VERSION "created by canmatrix"

NS_ :

BS_:

BU_: MGW FVC

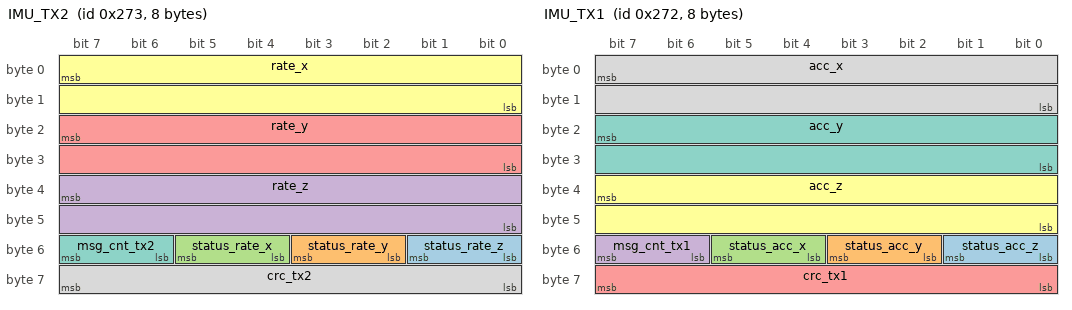
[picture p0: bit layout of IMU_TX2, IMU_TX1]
BO_ 627 IMU_TX2: 8 MGW
 SG_ status_rate_z : 49|2@0+ (1,0) [0|3] ""  FVC
 SG_ status_rate_y : 51|2@0+ (1,0) [0|3] ""  FVC
 SG_ status_rate_x : 53|2@0+ (1,0) [0|3] ""  FVC
 SG_ rate_z : 39|16@0- (0.01,0) [-327.68|327.67] "°/s"  FVC
 SG_ rate_y : 23|16@0- (0.01,0) [-327.68|327.67] "°/s"  FVC
 SG_ rate_x : 7|16@0- (0.01,0) [-327.68|327.67] "°/s"  FVC
 SG_ msg_cnt_tx2 : 55|2@0+ (1,0) [0|3] ""  FVC
 SG_ crc_tx2 : 63|8@0+ (1,0) [0|255] ""  FVC

BO_ 626 IMU_TX1: 8 MGW
 SG_ status_acc_z : 49|2@0+ (1,0) [0|3] ""  FVC
 SG_ status_acc_y : 51|2@0+ (1,0) [0|3] ""  FVC
 SG_ status_acc_x : 53|2@0+ (1,0) [0|3] ""  FVC
 SG_ msg_cnt_tx1 : 55|2@0+ (1,0) [0|3] ""  FVC
 SG_ crc_tx1 : 63|8@0+ (1,0) [0|255] ""  FVC
 SG_ acc_z : 39|16@0- (0.0002,0) [-6.5536|6.5534] "g"  FVC
 SG_ acc_y : 23|16@0- (0.0002,0) [-6.5536|6.5536] "g"  FVC
 SG_ acc_x : 7|16@0- (0.0002,0) [-6.5536|6.5534] "g"  FVC

BO_ 992 Commit_id: 8 FVC
 SG_ CommitShortId : 0|64@1+ (1,0) [0|1.84467440737096E+19] ""  MGW

BO_ 1983 DBC_Version: 2 MGW
 SG_ DBC_VersionIdMinor : 8|8@1+ (1,0) [0|255] ""  FVC
 SG_ DBC_VersionIdMajor : 0|8@1+ (1,0) [0|255] ""  FVC

BO_ 446 IPMA_UN_SP_GW_1: 8 FVC
 SG_ CameraStatus : 58|3@0+ (1,0) [0|7] ""  MGW

BO_ 18 ABS_UN_PR_11: 8 MGW
 SG_ ABSMode : 41|1@0+ (1,0) [0|1] ""  FVC
 SG_ DSCActivityStatus : 55|1@0+ (1,0) [0|1] ""  FVC
 SG_ TCSSwitchSports : 49|2@0+ (1,0) [0|3] ""  FVC
 SG_ TractionControlActive : 54|1@0+ (1,0) [0|1] ""  FVC
 SG_ TractionControlFault : 53|1@0+ (1,0) [0|1] ""  FVC
 SG_ YawControlFault : 51|1@0+ (1,0) [0|1] ""  FVC

BO_ 11 ABS_UN_PR_4: 8 MGW
 SG_ ABSFault : 36|1@0+ (1,0) [0|1] ""  FVC
 SG_ YawRate : 33|10@0+ (0.2,-100) [-100|100] "Degrees/second"  FVC

BO_ 264 ABS_UN_PR_6: 8 MGW
 SG_ GSAPosStatus : 43|4@0+ (1,0) [0|15] ""  FVC

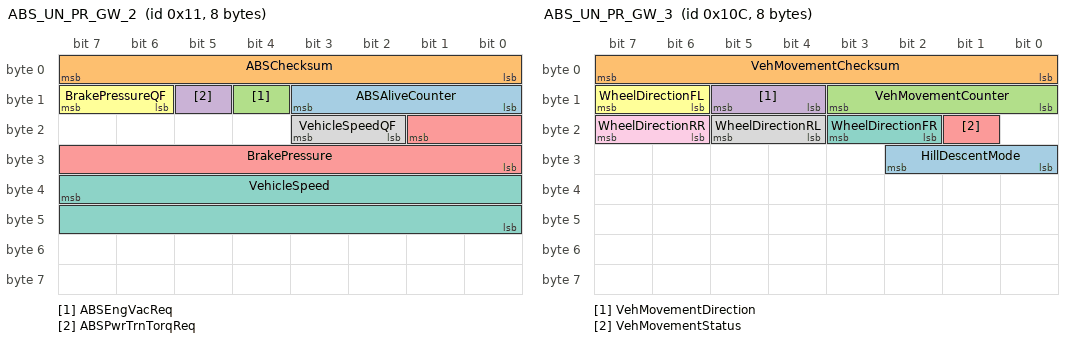
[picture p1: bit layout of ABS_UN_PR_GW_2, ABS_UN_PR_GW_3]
BO_ 17 ABS_UN_PR_GW_2: 8 MGW
 SG_ ABSAliveCounter : 11|4@0+ (1,0) [0|15] "Counter value"  FVC
 SG_ ABSChecksum : 7|8@0+ (1,0) [0|255] "checksum"  FVC
 SG_ ABSEngVacReq : 12|1@0+ (1,0) [0|1] ""  FVC
 SG_ ABSPwrTrnTorqReq : 13|1@0+ (1,0) [0|1] ""  FVC
 SG_ BrakePressure : 17|10@0+ (0.2,0) [0|204.6] "Bar"  FVC
 SG_ BrakePressureQF : 15|2@0+ (1,0) [0|3] ""  FVC
 SG_ VehicleSpeed : 39|16@0+ (0.01,0) [0|320] "kph"  FVC
 SG_ VehicleSpeedQF : 19|2@0+ (1,0) [0|3] ""  FVC

BO_ 268 ABS_UN_PR_GW_3: 8 MGW
 SG_ HillDescentMode : 26|3@0+ (1,0) [0|7] ""  FVC
 SG_ VehMovementChecksum : 7|8@0+ (1,0) [0|255] "checksum"  FVC
 SG_ VehMovementCounter : 11|4@0+ (1,0) [0|15] "Counter value"  FVC
 SG_ VehMovementDirection : 13|2@0+ (1,0) [0|3] ""  FVC
 SG_ VehMovementStatus : 17|1@0+ (1,0) [0|1] ""  FVC
 SG_ WheelDirectionFL : 15|2@0+ (1,0) [0|3] ""  FVC
 SG_ WheelDirectionFR : 19|2@0+ (1,0) [0|3] ""  FVC
 SG_ WheelDirectionRL : 21|2@0+ (1,0) [0|3] ""  FVC
 SG_ WheelDirectionRR : 23|2@0+ (1,0) [0|3] ""  FVC

BO_ 237 ABS_UN_PR_GW_5_1: 8 MGW
 SG_ WheelSpeedFrGpCounter : 11|4@0+ (1,0) [0|15] "Counter value"  FVC
 SG_ WheelSpeedFrGpCS : 7|8@0+ (1,0) [0|255] "checksum"  FVC
 SG_ WheelSpeedFrL : 22|15@0+ (0.01,0) [0|327.67] "km/h"  FVC
 SG_ WheelSpeedFrLQF : 15|2@0+ (1,0) [0|3] ""  FVC
 SG_ WheelSpeedFrR : 38|15@0+ (0.01,0) [0|327.67] "km/h"  FVC
 SG_ WheelSpeedFrRQF : 13|2@0+ (1,0) [0|3] ""  FVC

BO_ 240 ABS_UN_PR_GW_5_2: 8 MGW
 SG_ WheelSpeedReGpCounter : 11|4@0+ (1,0) [0|15] "Counter value"  FVC
 SG_ WheelSpeedReGpCS : 7|8@0+ (1,0) [0|255] "checksum"  FVC
 SG_ WheelSpeedReL : 22|15@0+ (0.01,0) [0|327.67] "km/h"  FVC
 SG_ WheelSpeedReLQF : 13|2@0+ (1,0) [0|3] ""  FVC
 SG_ WheelSpeedReR : 38|15@0+ (0.01,0) [0|327.67] "km/h"  FVC
 SG_ WheelSpeedReRQF : 15|2@0+ (1,0) [0|3] ""  FVC

BO_ 681 BCM_PR_GW_16_UN: 8 MGW
 SG_ UserSetTimeDate : 23|48@0+ (1,0) [0|281474976710655] ""  FVC

BO_ 255 BCM_PR_GW_1_UN: 8 MGW
 SG_ CarMode : 27|4@0+ (1,0) [0|15] ""  FVC
 SG_ DirectionIndicationSwitch : 47|3@0+ (1,0) [0|7] ""  FVC
 SG_ MainBeamIndication : 51|1@0+ (1,0) [0|1] ""  FVC
 SG_ PowerMode : 20|5@0+ (1,0) [0|31] ""  FVC
 SG_ PowerMode_UB : 34|1@0+ (1,0) [0|1] ""  FVC
 SG_ RunningStandby : 56|1@0+ (1,0) [0|1] ""  FVC

BO_ 230 BCM_SP_GW_2_UN: 8 MGW
 SG_ DirectionIndication : 60|2@0+ (1,0) [0|3] ""  FVC
 SG_ DirectionIndication_UB : 48|1@0+ (1,0) [0|1] ""  FVC
 SG_ LDWSwitchReq : 34|1@0+ (1,0) [0|1] ""  FVC
 SG_ LDWSwitchReq_UB : 35|1@0+ (1,0) [0|1] ""  FVC
 SG_ LowBeamIndication : 53|1@0+ (1,0) [0|1] ""  FVC
 SG_ LowBeamIndication_UB : 52|1@0+ (1,0) [0|1] ""  FVC

BO_ 270 CHCM_FR_PR_GW_2_UN: 8 MGW
 SG_ SuspensionHeightFL : 0|9@0+ (1,-200) [-200|300] "mm"  FVC
 SG_ SuspensionHeightFR : 16|9@0+ (1,-200) [-200|300] "mm"  FVC
 SG_ SuspensionHeightRL : 32|9@0+ (1,-200) [-200|300] "mm"  FVC
 SG_ SuspensionHeightRR : 48|9@0+ (1,-200) [-200|300] "mm"  FVC

BO_ 43 CHCM_FR_PR_GW_3_UN: 8 MGW
 SG_ AIR_ControlStatus : 63|2@0+ (1,0) [0|3] ""  FVC
 SG_ AIR_SuspensionMode : 61|3@0+ (1,0) [0|7] ""  FVC

BO_ 88 DADCA_FR_PR_GW_4_UN: 8 MGW
 SG_ TSRCountry : 31|7@0+ (1,0) [0|127] ""  FVC
 SG_ TSRHandOfTraffic : 45|2@0+ (1,0) [0|3] ""  FVC

BO_ 266 DADCA_UN_PR_3: 8 MGW
 SG_ DADCFuncStatus : 50|3@0+ (1,0) [0|7] ""  FVC

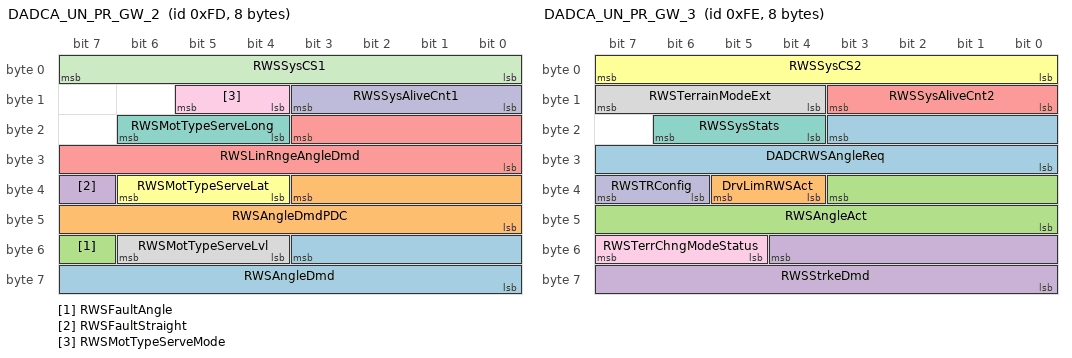
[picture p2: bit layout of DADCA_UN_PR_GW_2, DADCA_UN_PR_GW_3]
BO_ 253 DADCA_UN_PR_GW_2: 8 MGW
 SG_ RWSAngleDmd : 51|12@0+ (0.01,-15) [-15|15] "deg"  FVC
 SG_ RWSAngleDmdPDC : 35|12@0+ (0.01,-15) [-15|15] "deg"  FVC
 SG_ RWSFaultAngle : 55|1@0+ (1,0) [0|1] ""  FVC
 SG_ RWSFaultStraight : 39|1@0+ (1,0) [0|1] ""  FVC
 SG_ RWSLinRngeAngleDmd : 19|12@0+ (0.01,-15) [-15|15] "deg"  FVC
 SG_ RWSMotTypeServeLat : 38|3@0+ (1,0) [0|7] ""  FVC
 SG_ RWSMotTypeServeLong : 22|3@0+ (1,0) [0|7] ""  FVC
 SG_ RWSMotTypeServeLvl : 54|3@0+ (1,0) [0|7] ""  FVC
 SG_ RWSMotTypeServeMode : 13|2@0+ (1,0) [0|3] ""  FVC
 SG_ RWSSysAliveCnt1 : 11|4@0+ (1,0) [0|15] "Counter value"  FVC
 SG_ RWSSysCS1 : 7|8@0+ (1,0) [0|255] "checksum"  FVC

BO_ 254 DADCA_UN_PR_GW_3: 8 MGW
 SG_ DADCRWSAngleReq : 19|12@0+ (0.01,-15) [-15|15] "deg"  FVC
 SG_ DrvLimRWSAct : 37|2@0+ (1,0) [0|3] ""  FVC
 SG_ RWSAngleAct : 35|12@0+ (0.01,-15) [-15|15] "deg"  FVC
 SG_ RWSStrkeDmd : 52|13@0+ (0.01,-40) [-40|40] "mm"  FVC
 SG_ RWSSysAliveCnt2 : 11|4@0+ (1,0) [0|15] "Counter value"  FVC
 SG_ RWSSysCS2 : 7|8@0+ (1,0) [0|255] "checksum"  FVC
 SG_ RWSSysStats : 22|3@0+ (1,0) [0|7] ""  FVC
 SG_ RWSTerrainModeExt : 15|4@0+ (1,0) [0|15] ""  FVC
 SG_ RWSTerrChngModeStatus : 55|3@0+ (1,0) [0|7] ""  FVC
 SG_ RWSTRConfig : 39|2@0+ (1,0) [0|3] ""  FVC

BO_ 416 DADCA_UN_SP_5: 8 MGW
 SG_ CustomerSymptomIPMA : 48|1@0+ (1,0) [0|1] ""  FVC
 SG_ CustomerSymptomIPMA_UB : 49|1@0+ (1,0) [0|1] ""  FVC

BO_ 277 GWM_UN_PR_1: 8 MGW
 SG_ TerrainModeReqExt : 63|4@0+ (1,0) [0|15] ""  FVC

BO_ 104 HCMA_PR_1: 8 MGW
 SG_ HBSeg0LT : 57|2@0+ (1,0) [0|3] ""  FVC
 SG_ HBSeg0RT : 59|2@0+ (1,0) [0|3] ""  FVC
 SG_ HBSeg1LT : 61|2@0+ (1,0) [0|3] ""  FVC
 SG_ HBSeg1RT : 63|2@0+ (1,0) [0|3] ""  FVC
 SG_ HBSeg2LT : 49|2@0+ (1,0) [0|3] ""  FVC
 SG_ HBSeg2RT : 51|2@0+ (1,0) [0|3] ""  FVC
 SG_ HBSeg3LT : 53|2@0+ (1,0) [0|3] ""  FVC
 SG_ HBSeg3RT : 55|2@0+ (1,0) [0|3] ""  FVC
 SG_ HBSeg4LT : 41|2@0+ (1,0) [0|3] ""  FVC
 SG_ HBSeg4RT : 43|2@0+ (1,0) [0|3] ""  FVC
 SG_ HBSeg5LT : 45|2@0+ (1,0) [0|3] ""  FVC
 SG_ HBSeg5RT : 47|2@0+ (1,0) [0|3] ""  FVC
 SG_ HBSeg6LT : 33|2@0+ (1,0) [0|3] ""  FVC
 SG_ HBSeg6RT : 35|2@0+ (1,0) [0|3] ""  FVC
 SG_ HBSeg7LT : 37|2@0+ (1,0) [0|3] ""  FVC
 SG_ HBSeg7RT : 39|2@0+ (1,0) [0|3] ""  FVC
 SG_ HBSeg8LT : 25|2@0+ (1,0) [0|3] ""  FVC
 SG_ HBSeg8RT : 27|2@0+ (1,0) [0|3] ""  FVC
 SG_ HBSeg9LT : 29|2@0+ (1,0) [0|3] ""  FVC
 SG_ HBSeg9RT : 31|2@0+ (1,0) [0|3] ""  FVC
 SG_ HighBeamStatus : 19|4@0+ (1,0) [0|15] ""  FVC
 SG_ LowBeamStatus : 23|4@0+ (1,0) [0|15] ""  FVC

BO_ 106 HCMA_PR_2: 8 MGW
 SG_ ADBHorEdgeLT : 55|16@0+ (0.1,-30) [-30|30] "degrees"  FVC
 SG_ ADBHorEdgeRT : 39|16@0+ (0.1,-30) [-30|30] "degrees"  FVC
 SG_ LaserStatus : 27|4@0+ (1,0) [4|14] "unused"  FVC
 SG_ LBStatus : 31|4@0+ (1,0) [4|13] "Unused"  FVC
 SG_ LightDist : 19|4@0+ (1,0) [5|13] "Unused"  FVC

BO_ 301 HCMB_PR_1: 8 MGW
 SG_ AFSLightDist_b : 59|4@0+ (1,0) [0|15] ""  FVC
 SG_ AFSPHBAngleLT_b : 47|16@0+ (0.1,-30) [-30|10] "-ve left , +ve right"  FVC
 SG_ AFSPHBAngleRT_b : 31|16@0+ (0.1,-30) [-30|10] "-ve left , +ve right"  FVC
 SG_ AFSStatus_b : 63|4@0+ (1,0) [0|15] ""  FVC
 SG_ LaserStatus_b : 19|4@0+ (1,0) [0|15] ""  FVC

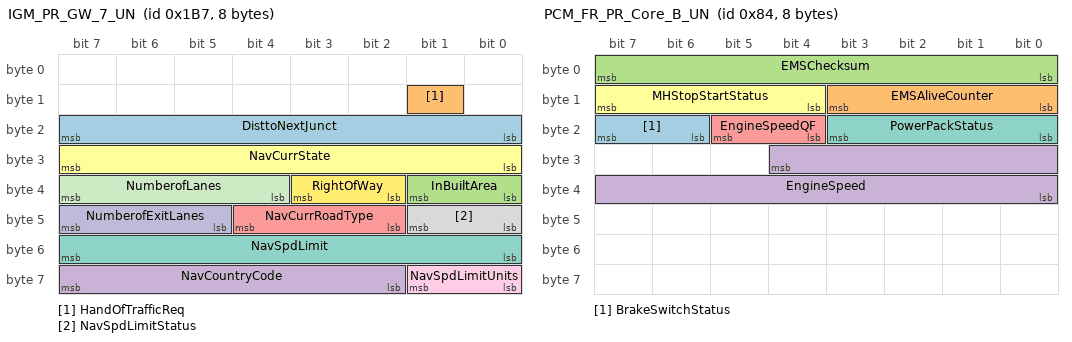
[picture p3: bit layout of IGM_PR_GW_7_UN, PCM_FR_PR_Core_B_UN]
BO_ 439 IGM_PR_GW_7_UN: 8 MGW
 SG_ DisttoNextJunct : 23|8@0+ (0.1,0) [0.1|25.4] ""  FVC
 SG_ HandOfTrafficReq : 9|1@0+ (1,0) [0|1] ""  FVC
 SG_ InBuiltArea : 33|2@0+ (1,0) [0|3] ""  FVC
 SG_ NavCountryCode : 63|6@0+ (1,0) [52|62] "Reserved"  FVC
 SG_ NavCurrRoadType : 44|3@0+ (1,0) [6|7] "Not used"  FVC
 SG_ NavCurrState : 31|8@0+ (1,0) [77|255] "Not used"  FVC
 SG_ NavSpdLimit : 55|8@0+ (1,0) [0|254] "Speed Value"  FVC
 SG_ NavSpdLimitStatus : 41|2@0+ (1,0) [0|3] ""  FVC
 SG_ NavSpdLimitUnits : 57|2@0+ (1,0) [0|3] ""  FVC
 SG_ NumberofExitLanes : 47|3@0+ (1,0) [1|7] "Number of lanes"  FVC
 SG_ NumberofLanes : 39|4@0+ (1,0) [1|15] "Number of lanes"  FVC
 SG_ RightOfWay : 35|2@0+ (1,0) [0|3] ""  FVC

BO_ 186 IGM_SP_GW_10_UN: 8 MGW
 SG_ AutoHighBeamSAEModeReq : 51|2@0+ (1,0) [0|3] ""  FVC
 SG_ AutoHighBeamSAEModeReq_UB : 57|1@0+ (1,0) [0|1] ""  FVC

BO_ 318 IPC_PR_GW_5_UN: 8 MGW
 SG_ IPCAliveCnt : 11|4@0+ (1,0) [0|15] "Counter"  FVC

BO_ 515 LHSWS_PR_GW_1_UN: 8 MGW
 SG_ JoypadDownBtnStatus : 63|4@0+ (1,0) [0|15] "Rolling Count (See Encoding Desc"  FVC
 SG_ JoypadLeftBtnStatus : 59|4@0+ (1,0) [0|15] "Rolling Count (See Encoding Desc"  FVC
 SG_ JoypadOKBtnStatus : 55|4@0+ (1,0) [0|15] "Rolling Count (See Encoding Desc"  FVC
 SG_ JoypadRightBtnStatus : 51|4@0+ (1,0) [0|15] "Rolling Count (See Encoding Desc"  FVC
 SG_ JoypadUpBtnStatus : 43|4@0+ (1,0) [0|15] "Rolling Count (See Encoding Desc"  FVC

BO_ 132 PCM_FR_PR_Core_B_UN: 8 MGW
 SG_ BrakeSwitchStatus : 23|2@0+ (1,0) [0|3] ""  FVC
 SG_ EMSAliveCounter : 11|4@0+ (1,0) [0|15] "Counter value"  FVC
 SG_ EMSChecksum : 7|8@0+ (1,0) [0|255] "checksum"  FVC
 SG_ EngineSpeed : 28|13@0+ (1,0) [0|8191] "RPM"  FVC
 SG_ EngineSpeedQF : 21|2@0+ (1,0) [0|3] ""  FVC
 SG_ MHStopStartStatus : 15|4@0+ (1,0) [0|15] ""  FVC
 SG_ PowerPackStatus : 19|4@0+ (1,0) [0|15] ""  FVC

BO_ 54 PCM_FR_PR_PedalPos_UN: 8 MGW
 SG_ PedalPosPro : 23|8@0+ (0.5,0) [0|100] "%"  FVC
 SG_ PedalPosProAliveCounter : 11|4@0+ (1,0) [0|15] "Counter value"  FVC
 SG_ PedalPosProChecksum : 7|8@0+ (1,0) [0|255] "checksum"  FVC
 SG_ PedalPosProQF : 13|2@0+ (1,0) [0|3] ""  FVC

BO_ 13 PCM_FR_PR_WhlTorqTgt_UN: 8 MGW
 SG_ VSCHoldRequest : 21|1@0+ (1,0) [0|1] ""  FVC
 SG_ WheelTorqTgtGpCounter : 11|4@0+ (1,0) [0|15] "Counter value"  FVC
 SG_ WheelTorqTgtGpCS : 7|8@0+ (1,0) [0|255] "checksum"  FVC
 SG_ WheelTorqTgtWoIntF : 20|13@0+ (10,-10000) [-10000|71910] "Nm"  FVC
 SG_ WheelTorqTgtWoIntR : 36|13@0+ (10,-10000) [-10000|71910] "Nm"  FVC

BO_ 46 PSCM_FR_PR_GW_1_UN: 4 MGW
 SG_ EPASDrvDmdExcess_dup : 15|1@0+ (1,0) [0|1] ""  FVC
 SG_ TorsionBarTorque : 17|10@0+ (0.02,0) [0|20.44] "0-3FCh :0..+20.40 Nm, E=N*0.02+0"  FVC
 SG_ TorsionBarTorqueCS : 7|8@0+ (1,0) [0|255] "checksum"  FVC
 SG_ TorsionBarTorqueCtr : 11|4@0+ (1,0) [0|15] "Counter value"  FVC
 SG_ TorsionBarTorqueQF : 13|2@0+ (1,0) [0|3] ""  FVC
 SG_ TorsionBarTorqueSign : 14|1@0+ (1,0) [0|1] ""  FVC

BO_ 50 PSCM_FR_PR_GW_2_UN: 8 MGW
 SG_ ActRoadWheelAngleAC : 11|4@0+ (1,0) [0|15] "Counter value"  FVC
 SG_ ActRoadWheelAngleCS : 7|8@0+ (1,0) [0|255] "checksum"  FVC
 SG_ ActRoadWheelAngState : 15|2@0+ (1,0) [0|3] ""  FVC
 SG_ ActRoadWheelAngValue : 22|15@0+ (0.005,-45) [-45|45] "Degrees"  FVC

BO_ 191 RCM_FR_PR_GW_1_UN: 8 MGW
 SG_ DrivSeatBeltBcklError : 30|1@0+ (1,0) [0|1] ""  FVC
 SG_ DrivSeatBeltBcklState : 31|1@0+ (1,0) [0|1] ""  FVC

BO_ 74 RCM_FR_PR_TXID1_UN: 8 MGW
 SG_ A1 : 39|16@0+ (0.00125,-40.96) [-40.96|40.9575] "m/s2"  FVC
 SG_ A1_STAT : 31|4@0+ (1,0) [0|15] ""  FVC
 SG_ CLU_STAT : 27|4@0+ (1,0) [0|15] ""  FVC
 SG_ CRC1 : 7|8@0+ (1,0) [0|255] "checksum"  FVC
 SG_ MSG_CNT1 : 11|4@0+ (1,0) [0|15] "Counter value"  FVC
 SG_ PSIP1 : 55|16@0+ (0.005,-163.84) [-163.84|163.83] "Grad/s"  FVC
 SG_ PSIP1_STAT : 15|4@0+ (1,0) [0|15] ""  FVC

BO_ 76 RCM_FR_PR_TXID2_UN: 8 MGW
 SG_ A2 : 39|16@0+ (0.00125,-40.96) [-40.96|40.9575] "m/s2"  FVC
 SG_ A2_STAT : 31|4@0+ (1,0) [0|15] ""  FVC
 SG_ CRC2 : 7|8@0+ (1,0) [0|255] "checksum"  FVC
 SG_ MSG_CNT2 : 11|4@0+ (1,0) [0|15] "Counter value"  FVC
 SG_ PSIPP1 : 55|16@0+ (0.125,-4096) [-4096|4095.75] "Grad/s/s"  FVC
 SG_ PSIPP1_STAT : 27|4@0+ (1,0) [0|15] ""  FVC

BO_ 86 SASM_FR_GW_1_UN: 8 MGW
 SG_ SteeringWheelAngle : 31|16@0+ (0.1,-780) [-780|780] "Degrees"  FVC
 SG_ SteeringWheelAngleCS : 7|8@0+ (1,0) [0|255] "checksum"  FVC
 SG_ SteeringWheelAngleSpeed : 47|8@0+ (4,0) [0|1016] "Rotational Speed (deg/sec)"  FVC
 SG_ SteeringWheelAngleStatus : 17|2@0+ (1,0) [0|3] ""  FVC
 SG_ SteeringWheelAngMsgCnt : 11|4@0+ (1,0) [0|15] "Counter value"  FVC
 SG_ SteeringWheelRotDir : 18|1@0+ (1,0) [0|1] ""  FVC

BO_ 397 SignalGW_PR_1_UN: 8 MGW
 SG_ DemandHeight : 32|9@0+ (1,-200) [-200|300] "mm"  FVC
 SG_ EstimatedHeight : 48|9@0+ (1,-200) [-200|300] "mm"  FVC
 SG_ THETAP : 7|16@0+ (0.005,-163.84) [-163.84|163.83] "Grad/s"  FVC

BO_ 399 SignalGW_PR_3_UN: 8 MGW
 SG_ CountryCode : 23|16@0+ (1,0) [0|65535] "n/a"  FVC
 SG_ VCGStatus : 47|1@0+ (1,0) [0|1] ""  FVC

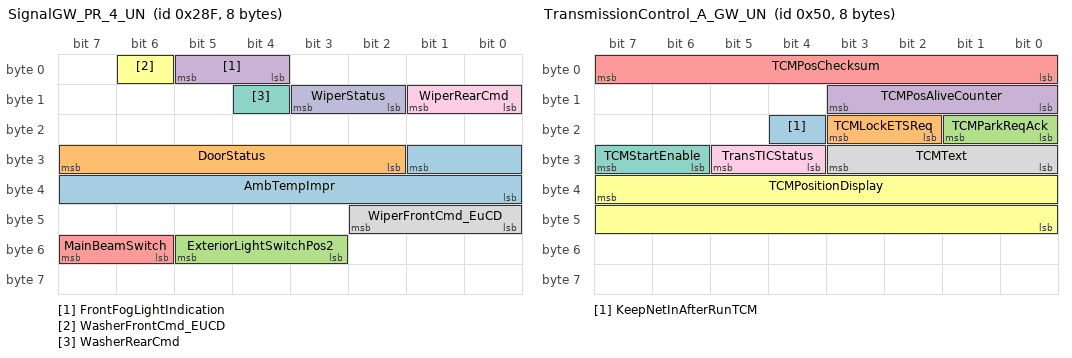
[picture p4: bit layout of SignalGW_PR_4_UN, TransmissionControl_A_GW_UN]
BO_ 655 SignalGW_PR_4_UN: 8 MGW
 SG_ AmbTempImpr : 25|10@0+ (0.25,-128) [-128|127.75] "Degrees C"  FVC
 SG_ DoorStatus : 31|6@0+ (1,0) [0|63] "See Description"  FVC
 SG_ ExteriorLightSwitchPos2 : 53|3@0+ (1,0) [5|7] "Unsed"  FVC
 SG_ FrontFogLightIndication : 5|2@0+ (1,0) [0|3] ""  FVC
 SG_ MainBeamSwitch : 55|2@0+ (1,0) [0|3] ""  FVC
 SG_ WasherFrontCmd_EUCD : 6|1@0+ (1,0) [0|1] ""  FVC
 SG_ WasherRearCmd : 12|1@0+ (1,0) [0|1] ""  FVC
 SG_ WiperFrontCmd_EuCD : 42|3@0+ (1,0) [0|7] ""  FVC
 SG_ WiperRearCmd : 9|2@0+ (1,0) [0|3] ""  FVC
 SG_ WiperStatus : 11|2@0+ (1,0) [0|3] ""  FVC

BO_ 245 SignalGW_PR_6_UN: 8 MGW
 SG_ ATPCProStatus : 27|4@0+ (1,0) [0|15] ""  FVC

BO_ 836 TPM_PR_GW_4: 8 MGW
 SG_ ActualTyrePressureFL : 23|8@0+ (2.745098,0) [0|699.99999] "kPa"  FVC
 SG_ ActualTyrePressureFR : 31|8@0+ (2.745098,0) [0|699.99999] "kPa"  FVC
 SG_ ActualTyrePressureRL : 39|8@0+ (2.745098,0) [0|699.99999] "kPa"  FVC
 SG_ ActualTyrePressureRR : 47|8@0+ (2.745098,0) [0|699.99999] "kPa"  FVC

BO_ 80 TransmissionControl_A_GW_UN: 8 MGW
 SG_ KeepNetInAfterRunTCM : 20|1@0+ (1,0) [0|1] ""  FVC
 SG_ TCMLockETSReq : 19|2@0+ (1,0) [0|3] ""  FVC
 SG_ TCMParkReqAck : 17|2@0+ (1,0) [0|3] ""  FVC
 SG_ TCMPosAliveCounter : 11|4@0+ (1,0) [0|15] "Counter value"  FVC
 SG_ TCMPosChecksum : 7|8@0+ (1,0) [0|255] "checksum"  FVC
 SG_ TCMPositionDisplay : 39|16@0+ (1,0) [0|65535] ""  FVC
 SG_ TCMStartEnable : 31|2@0+ (1,0) [0|3] ""  FVC
 SG_ TCMText : 27|4@0+ (1,0) [0|15] ""  FVC
 SG_ TransTICStatus : 29|2@0+ (1,0) [0|3] ""  FVC

BO_ 1024 VEHCONFIG_400UN_AS: 8 MGW
 SG_ CcfAdasNCapESS m101 : 61|2@0+ (1,0) [0|3] ""  FVC
 SG_ CcfParkAssistHMI m94 : 63|3@0+ (1,0) [0|7] ""  FVC
 SG_ CcfAdaptDrvBeam m91 : 51|2@0+ (1,0) [0|3] ""  FVC
 SG_ CcfDD06PowerModePKT m176 : 52|5@0+ (1,0) [0|31] ""  FVC
 SG_ CcfAllWheelSteer m112 : 55|2@0+ (1,0) [0|3] ""  FVC
 SG_ CcfDD05OutdoorTemp m177 : 47|8@0+ (1,-40) [-40|215] "Deg C"  FVC
 SG_ CcfDD02MainECUSupVolts m176 : 47|8@0+ (0.25,0) [0|63.75] "Volts"  FVC
 SG_ CcfDD04InCarTemp m177 : 39|8@0+ (1,-40) [-40|215] "Deg C"  FVC
 SG_ CcfAdapDrvBeamSeg m101 : 39|8@0+ (1,0) [0|255] ""  FVC
 SG_ CcfVINPart1 m87 : 39|32@0+ (1,0) [0|4294967295] ""  FVC
 SG_ ccfGenericWheelBase m87 : 31|4@0+ (1,0) [0|15] ""  FVC
 SG_ CcfSportbrake m85 : 31|2@0+ (1,0) [0|3] ""  FVC
 SG_ CcfSuspensionType m98 : 19|4@0+ (1,0) [0|15] ""  FVC
 SG_ CcfVehClearGuidance m115 : 23|2@0+ (1,0) [0|3] ""  FVC
 SG_ CcfAHBSensitivtyMenu m110 : 23|2@0+ (1,0) [0|3] ""  FVC
 SG_ CcfAHBCalibration m109 : 23|3@0+ (1,0) [0|7] ""  FVC
 SG_ CcfGlassType m10 : 23|8@0+ (1,0) [0|255] ""  FVC
 SG_ CcfHeatedWindscreen m9 : 23|8@0+ (1,0) [0|255] ""  FVC
 SG_ CcfHUDSubType m96 : 13|3@0+ (1,0) [0|7] ""  FVC
 SG_ CcfDD01TotalDistance m177 : 15|24@0+ (1,0) [0|16777215] ""  FVC
 SG_ CcfDD00GlobalRealTime m176 : 15|32@0+ (1,0) [0|4294967295] ""  FVC
 SG_ CcfAHBSystemStatus m108 : 15|2@0+ (1,0) [0|3] ""  FVC
 SG_ CcfVINPart3 m89 : 15|48@0+ (1,0) [0|281474976710655] ""  FVC
 SG_ CcfVINPart2 m88 : 15|56@0+ (1,0) [0|7.20575940379279E+16] ""  FVC
 SG_ CcfSteeringWheelPosn m2 : 15|8@0+ (1,0) [0|255] ""  FVC
 SG_ CcfVehicleType m1 : 15|8@0+ (1,0) [0|255] ""  FVC
 SG_ SF_VEHCONFIG_400UN_AUTOSAR_PDU M : 0|8@1+ (1,0) [0|255] ""  FVC

BO_ 1025 Snapshot_Data: 8 MGW
 SG_ Snapshot_Data_PDU_0 M : 7|8@0+ (1,0) [0|255] ""  FVC
 SG_ OutdoorTemp m1 : 47|8@0+ (1,-40) [-40|215] ""  FVC
 SG_ InCarTemp m1 : 39|8@0+ (1,-40) [-40|215] ""  FVC
 SG_ TotalDistance m1 : 15|24@0+ (1,0) [0|16777215] ""  FVC
 SG_ PowrModePKT m0 : 52|5@0+ (1,0) [0|31] ""  FVC
 SG_ MainECUSuppVolt m0 : 47|8@0+ (0.25,0) [0|63.75] ""  FVC
 SG_ GlobalRealTime m0 : 15|32@0+ (1,0) [0|4294967295] ""  FVC

BO_ 321 Vehicle_CAN_41: 8 MGW
 SG_ ADAS_Stub_PartOfCalcRoute : 47|2@0+ (1,0) [0|3] ""  FVC
 SG_ ADAS_Stub_FuncRoadClass : 34|3@0+ (1,0) [0|6] ""  FVC
 SG_ ADAS_Stub_LastStub : 63|1@0+ (1,0) [0|1] ""  FVC
 SG_ ADAS_Stub_Update : 24|1@0+ (1,0) [0|1] ""  FVC
 SG_ ADAS_Stub_SubPathIdx : 31|6@0+ (1,0) [8|63] ""  FVC
 SG_ ADAS_Stub_Retr : 25|1@0+ (1,0) [0|1] ""  FVC
 SG_ ADAS_Stub_PathIdx : 21|6@0+ (1,0) [8|63] ""  FVC
 SG_ ADAS_Stub_Offset : 4|13@0+ (1,0) [0|8190] "m"  FVC
 SG_ ADAS_Stub_NumOfLaneOppDir : 60|2@0+ (1,0) [0|3] ""  FVC
 SG_ ADAS_Stub_NumOfLaneDrvDir : 58|3@0+ (1,0) [0|7] ""  FVC
 SG_ ADAS_Stub_MsgType : 7|3@0+ (1,0) [0|7] ""  FVC
 SG_ ADAS_Stub_FormOfWay : 43|4@0+ (1,0) [0|14] ""  FVC
 SG_ ADAS_Stub_CycCnt : 23|2@0+ (1,0) [0|3] ""  FVC
 SG_ ADAS_Stub_RtOfWay : 62|2@0+ (1,0) [0|3] ""  FVC
 SG_ ADAS_Stub_CmplxInsct : 45|2@0+ (1,0) [0|3] ""  FVC
 SG_ ADAS_Stub_RelProbb : 39|5@0+ (3.333,0) [0|100] "%"  FVC
 SG_ ADAS_Stub_TurnAngl : 55|8@0+ (1.417,0) [0|358] "deg"  FVC

BO_ 340 ACC_01: 8 MGW
 SG_ AxrArbitrated : 6|9@0+ (0.024,-2.016) [-2.016|10.224] "m/s²"  FVC
 SG_ ESP_NotAvailable : 7|1@0+ (1,0) [0|1] ""  FVC

BO_ 3 GSR_ISA_CAN_TX_01: 8 FVC
 SG_ ISA_OperationState : 7|2@0+ (1,0) [0|3] ""  MGW
 SG_ ISA_SetWarningType : 5|3@0+ (1,0) [0|7] ""  MGW
 SG_ ISA_ActiveWarningType : 2|3@0+ (1,0) [0|7] ""  MGW
 SG_ ISA_SpeedLimitDeterminationState : 10|2@0+ (1,0) [0|3] ""  MGW
 SG_ ISA_SpeedLimitChangeNotification : 11|1@0+ (1,0) [0|1] ""  MGW

BO_ 2 GSR_ISA_CAN_RX_01: 8 MGW
 SG_ ISA_OUTPUT_ENABLED : 1|1@0+ (1,0) [0|1] ""  FVC
 SG_ ISA_SLWF_OUTPUT_ENABLED : 2|1@0+ (1,0) [0|1] ""  FVC
 SG_ ISA_SLWF_TYPE : 5|3@0+ (1,0) [0|7] ""  FVC
 SG_ ISA_USER_TERMINATION : 6|1@0+ (1,0) [0|1] ""  FVC
 SG_ ISA_SL_CHNG_AUDIO_FEEDBACK : 7|1@0+ (1,0) [0|1] ""  FVC

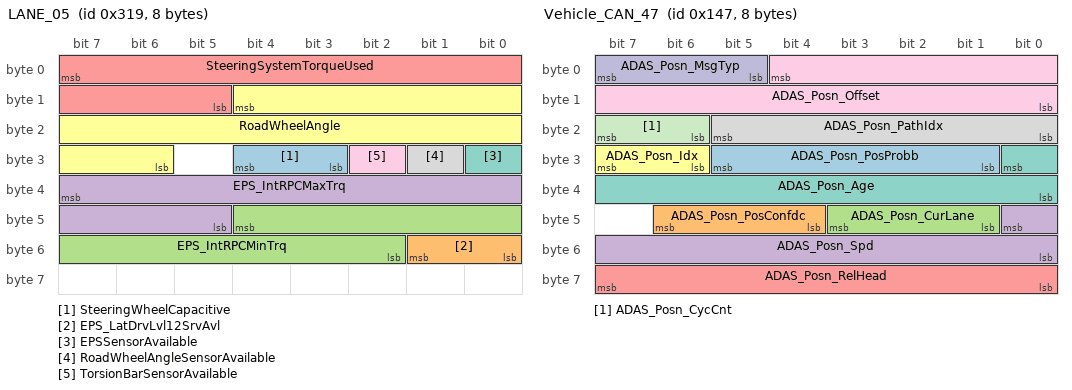
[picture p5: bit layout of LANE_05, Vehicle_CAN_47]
BO_ 793 LANE_05: 8 MGW
 SG_ SteeringWheelCapacitive : 28|2@0+ (1,0) [0|3] ""  FVC
 SG_ EPS_LatDrvLvl12SrvAvl : 49|2@0+ (1,0) [0|3] ""  FVC
 SG_ EPS_IntRPCMinTrq : 44|11@0+ (0.02,-20.48) [-20.48|20.46] "Nm"  FVC
 SG_ EPS_IntRPCMaxTrq : 39|11@0+ (0.02,-20.48) [-20.48|20.46] "Nm"  FVC
 SG_ SteeringSystemTorqueUsed : 7|11@0+ (0.01,-8) [-8|12.47] "N/m"  FVC
 SG_ RoadWheelAngle : 12|15@0+ (0.005,-81.92) [-81.92|81.915] "degree"  FVC
 SG_ EPSSensorAvailable : 24|1@0+ (1,0) [0|1] ""  FVC
 SG_ RoadWheelAngleSensorAvailable : 25|1@0+ (1,0) [0|1] ""  FVC
 SG_ TorsionBarSensorAvailable : 26|1@0+ (1,0) [0|1] ""  FVC

BO_ 323 Vehicle_CAN_43: 8 MGW
 SG_ ADAS_Seg_PartOfCalcRoute : 47|2@0+ (1,0) [0|3] ""  FVC
 SG_ ADAS_Seg_RelProbb : 39|5@0+ (3.333,0) [0|100] "%"  FVC
 SG_ ADAS_Seg_Offset : 4|13@0+ (1,0) [0|8190] "m"  FVC
 SG_ ADAS_Seg_Retr : 25|1@0+ (1,0) [0|1] ""  FVC
 SG_ ADAS_Seg_PathIdx : 21|6@0+ (1,0) [8|63] ""  FVC
 SG_ ADAS_Seg_MsgType : 7|3@0+ (1,0) [0|7] ""  FVC
 SG_ ADAS_Seg_FormOfWay : 43|4@0+ (1,0) [0|14] ""  FVC
 SG_ ADAS_Seg_CycCnt : 23|2@0+ (1,0) [0|3] ""  FVC
 SG_ ADAS_Seg_CmplxInsct : 45|2@0+ (1,0) [0|3] ""  FVC
 SG_ ADAS_Seg_BuildUpArea : 27|2@0+ (1,0) [0|3] ""  FVC
 SG_ ADAS_Seg_DividedRoad : 62|2@0+ (1,0) [0|3] ""  FVC
 SG_ ADAS_Seg_Bridge : 29|2@0+ (1,0) [0|3] ""  FVC
 SG_ ADAS_Seg_Tunnel : 31|2@0+ (1,0) [0|3] ""  FVC
 SG_ ADAS_Seg_NumOfLaneOppDir : 60|2@0+ (1,0) [0|3] ""  FVC
 SG_ ADAS_Seg_NumOfLaneDrvDir : 58|3@0+ (1,0) [0|7] ""  FVC
 SG_ ADAS_Seg_EffSpdLmtType : 50|3@0+ (1,0) [0|7] ""  FVC
 SG_ ADAS_Seg_EffSpdLmt : 55|5@0+ (1,0) [0|0] "(k)mp/h"  FVC
 SG_ ADAS_Seg_FuncRoadClass : 34|3@0+ (1,0) [0|6] ""  FVC
 SG_ ADAS_Seg_Update : 24|1@0+ (1,0) [0|1] ""  FVC

BO_ 289 Vehicle_CAN_21: 8 MGW
 SG_ AirbagCrashIntensity : 47|2@0+ (1,0) [0|3] ""  FVC
 SG_ ASR_Intervention : 55|1@0+ (1,0) [0|1] ""  FVC
 SG_ BrakePressure_Qbit : 38|1@0+ (1,0) [0|1] ""  FVC
 SG_ BrakeTemperatureStatus : 48|1@0+ (1,0) [0|1] ""  FVC
 SG_ ClutchPedal : 39|1@0+ (1,0) [0|1] ""  FVC
 SG_ ClutchTemperatureStatus : 45|2@0+ (1,0) [0|3] ""  FVC
 SG_ DecelerationEnable : 51|1@0+ (1,0) [0|1] ""  FVC
 SG_ DriverBraked_Qbit : 37|1@0+ (1,0) [0|1] ""  FVC
 SG_ EBV_Intervention : 53|1@0+ (1,0) [0|1] ""  FVC
 SG_ ECD_Failure : 50|1@0+ (1,0) [0|1] ""  FVC
 SG_ ECD_NotAvailable : 49|1@0+ (1,0) [0|1] ""  FVC
 SG_ EDS_Intervention : 54|1@0+ (1,0) [0|1] ""  FVC
 SG_ EmergencyBrakeActive : 43|1@0+ (1,0) [0|1] ""  FVC
 SG_ ESP_AutoholdActive : 42|1@0+ (1,0) [0|1] ""  FVC
 SG_ ESP_ConsistentWithACC : 32|1@0+ (1,0) [0|1] ""  FVC
 SG_ ESP_StandstillConfirmed : 41|1@0+ (1,0) [0|1] ""  FVC
 SG_ ESP_StoppingProcessActive : 40|1@0+ (1,0) [0|1] ""  FVC
 SG_ MSR_Intervention : 52|1@0+ (1,0) [0|1] ""  FVC
 SG_ NumberOfCogs : 31|8@0+ (1,0) [0|255] ""  FVC
 SG_ SteeringAngularSpeed_Qbit : 34|1@0+ (1,0) [0|1] ""  FVC
 SG_ SteeringWheelAngle_Qbit : 35|1@0+ (1,0) [0|1] ""  FVC
 SG_ Vehicle_CAN_21_Counter : 15|4@0+ (1,0) [0|15] ""  FVC
 SG_ Vehicle_CAN_21_CRC : 7|8@0+ (1,0) [0|255] ""  FVC
 SG_ Velocity_Qbit : 36|1@0+ (1,0) [0|1] ""  FVC
 SG_ WheelCircumference : 11|12@0+ (1,0) [0|4095] ""  FVC
 SG_ WheelCircumference_QBit : 33|1@0+ (1,0) [0|1] ""  FVC
 SG_ TSRFeatureEnableSwitch : 63|8@0+ (1,0) [0|255] ""  FVC

BO_ 327 Vehicle_CAN_47: 8 MGW
 SG_ ADAS_Posn_PosProbb : 29|5@0+ (3.333,0) [0|100] "%"  FVC
 SG_ ADAS_Posn_PosConfdc : 46|3@0+ (1,0) [0|7] ""  FVC
 SG_ ADAS_Posn_CurLane : 43|3@0+ (1,0) [0|7] ""  FVC
 SG_ ADAS_Posn_Spd : 40|9@0+ (0.2,-12.8) [-12.8|89.2] "m/s"  FVC
 SG_ ADAS_Posn_RelHead : 63|8@0+ (1.417,0) [0|358] "deg"  FVC
 SG_ ADAS_Posn_Idx : 31|2@0+ (1,0) [0|3] ""  FVC
 SG_ ADAS_Posn_Age : 24|9@0+ (5,0) [0|2545] "ms"  FVC
 SG_ ADAS_Posn_PathIdx : 21|6@0+ (1,0) [8|63] ""  FVC
 SG_ ADAS_Posn_Offset : 4|13@0+ (1,0) [0|8190] "m"  FVC
 SG_ ADAS_Posn_MsgTyp : 7|3@0+ (1,0) [0|7] ""  FVC
 SG_ ADAS_Posn_CycCnt : 23|2@0+ (1,0) [0|3] ""  FVC

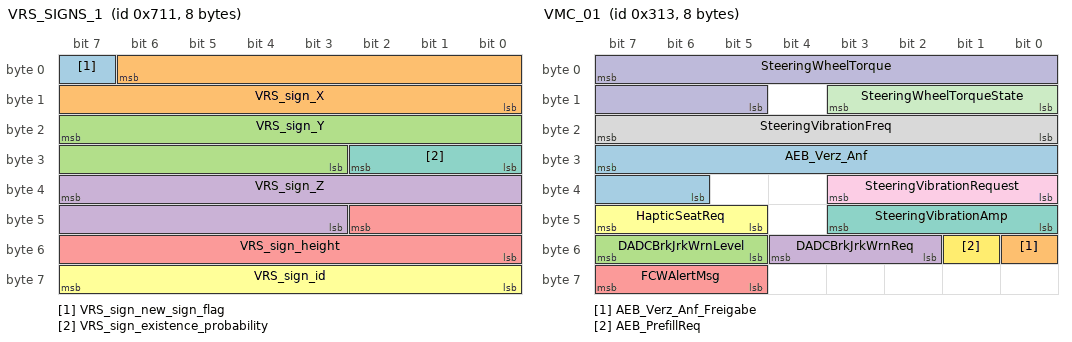
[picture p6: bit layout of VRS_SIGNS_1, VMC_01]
BO_ 1809 VRS_SIGNS_1: 8 FVC
 SG_ VRS_sign_new_sign_flag : 7|1@0+ (1,0) [0|1] ""  MGW
 SG_ VRS_sign_X : 6|15@0+ (1,0) [0|32767] "cm"  MGW
 SG_ VRS_sign_Y : 23|13@0+ (1,0) [0|8191] "cm"  MGW
 SG_ VRS_sign_Z : 39|13@0+ (1,0) [0|8191] "cm"  MGW
 SG_ VRS_sign_height : 42|11@0+ (1,0) [0|2047] ""  MGW
 SG_ VRS_sign_id : 63|8@0+ (1,0) [0|255] ""  MGW
 SG_ VRS_sign_existence_probability : 26|3@0+ (1,0) [0|7] ""  MGW

BO_ 328 Vehicle_CAN_48: 8 MGW
 SG_ isYawRate_Pf : 7|16@0+ (0.005,-163.84) [-163.84|163.835] "deg/s"  FVC
 SG_ isPitchRate : 31|16@0+ (0.005,-163.84) [-163.84|163.835] "deg/s"  FVC
 SG_ YawRate_Qbit : 16|1@0+ (1,0) [0|1] ""  FVC
 SG_ RoadWheelAngleGradients : 40|16@0+ (3.05185094759972E-05,0) [0|2.00003051850948] "rad/sec"  FVC

BO_ 787 VMC_01: 8 FVC
 SG_ AEB_Verz_Anf : 31|10@0+ (0.024,-20.016) [-20.016|4.536] "ms²"  MGW
 SG_ AEB_Verz_Anf_Freigabe : 48|1@0+ (1,0) [0|1] ""  MGW
 SG_ DADCBrkJrkWrnLevel : 55|3@0+ (1,0) [0|7] ""  MGW
 SG_ DADCBrkJrkWrnReq : 52|3@0+ (1,0) [0|7] ""  MGW
 SG_ FCWAlertMsg : 63|3@0+ (1,0) [0|7] ""  MGW
 SG_ HapticSeatReq : 47|3@0+ (1,0) [0|7] ""  MGW
 SG_ SteeringVibrationAmp : 43|4@0+ (0.2,0) [0|3] "Nm"  MGW
 SG_ SteeringVibrationFreq : 23|8@0+ (1,0) [0|30] "Hz"  MGW
 SG_ SteeringVibrationRequest : 35|4@0+ (1,0) [0|15] ""  MGW
 SG_ SteeringWheelTorque : 7|11@0+ (0.02,-20.48) [-20.48|20.48] "Nm"  MGW
 SG_ SteeringWheelTorqueState : 11|4@0+ (1,0) [0|15] ""  MGW
 SG_ AEB_PrefillReq : 49|1@0+ (1,0) [0|1] ""  MGW

BO_ 1810 VRS_SIGNS_2: 8 FVC
 SG_ VRS_sign_meaning : 7|9@0+ (1,0) [0|511] ""  MGW
 SG_ VRS_sign_width : 14|13@0+ (1,0) [0|8191] ""  MGW
 SG_ VRS_padding_2bit : 17|2@0+ (1,0) [0|3] ""  MGW

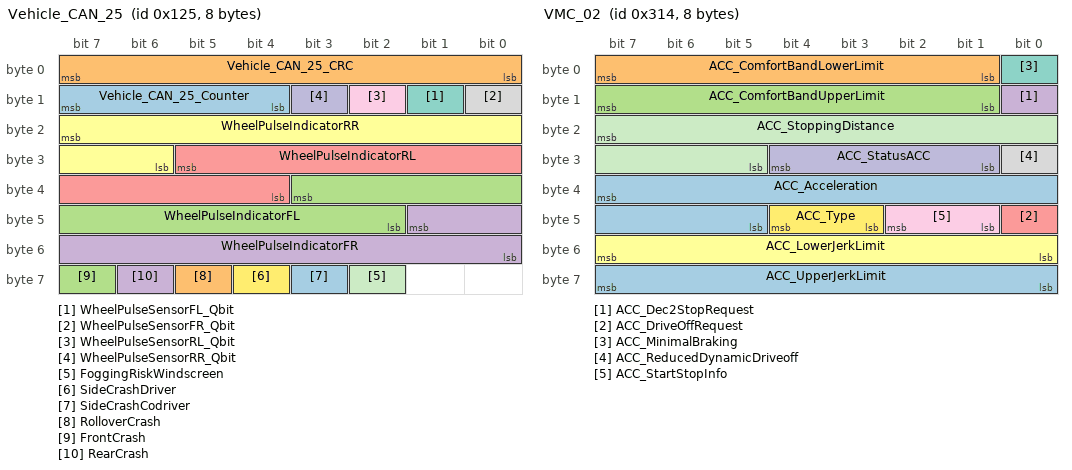
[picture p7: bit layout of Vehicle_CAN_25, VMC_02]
BO_ 293 Vehicle_CAN_25: 8 MGW
 SG_ Vehicle_CAN_25_Counter : 15|4@0+ (1,0) [0|15] ""  FVC
 SG_ Vehicle_CAN_25_CRC : 7|8@0+ (1,0) [0|255] ""  FVC
 SG_ WheelPulseIndicatorFL : 35|10@0+ (1,0) [0|1023] ""  FVC
 SG_ WheelPulseIndicatorFR : 41|10@0+ (1,0) [0|1023] ""  FVC
 SG_ WheelPulseIndicatorRL : 29|10@0+ (1,0) [0|1023] ""  FVC
 SG_ WheelPulseIndicatorRR : 23|10@0+ (1,0) [0|1023] ""  FVC
 SG_ WheelPulseSensorFL_Qbit : 9|1@0+ (1,0) [0|1] ""  FVC
 SG_ WheelPulseSensorFR_Qbit : 8|1@0+ (1,0) [0|1] ""  FVC
 SG_ WheelPulseSensorRL_Qbit : 10|1@0+ (1,0) [0|1] ""  FVC
 SG_ WheelPulseSensorRR_Qbit : 11|1@0+ (1,0) [0|1] ""  FVC
 SG_ FoggingRiskWindscreen : 58|1@0+ (1,0) [0|1] ""  FVC
 SG_ SideCrashDriver : 60|1@0+ (1,0) [0|1] ""  FVC
 SG_ SideCrashCodriver : 59|1@0+ (1,0) [0|1] ""  FVC
 SG_ RolloverCrash : 61|1@0+ (1,0) [0|1] ""  FVC
 SG_ FrontCrash : 63|1@0+ (1,0) [0|1] ""  FVC
 SG_ RearCrash : 62|1@0+ (1,0) [0|1] ""  FVC

BO_ 788 VMC_02: 8 FVC
 SG_ ACC_Acceleration : 39|11@0+ (0.005,-7.22) [-7.22|3.015] "ms²"  MGW
 SG_ ACC_ComfortBandLowerLimit : 7|7@0+ (0.0165,0) [0|2.0955] "ms²"  MGW
 SG_ ACC_ComfortBandUpperLimit : 15|7@0+ (0.0165,0) [0|2.0955] "ms²"  MGW
 SG_ ACC_Dec2StopRequest : 8|1@0+ (1,0) [0|1] ""  MGW
 SG_ ACC_DriveOffRequest : 40|1@0+ (1,0) [0|1] ""  MGW
 SG_ ACC_LowerJerkLimit : 55|8@0+ (0.05,0) [0|12.75] "ms³"  MGW
 SG_ ACC_MinimalBraking : 0|1@0+ (1,0) [0|1] ""  MGW
 SG_ ACC_ReducedDynamicDriveoff : 24|1@0+ (1,0) [0|1] ""  MGW
 SG_ ACC_StartStopInfo : 42|2@0+ (1,0) [0|3] ""  MGW
 SG_ ACC_StatusACC : 28|4@0+ (1,0) [0|15] ""  MGW
 SG_ ACC_StoppingDistance : 23|11@0+ (0.01,0) [0|20.47] "m"  MGW
 SG_ ACC_Type : 44|2@0+ (1,0) [0|3] ""  MGW
 SG_ ACC_UpperJerkLimit : 63|8@0+ (0.05,0) [0|12.75] "ms³"  MGW

BO_ 835 VMC_03: 6 FVC
 SG_ ACC_EngineTargetTorque : 7|16@0+ (1,0) [0|65535] "Nm"  MGW
 SG_ ACC_RequestStopBrake : 20|1@0+ (1,0) [0|1] ""  MGW
 SG_ ACC_RequestBrakeRelease : 21|1@0+ (1,0) [0|1] ""  MGW
 SG_ ACC_RequestBrakeControl : 22|1@0+ (1,0) [0|1] ""  MGW
 SG_ ACC_RequestEngineTorqueControl : 23|1@0+ (1,0) [0|1] ""  MGW

BO_ 800 VMC_04: 8 FVC
 SG_ ADAS_ExtMinRPCTrq : 27|12@0+ (0.02,-20.48) [-20.48|20.46] "Nm"  MGW
 SG_ ADAS_ExtMaxRPCTrq : 23|12@0+ (0.02,-20.48) [-20.48|20.46] "Nm"  MGW
 SG_ TargetSteeringAngle : 7|16@0+ (0.002,-65.536) [-65.536|65.534] "deg"  MGW

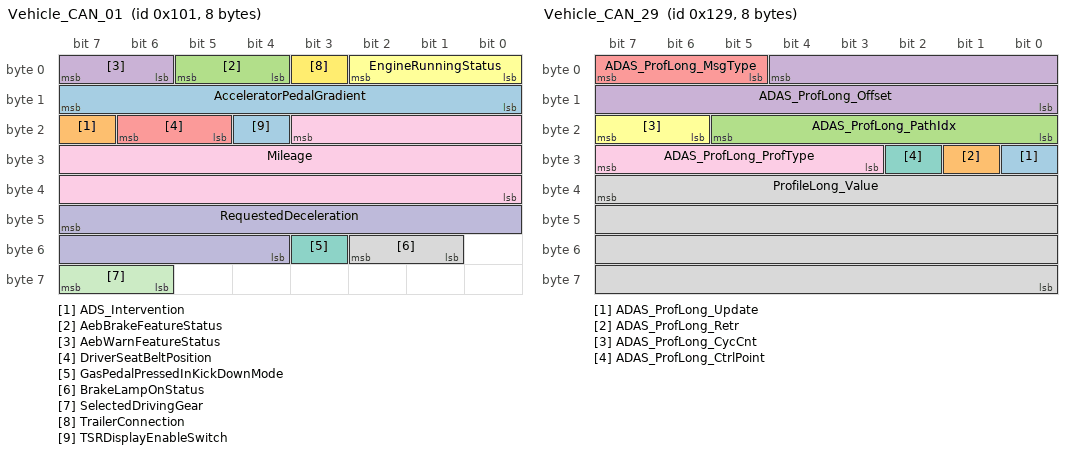
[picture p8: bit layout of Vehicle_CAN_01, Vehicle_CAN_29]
BO_ 257 Vehicle_CAN_01: 8 MGW
 SG_ AcceleratorPedalGradient : 15|8@0+ (1,0) [0|255] ""  FVC
 SG_ ADS_Intervention : 23|1@0+ (1,0) [0|1] ""  FVC
 SG_ AebBrakeFeatureStatus : 5|2@0+ (1,0) [0|3] ""  FVC
 SG_ AebWarnFeatureStatus : 7|2@0+ (1,0) [0|3] ""  FVC
 SG_ DriverSeatBeltPosition : 22|2@0+ (1,0) [0|3] ""  FVC
 SG_ EngineRunningStatus : 2|3@0+ (1,0) [0|7] ""  FVC
 SG_ GasPedalPressedInKickDownMode : 51|1@0+ (1,0) [0|1] ""  FVC
 SG_ BrakeLampOnStatus : 50|2@0+ (1,0) [0|3] ""  FVC
 SG_ Mileage : 19|20@0+ (1,0) [0|1048575] ""  FVC
 SG_ RequestedDeceleration : 47|12@0+ (0.01,-20.47) [-20.47|20.48] ""  FVC
 SG_ SelectedDrivingGear : 63|2@0+ (1,0) [0|3] ""  FVC
 SG_ TrailerConnection : 3|1@0+ (1,0) [0|1] ""  FVC
 SG_ TSRDisplayEnableSwitch : 20|1@0+ (1,0) [0|1] ""  FVC

BO_ 1282 ACC_Video_TargetObject2: 8 FVC
 SG_ ACC_Video_TO01_brakeLightDet : 7|8@0+ (1,0) [0|255] ""  MGW
 SG_ ACC_Video_TO01_scaleChange : 15|24@0+ (1,0) [0|16777200] ""  MGW
 SG_ ACC_Video_TO01_time2collision : 39|24@0+ (1,0) [0|16777200] "s"  MGW

BO_ 297 Vehicle_CAN_29: 8 MGW
 SG_ ADAS_ProfLong_Update : 24|1@0+ (1,0) [0|0] ""  FVC
 SG_ ADAS_ProfLong_Retr : 25|1@0+ (1,0) [0|1] ""  FVC
 SG_ ADAS_ProfLong_PathIdx : 21|6@0+ (1,0) [8|63] ""  FVC
 SG_ ADAS_ProfLong_Offset : 4|13@0+ (1,0) [0|8190] "m"  FVC
 SG_ ADAS_ProfLong_MsgType : 7|3@0+ (1,0) [0|7] ""  FVC
 SG_ ADAS_ProfLong_CycCnt : 23|2@0+ (1,0) [0|3] ""  FVC
 SG_ ADAS_ProfLong_CtrlPoint : 26|1@0+ (1,0) [0|1] ""  FVC
 SG_ ProfileLong_Value : 39|32@0+ (1,0) [0|0] ""  FVC
 SG_ ADAS_ProfLong_ProfType : 31|5@0+ (1,0) [0|31] ""  FVC

BO_ 804 ACC_02: 8 FVC
 SG_ ACC_AcousticalWarning : 15|2@0+ (1,0) [0|3] ""  MGW
 SG_ ACC_AdditionalDisplayInfo : 39|8@0+ (1,0) [0|255] ""  MGW
 SG_ ACC_DisplayedStatus : 46|3@0+ (1,0) [0|7] ""  MGW
 SG_ ACC_DisplayedTgap : 11|3@0+ (1,0) [0|7] ""  MGW
 SG_ ACC_DisplayPrio : 5|2@0+ (1,0) [0|3] ""  MGW
 SG_ ACC_DriverAlertSymbol : 30|7@0+ (1,0) [0|127] ""  MGW
 SG_ ACC_DrivingProgram : 23|4@0+ (1,0) [0|15] ""  MGW
 SG_ ACC_DrivingProgramStatus : 3|2@0+ (1,0) [0|3] ""  MGW
 SG_ ACC_OpticalWarning : 6|1@0+ (1,0) [0|1] ""  MGW
 SG_ ACC_SetSpeed : 43|10@0+ (0.32,0) [0|327.36] "km/h"  MGW
 SG_ ACC_StatusMode : 13|2@0+ (1,0) [0|3] ""  MGW
 SG_ ACC_TargetObjectPresent : 1|2@0+ (1,0) [0|3] ""  MGW
 SG_ ACC_TgapMarker : 7|1@0+ (1,0) [0|1] ""  MGW
 SG_ ACC_TORindex : 49|10@0+ (1,0) [0|1023] ""  MGW
 SG_ ACC_WarnInfo : 19|5@0+ (1,0) [0|31] ""  MGW

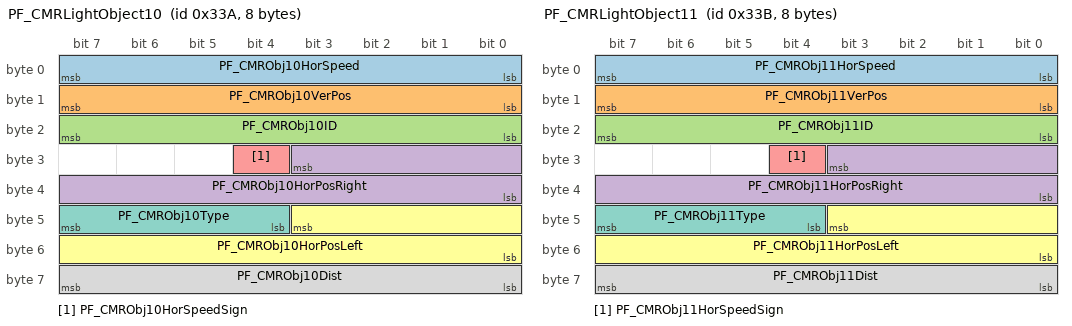
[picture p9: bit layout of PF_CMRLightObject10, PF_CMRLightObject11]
BO_ 826 PF_CMRLightObject10: 8 FVC
 SG_ PF_CMRObj10HorSpeed : 7|8@0+ (0.1,0) [0|25] "deg/s"  MGW
 SG_ PF_CMRObj10VerPos : 15|8@0+ (0.1,-12) [-12|12] "deg"  MGW
 SG_ PF_CMRObj10ID : 23|8@0+ (1,0) [1|250] "unique object ID 1...250 (repeat"  MGW
 SG_ PF_CMRObj10HorPosRight : 27|12@0+ (0.02,-40) [-40|40] "deg"  MGW
 SG_ PF_CMRObj10HorSpeedSign : 28|1@0+ (1,0) [0|1] ""  MGW
 SG_ PF_CMRObj10HorPosLeft : 43|12@0+ (0.02,-40) [-40|40] "deg"  MGW
 SG_ PF_CMRObj10Type : 47|4@0+ (1,0) [0|15] ""  MGW
 SG_ PF_CMRObj10Dist : 63|8@0+ (2,0) [0|500] "m"  MGW

BO_ 827 PF_CMRLightObject11: 8 FVC
 SG_ PF_CMRObj11HorSpeed : 7|8@0+ (0.1,0) [0|25] "deg/s"  MGW
 SG_ PF_CMRObj11VerPos : 15|8@0+ (0.1,-12) [-12|12] "deg"  MGW
 SG_ PF_CMRObj11ID : 23|8@0+ (1,0) [1|250] "unique object ID 1...250 (repeat"  MGW
 SG_ PF_CMRObj11HorPosRight : 27|12@0+ (0.02,-40) [-40|40] "deg"  MGW
 SG_ PF_CMRObj11HorSpeedSign : 28|1@0+ (1,0) [0|1] ""  MGW
 SG_ PF_CMRObj11HorPosLeft : 43|12@0+ (0.02,-40) [-40|40] "deg"  MGW
 SG_ PF_CMRObj11Type : 47|4@0+ (1,0) [0|15] ""  MGW
 SG_ PF_CMRObj11Dist : 63|8@0+ (2,0) [0|500] "m"  MGW

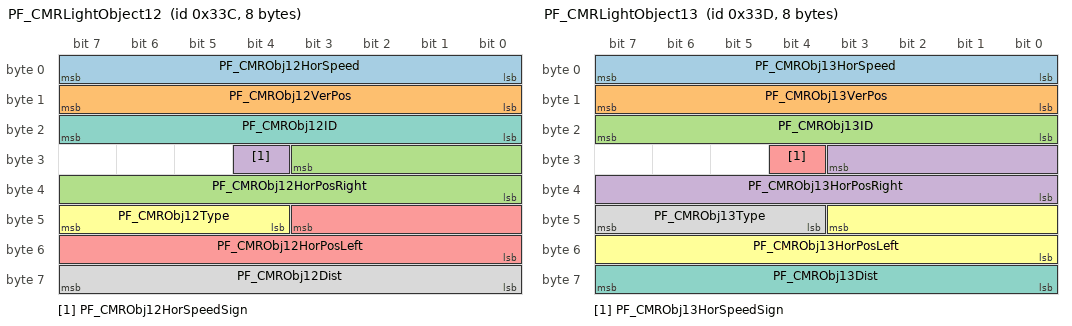
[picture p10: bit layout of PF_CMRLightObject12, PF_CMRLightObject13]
BO_ 828 PF_CMRLightObject12: 8 FVC
 SG_ PF_CMRObj12HorSpeed : 7|8@0+ (0.1,0) [0|25] "deg/s"  MGW
 SG_ PF_CMRObj12VerPos : 15|8@0+ (0.1,-12) [-12|12] "deg"  MGW
 SG_ PF_CMRObj12HorPosRight : 27|12@0+ (0.02,-40) [-40|40] "deg"  MGW
 SG_ PF_CMRObj12HorSpeedSign : 28|1@0+ (1,0) [0|1] ""  MGW
 SG_ PF_CMRObj12HorPosLeft : 43|12@0+ (0.02,-40) [-40|40] "deg"  MGW
 SG_ PF_CMRObj12Type : 47|4@0+ (1,0) [0|15] ""  MGW
 SG_ PF_CMRObj12ID : 23|8@0+ (1,0) [1|250] "unique object ID 1...250 (repeat"  MGW
 SG_ PF_CMRObj12Dist : 63|8@0+ (2,0) [0|500] "m"  MGW

BO_ 829 PF_CMRLightObject13: 8 FVC
 SG_ PF_CMRObj13HorSpeed : 7|8@0+ (0.1,0) [0|25] "deg/s"  MGW
 SG_ PF_CMRObj13VerPos : 15|8@0+ (0.1,-12) [-12|12] "deg"  MGW
 SG_ PF_CMRObj13ID : 23|8@0+ (1,0) [1|250] "unique object ID 1...250 (repeat"  MGW
 SG_ PF_CMRObj13HorPosRight : 27|12@0+ (0.02,-40) [-40|40] "deg"  MGW
 SG_ PF_CMRObj13HorSpeedSign : 28|1@0+ (1,0) [0|1] ""  MGW
 SG_ PF_CMRObj13HorPosLeft : 43|12@0+ (0.02,-40) [-40|40] "deg"  MGW
 SG_ PF_CMRObj13Dist : 63|8@0+ (2,0) [0|500] "m"  MGW
 SG_ PF_CMRObj13Type : 47|4@0+ (1,0) [0|15] ""  MGW

BO_ 265 Vehicle_CAN_09: 8 MGW
 SG_ EngineControllerStatus : 27|3@0+ (1,0) [0|7] ""  FVC
 SG_ EngineRPM : 55|16@0+ (0.25,0) [0|16383.75] "1/min"  FVC
 SG_ EngineRPM_Qbit : 9|1@0+ (1,0) [0|1] ""  FVC
 SG_ Gateway1Timeout : 20|1@0+ (1,0) [0|1] ""  FVC
 SG_ Gateway2Timeout : 19|1@0+ (1,0) [0|1] ""  FVC
 SG_ Gateway3Timeout : 18|1@0+ (1,0) [0|1] ""  FVC
 SG_ Gateway4Timeout : 17|1@0+ (1,0) [0|1] ""  FVC
 SG_ Gateway5Timeout : 16|1@0+ (1,0) [0|1] ""  FVC
 SG_ LimiterActive : 8|1@0+ (1,0) [0|1] ""  FVC
 SG_ RoadSlope : 47|8@0+ (0.8,-101.6) [-101.6|102.4] "%"  FVC
 SG_ RoadSlope_Qbit : 22|1@0+ (1,0) [0|1] ""  FVC
 SG_ StartStop_DriverRequest : 29|2@0+ (1,0) [0|3] ""  FVC
 SG_ StartStop_EngineStarting : 10|1@0+ (1,0) [0|1] ""  FVC
 SG_ StartStop_EngineStopping : 11|1@0+ (1,0) [0|1] ""  FVC
 SG_ StartStop_Status : 31|2@0+ (1,0) [0|3] ""  FVC
 SG_ ThrottleRaw_Qbit : 23|1@0+ (1,0) [0|1] ""  FVC
 SG_ Vehicle_CAN_09_Counter : 15|4@0+ (1,0) [0|15] ""  FVC
 SG_ Vehicle_CAN_09_CRC : 7|8@0+ (1,0) [0|255] ""  FVC
 SG_ VehicleMass : 39|8@0+ (32,0) [0|8128] "kg"  FVC
 SG_ VehicleMass_Qbit : 21|1@0+ (1,0) [0|1] ""  FVC
 SG_ ENG_EM_TEST_MODE_ENABLE : 24|1@0+ (1,0) [0|1] ""  FVC

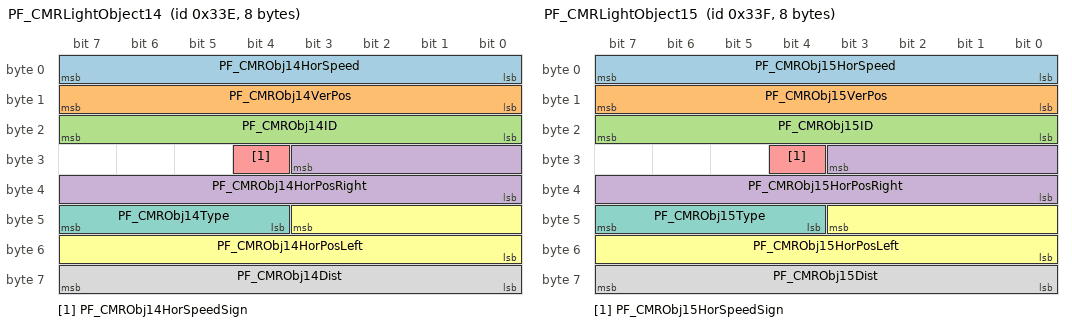
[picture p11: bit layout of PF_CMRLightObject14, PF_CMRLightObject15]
BO_ 830 PF_CMRLightObject14: 8 FVC
 SG_ PF_CMRObj14HorSpeed : 7|8@0+ (0.1,0) [0|25] "deg/s"  MGW
 SG_ PF_CMRObj14VerPos : 15|8@0+ (0.1,-12) [-12|12] "deg"  MGW
 SG_ PF_CMRObj14ID : 23|8@0+ (1,0) [1|250] "unique object ID 1...250 (repeat"  MGW
 SG_ PF_CMRObj14HorPosRight : 27|12@0+ (0.02,-40) [-40|40] "deg"  MGW
 SG_ PF_CMRObj14HorSpeedSign : 28|1@0+ (1,0) [0|1] ""  MGW
 SG_ PF_CMRObj14HorPosLeft : 43|12@0+ (0.02,-40) [-40|40] "deg"  MGW
 SG_ PF_CMRObj14Type : 47|4@0+ (1,0) [0|15] ""  MGW
 SG_ PF_CMRObj14Dist : 63|8@0+ (2,0) [0|500] "m"  MGW

BO_ 870 LIGHT_01: 8 MGW
 SG_ ClfFeatureCoded : 1|2@0+ (1,0) [0|3] ""  FVC
 SG_ ClfFeatureStatus : 3|2@0+ (1,0) [0|3] ""  FVC

BO_ 831 PF_CMRLightObject15: 8 FVC
 SG_ PF_CMRObj15HorSpeed : 7|8@0+ (0.1,0) [0|25] "deg/s"  MGW
 SG_ PF_CMRObj15VerPos : 15|8@0+ (0.1,-12) [-12|12] "deg"  MGW
 SG_ PF_CMRObj15ID : 23|8@0+ (1,0) [1|250] "unique object ID 1...250 (repeat"  MGW
 SG_ PF_CMRObj15HorPosRight : 27|12@0+ (0.02,-40) [-40|40] "deg"  MGW
 SG_ PF_CMRObj15HorSpeedSign : 28|1@0+ (1,0) [0|1] ""  MGW
 SG_ PF_CMRObj15HorPosLeft : 43|12@0+ (0.02,-40) [-40|40] "deg"  MGW
 SG_ PF_CMRObj15Type : 47|4@0+ (1,0) [0|15] ""  MGW
 SG_ PF_CMRObj15Dist : 63|8@0+ (2,0) [0|500] "m"  MGW

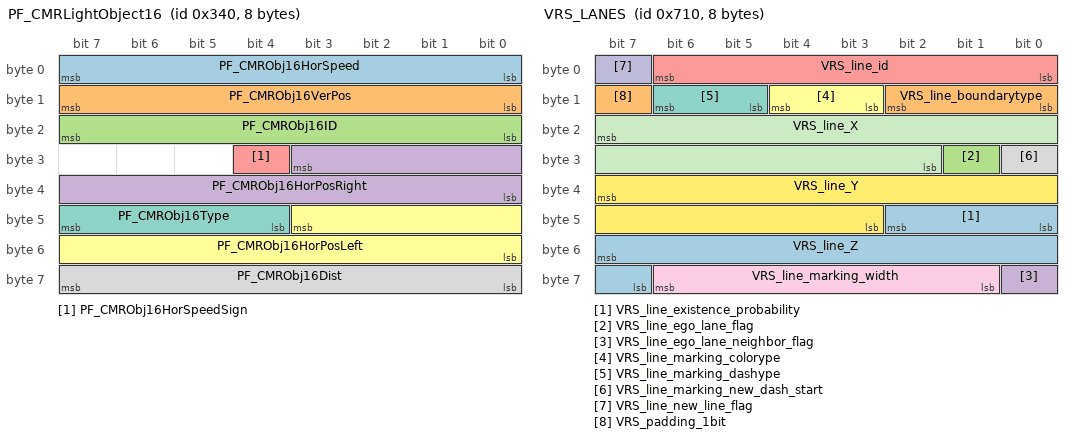
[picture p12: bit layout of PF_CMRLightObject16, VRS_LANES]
BO_ 832 PF_CMRLightObject16: 8 FVC
 SG_ PF_CMRObj16HorSpeed : 7|8@0+ (0.1,0) [0|25] "deg/s"  MGW
 SG_ PF_CMRObj16VerPos : 15|8@0+ (0.1,-12) [-12|12] "deg"  MGW
 SG_ PF_CMRObj16ID : 23|8@0+ (1,0) [1|250] "unique object ID 1...250 (repeat"  MGW
 SG_ PF_CMRObj16HorPosRight : 27|12@0+ (0.02,-40) [-40|40] "deg"  MGW
 SG_ PF_CMRObj16HorSpeedSign : 28|1@0+ (1,0) [0|1] ""  MGW
 SG_ PF_CMRObj16HorPosLeft : 43|12@0+ (0.02,-40) [-40|40] "deg"  MGW
 SG_ PF_CMRObj16Type : 47|4@0+ (1,0) [0|15] ""  MGW
 SG_ PF_CMRObj16Dist : 63|8@0+ (2,0) [0|500] "m"  MGW

BO_ 1792 VRS_HEADER_1: 8 FVC
 SG_ VRS_FrameCounter : 7|64@0+ (1,0) [0|1.8446744074E+19] ""  MGW

BO_ 1793 VRS_HEADER_2: 8 FVC
 SG_ VRS_Odometry_DELTA_Y : 7|8@0+ (0.00392156,0) [-0.50195968|0.49803812] "m"  MGW
 SG_ VRS_Odometry_DELTA_YAW : 15|14@0+ (4.88311E-05,0) [-0.4000243712|0.3999755401] "m"  MGW
 SG_ VRS_Odometry_DELTA_X : 17|13@0+ (0.0019533,6) [-0.50195968|0.49803812] "m"  MGW

BO_ 834 WindscreenHeater: 2 FVC
 SG_ WindscreenHeaterStatus : 4|5@0+ (1,0) [0|16] ""  MGW

BO_ 864 AEB_01: 8 MGW
 SG_ AEBPActive : 5|1@0+ (1,0) [0|1] ""  FVC
 SG_ AEBFActive : 4|1@0+ (1,0) [0|1] ""  FVC
 SG_ ADAS_WarnType_FCW : 20|2@0+ (1,0) [0|3] ""  FVC
 SG_ ADAS_WarnTyp_FCWAEB : 18|3@0+ (1,0) [0|7] ""  FVC
 SG_ ADAS_Sts_FCW : 14|3@0+ (1,0) [0|7] ""  FVC
 SG_ ADAS_FwdWarnFltTxt : 11|1@0+ (1,0) [0|1] ""  FVC
 SG_ ADAS_Sts_AEB : 10|3@0+ (1,0) [0|7] ""  FVC
 SG_ AebFunctionStatus : 1|2@0+ (1,0) [0|3] ""  FVC
 SG_ AEBOncomingFeatureStatus : 3|2@0+ (1,0) [0|3] ""  FVC

BO_ 329 VLC_01: 8 MGW
 SG_ ENG_ENG_TRQ_130 : 7|16@0+ (1,0) [-32768|32767] "Nm"  FVC
 SG_ ENG_IDAS_MAXMUM_TORQUE : 23|16@0+ (1,0) [-32768|32767] "Nm"  FVC
 SG_ ENG_IDAS_MINMUM_TORQUE : 39|16@0+ (1,0) [-32768|32767] "Nm"  FVC
 SG_ ENG_DRIVER_REQ_TRQ_130 : 55|16@0+ (0.2,0) [-32768|32767] "Nm"  FVC

BO_ 336 VLC_02: 4 MGW
 SG_ CVT_RATIO_INFO_191 : 7|8@0+ (0.015625,0) [0|3.984375] ""  FVC

BO_ 865 AEB_02: 8 FVC
 SG_ ActiveSafetyFunction : 23|16@0+ (1,0) [0|65535] ""  MGW
 SG_ ADAS_FCWSwtFb : 15|2@0+ (1,0) [0|3] ""  MGW
 SG_ ADAS_AEBSwtFb : 13|2@0+ (1,0) [0|3] ""  MGW
 SG_ AEB_02_crc : 7|8@0+ (1,0) [0|255] ""  MGW
 SG_ AEB_02_Alive_Counter : 11|4@0+ (1,0) [0|15] ""  MGW

BO_ 1808 VRS_LANES: 8 FVC
 SG_ VRS_line_existence_probability : 42|3@0+ (1,0) [0|7] ""  MGW
 SG_ VRS_line_boundarytype : 10|3@0+ (1,0) [0|7] ""  MGW
 SG_ VRS_line_ego_lane_flag : 25|1@0+ (1,0) [0|3] ""  MGW
 SG_ VRS_line_ego_lane_neighbor_flag : 56|1@0+ (1,0) [0|1] ""  MGW
 SG_ VRS_line_id : 6|7@0+ (1,0) [0|127] ""  MGW
 SG_ VRS_line_marking_colorype : 12|2@0+ (1,0) [0|3] ""  MGW
 SG_ VRS_line_marking_dashype : 14|2@0+ (1,0) [0|3] ""  MGW
 SG_ VRS_line_marking_new_dash_start : 24|1@0+ (1,0) [0|1] ""  MGW
 SG_ VRS_line_marking_width : 62|6@0+ (1,0) [0|63] ""  MGW
 SG_ VRS_line_new_line_flag : 7|1@0+ (1,0) [0|1] ""  MGW
 SG_ VRS_line_X : 23|14@0+ (1,0) [0|16383] "cm"  MGW
 SG_ VRS_line_Y : 39|13@0+ (1,0) [-4096|4095] "cm"  MGW
 SG_ VRS_line_Z : 55|9@0+ (1,0) [-256|255] "cm"  MGW
 SG_ VRS_padding_1bit : 15|1@0+ (1,0) [0|1] ""  MGW

BO_ 791 TSR_SLS_01: 8 FVC
 SG_ TSRAddSign1 : 1|2@0+ (1,0) [0|3] ""  MGW
 SG_ TSRMainSign1 : 6|5@0+ (1,0) [0|31] ""  MGW

BO_ 30 TimeSync: 8 MGW
 SG_ TimeSync_Type M : 7|8@0+ (1,0) [0|255] ""  FVC
 SG_ TimeSync_CRC : 15|8@0+ (1,0) [0|255] ""  FVC
 SG_ TimeSync_SequenceCounter : 19|4@0+ (1,0) [0|15] ""  FVC
 SG_ TimeSync_TimeDomain : 23|4@0+ (1,0) [0|15] ""  FVC
 SG_ TimeSync_UserByte0 m32 : 31|8@0+ (1,0) [0|255] ""  FVC
 SG_ TimeSync_SyncTimeSec m32 : 39|32@0+ (1,0) [0|4294967295] ""  FVC
 SG_ TimeSync_OverflowOfSeconds m40 : 25|2@0+ (1,0) [0|3] ""  FVC
 SG_ TimeSync_SGW m40 : 26|1@0+ (1,0) [0|1] ""  FVC
 SG_ TimeSync_Reserved0 m40 : 31|5@0+ (1,0) [0|31] ""  FVC
 SG_ TimeSync_SyncTimeNSec m40 : 39|32@0+ (1,0) [0|4294967295] ""  FVC

BO_ 1882 Diag_Phy_Resp: 8 FVC
 SG_ Diag_Phy_Resp : 7|64@0+ (1,0) [0|1.8446744074E+19] ""  MGW

BO_ 792 TSR_SLS_02: 8 FVC
 SG_ TSRNextSpdLimit : 7|5@0+ (1,0) [0|31] ""  MGW
 SG_ TSRNextSpdLimitDist : 15|16@0+ (1,0) [0|65535] "m"  MGW
 SG_ TSRFeatureDegradation : 31|8@0+ (1,0) [0|255] ""  MGW

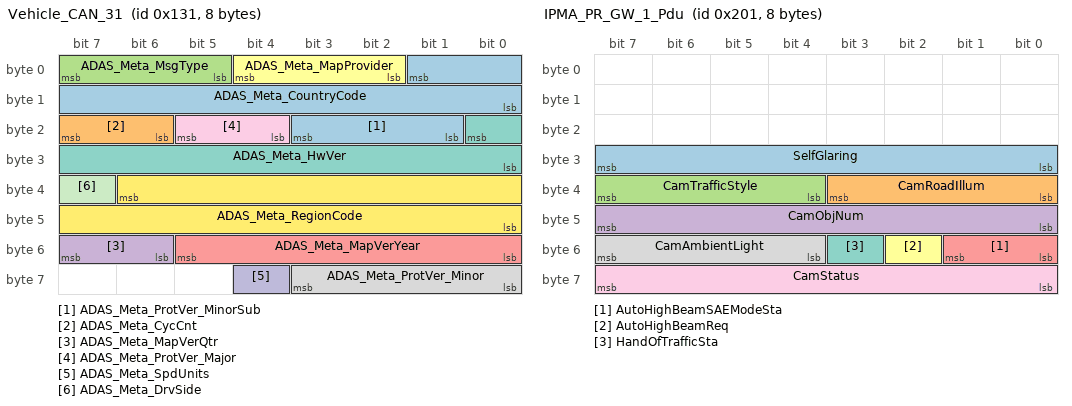
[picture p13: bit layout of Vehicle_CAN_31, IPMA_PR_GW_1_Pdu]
BO_ 305 Vehicle_CAN_31: 8 MGW
 SG_ ADAS_Meta_ProtVer_MinorSub : 19|3@0+ (1,0) [0|7] ""  FVC
 SG_ ADAS_Meta_CycCnt : 23|2@0+ (1,0) [0|3] ""  FVC
 SG_ ADAS_Meta_MsgType : 7|3@0+ (1,0) [0|7] ""  FVC
 SG_ ADAS_Meta_MapVerQtr : 55|2@0+ (1,1) [1|4] "Qtr"  FVC
 SG_ ADAS_Meta_MapVerYear : 53|6@0+ (1,2000) [2000|2063] "Year"  FVC
 SG_ ADAS_Meta_MapProvider : 4|3@0+ (1,0) [0|7] ""  FVC
 SG_ ADAS_Meta_HwVer : 16|9@0+ (1,0) [0|511] ""  FVC
 SG_ ADAS_Meta_ProtVer_Minor : 59|4@0+ (1,0) [0|15] ""  FVC
 SG_ ADAS_Meta_ProtVer_Major : 21|2@0+ (1,0) [0|3] ""  FVC
 SG_ ADAS_Meta_SpdUnits : 60|1@0+ (1,0) [0|1] ""  FVC
 SG_ ADAS_Meta_DrvSide : 39|1@0+ (1,0) [0|1] ""  FVC
 SG_ ADAS_Meta_RegionCode : 38|15@0+ (1,0) [0|32767] ""  FVC
 SG_ ADAS_Meta_CountryCode : 1|10@0+ (1,0) [0|1023] ""  FVC

BO_ 513 IPMA_PR_GW_1_Pdu: 8 FVC
 SG_ SelfGlaring : 31|8@0+ (1,0) [0|255] ""  MGW
 SG_ CamRoadIllum : 35|4@0+ (1,0) [0|15] ""  MGW
 SG_ CamTrafficStyle : 39|4@0+ (1,0) [0|15] ""  MGW
 SG_ CamObjNum : 47|8@0+ (1,0) [0|255] ""  MGW
 SG_ AutoHighBeamSAEModeSta : 49|2@0+ (1,0) [0|3] ""  MGW
 SG_ AutoHighBeamReq : 50|1@0+ (1,0) [0|1] ""  MGW
 SG_ HandOfTrafficSta : 51|1@0+ (1,0) [0|1] ""  MGW
 SG_ CamAmbientLight : 55|4@0+ (1,0) [0|15] ""  MGW
 SG_ CamStatus : 63|8@0+ (1,0) [0|255] ""  MGW

BO_ 786 TSR_01: 8 FVC
 SG_ TSRDisplayEnable : 3|1@0+ (1,0) [0|1] ""  MGW
 SG_ TSROperatingStatus : 2|3@0+ (1,0) [0|7] ""  MGW
 SG_ TSRSpdLimitUnits : 5|2@0+ (1,0) [0|3] ""  MGW

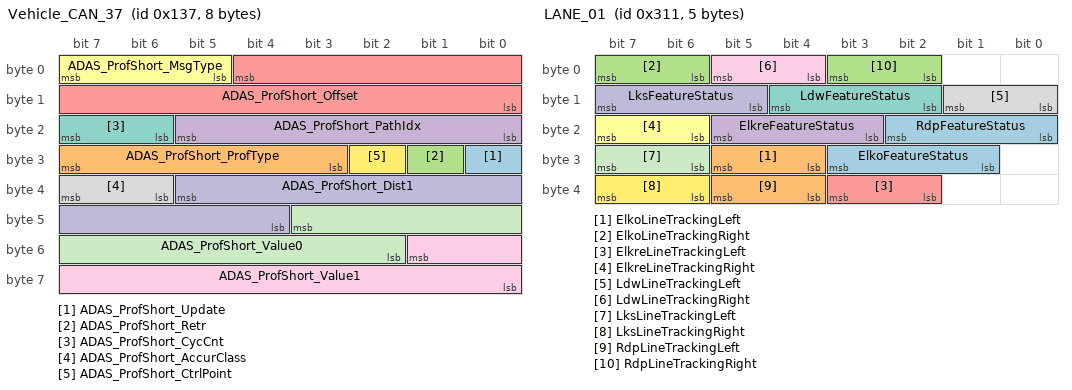
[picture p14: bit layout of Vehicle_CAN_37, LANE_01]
BO_ 311 Vehicle_CAN_37: 8 MGW
 SG_ ADAS_ProfShort_Update : 24|1@0+ (1,0) [0|0] ""  FVC
 SG_ ADAS_ProfShort_ProfType : 31|5@0+ (1,0) [0|31] ""  FVC
 SG_ ADAS_ProfShort_Retr : 25|1@0+ (1,0) [0|1] ""  FVC
 SG_ ADAS_ProfShort_PathIdx : 21|6@0+ (1,0) [8|63] ""  FVC
 SG_ ADAS_ProfShort_Offset : 4|13@0+ (1,0) [0|8190] "m"  FVC
 SG_ ADAS_ProfShort_MsgType : 7|3@0+ (1,0) [0|7] ""  FVC
 SG_ ADAS_ProfShort_CycCnt : 23|2@0+ (1,0) [0|3] ""  FVC
 SG_ ADAS_ProfShort_AccurClass : 39|2@0+ (1,0) [0|3] ""  FVC
 SG_ ADAS_ProfShort_Value1 : 49|10@0+ (1,0) [0|1023] ""  FVC
 SG_ ADAS_ProfShort_Dist1 : 37|10@0+ (1,0) [0|1022] "m"  FVC
 SG_ ADAS_ProfShort_Value0 : 43|10@0+ (1,0) [0|1023] ""  FVC
 SG_ ADAS_ProfShort_CtrlPoint : 26|1@0+ (1,0) [0|1] ""  FVC

BO_ 1874 Diag_Phy_req: 8 MGW
 SG_ Diag_Phy_req : 7|64@0+ (1,0) [0|1.8446744074E+19] ""  FVC

BO_ 785 LANE_01: 5 FVC
 SG_ ElkoFeatureStatus : 27|3@0+ (1,0) [0|7] ""  MGW
 SG_ ElkoLineTrackingLeft : 29|2@0+ (1,0) [0|3] ""  MGW
 SG_ ElkoLineTrackingRight : 7|2@0+ (1,0) [0|3] ""  MGW
 SG_ ElkreFeatureStatus : 21|3@0+ (1,0) [0|7] ""  MGW
 SG_ ElkreLineTrackingLeft : 35|2@0+ (1,0) [0|3] ""  MGW
 SG_ ElkreLineTrackingRight : 23|2@0+ (1,0) [0|3] ""  MGW
 SG_ LdwFeatureStatus : 12|3@0+ (1,0) [0|7] ""  MGW
 SG_ LdwLineTrackingLeft : 9|2@0+ (1,0) [0|3] ""  MGW
 SG_ LdwLineTrackingRight : 5|2@0+ (1,0) [0|3] ""  MGW
 SG_ LksFeatureStatus : 15|3@0+ (1,0) [0|7] ""  MGW
 SG_ LksLineTrackingLeft : 31|2@0+ (1,0) [0|3] ""  MGW
 SG_ LksLineTrackingRight : 39|2@0+ (1,0) [0|3] ""  MGW
 SG_ RdpFeatureStatus : 18|3@0+ (1,0) [0|7] ""  MGW
 SG_ RdpLineTrackingLeft : 37|2@0+ (1,0) [0|3] ""  MGW
 SG_ RdpLineTrackingRight : 3|2@0+ (1,0) [0|3] ""  MGW

BO_ 769 LANE_02: 7 MGW
 SG_ ElkeStatus : 7|2@0+ (1,0) [0|3] ""  FVC
 SG_ ElkoAdjustInterventionTime : 55|4@0+ (1,0) [0|15] ""  FVC
 SG_ ElkoAdjustWarningType : 51|4@0+ (1,0) [0|15] ""  FVC
 SG_ ElkoStatus : 5|2@0+ (1,0) [0|3] ""  FVC
 SG_ ElkreAdjustInterventionTime : 47|4@0+ (1,0) [0|15] ""  FVC
 SG_ ElkreAdjustWarningType : 43|4@0+ (1,0) [0|15] ""  FVC
 SG_ FeatureInteraction : 10|1@0+ (1,0) [0|1] ""  FVC
 SG_ LdwAdjustSensitivity : 15|4@0+ (1,0) [0|15] ""  FVC
 SG_ LdwAdjustWarningTime : 19|4@0+ (1,0) [0|15] ""  FVC
 SG_ LdwAdjustWarningType : 23|4@0+ (1,0) [0|15] ""  FVC
 SG_ LdwStatus : 1|2@0+ (1,0) [0|3] ""  FVC
 SG_ LksStatus : 9|2@0+ (1,0) [0|3] ""  FVC
 SG_ RdpAdjustSensitivity : 39|4@0+ (1,0) [0|15] ""  FVC
 SG_ RdpAdjustWarningTime : 31|4@0+ (1,0) [0|15] ""  FVC
 SG_ RdpAdjustWarningType : 35|4@0+ (1,0) [0|15] ""  FVC
 SG_ RdpStatus : 3|2@0+ (1,0) [0|3] ""  FVC
 SG_ SteeringSystemState : 25|2@0+ (1,0) [0|3] ""  FVC

BO_ 866 TLF_Status: 8 FVC
 SG_ TL_suggestedDriveAction : 3|4@0+ (1,0) [0|15] ""  MGW
 SG_ TLF_functionState : 7|4@0+ (1,0) [0|15] ""  MGW
 SG_ TL_warning : 11|4@0+ (1,0) [0|15] ""  MGW
 SG_ TLF_Mode : 15|4@0+ (1,0) [0|15] ""  MGW

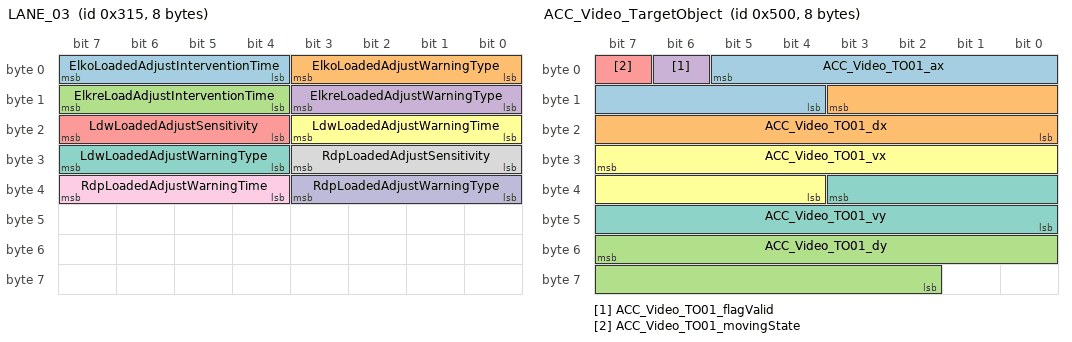
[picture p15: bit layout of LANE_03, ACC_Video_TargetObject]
BO_ 789 LANE_03: 8 FVC
 SG_ ElkoLoadedAdjustInterventionTime : 7|4@0+ (1,0) [0|15] ""  MGW
 SG_ ElkoLoadedAdjustWarningType : 3|4@0+ (1,0) [0|15] ""  MGW
 SG_ ElkreLoadAdjustInterventionTime : 15|4@0+ (1,0) [0|15] ""  MGW
 SG_ ElkreLoadedAdjustWarningType : 11|4@0+ (1,0) [0|15] ""  MGW
 SG_ LdwLoadedAdjustSensitivity : 23|4@0+ (1,0) [0|15] ""  MGW
 SG_ LdwLoadedAdjustWarningTime : 19|4@0+ (1,0) [0|15] ""  MGW
 SG_ LdwLoadedAdjustWarningType : 31|4@0+ (1,0) [0|15] ""  MGW
 SG_ RdpLoadedAdjustSensitivity : 27|4@0+ (1,0) [0|15] ""  MGW
 SG_ RdpLoadedAdjustWarningTime : 39|4@0+ (1,0) [0|15] ""  MGW
 SG_ RdpLoadedAdjustWarningType : 35|4@0+ (1,0) [0|15] ""  MGW

BO_ 278 Vehicle_CAN_15: 8 MGW
 SG_ ACC_CancelSwitch : 31|1@0+ (1,0) [0|1] ""  FVC
 SG_ ACC_LimiterSwitch : 17|1@0+ (1,0) [0|1] ""  FVC
 SG_ ACC_MainSwitch : 10|1@0+ (1,0) [0|1] ""  FVC
 SG_ ACC_ResumeSwitch : 11|1@0+ (1,0) [0|1] ""  FVC
 SG_ ACC_SetSwitch : 8|1@0+ (1,0) [0|1] ""  FVC
 SG_ ACC_SwitchFailure : 23|1@0+ (1,0) [0|1] ""  FVC
 SG_ ACC_TimegapSwitches : 34|2@0+ (1,0) [0|3] ""  FVC
 SG_ ACC_VSetMinusSwitch : 21|1@0+ (1,0) [0|1] ""  FVC
 SG_ ACC_VSetPlusSwitch : 20|1@0+ (1,0) [0|1] ""  FVC
 SG_ DisplayACCScreenActive : 30|1@0+ (1,0) [0|1] ""  FVC
 SG_ DisplayConsistentWithACC : 9|1@0+ (1,0) [0|1] ""  FVC
 SG_ DisplayedSpeed : 50|10@0+ (0.32,0) [0|325.12] "km/h"  FVC
 SG_ DisplayedSpeedUnitType : 29|1@0+ (1,0) [0|1] ""  FVC
 SG_ DisplayFailure : 16|1@0+ (1,0) [0|1] ""  FVC
 SG_ DriverSeatBeltStatus : 24|2@0+ (1,0) [0|3] ""  FVC
 SG_ DriverSeatPositionSensor : 28|2@0+ (1,0) [0|3] ""  FVC
 SG_ EPB_BrakeForce : 55|5@0+ (1,0) [0|31] "kN"  FVC
 SG_ EPB_ErrorStatus : 32|2@0+ (1,0) [0|3] ""  FVC
 SG_ EPB_Status : 26|2@0+ (1,0) [0|3] ""  FVC
 SG_ EPB_SwitchPosition : 38|2@0+ (1,0) [0|3] ""  FVC
 SG_ EPB_SwitchPosition_Qbit : 19|1@0+ (1,0) [0|1] ""  FVC
 SG_ NoForwardGear : 56|1@0+ (1,0) [0|1] ""  FVC
 SG_ ParkingBrakeActive : 18|1@0+ (1,0) [0|1] ""  FVC
 SG_ RequestedDrivingProgram : 43|4@0+ (1,0) [0|15] ""  FVC
 SG_ TrailerBrakeLampDefect : 22|1@0+ (1,0) [0|1] ""  FVC
 SG_ Vehicle_CAN_15_Counter : 15|4@0+ (1,0) [0|15] ""  FVC
 SG_ Vehicle_CAN_15_CRC : 7|8@0+ (1,0) [0|255] ""  FVC
 SG_ VehicleBrakeLampsDefect : 36|2@0+ (1,0) [0|3] ""  FVC
 SG_ VehicleDoorOpen : 46|3@0+ (1,0) [0|7] ""  FVC

BO_ 1280 ACC_Video_TargetObject: 8 FVC
 SG_ ACC_Video_TO01_ax : 5|10@0+ (0.03125,0) [-16|15.9688] "m/s²"  MGW
 SG_ ACC_Video_TO01_dx : 11|12@0+ (0.03125,0) [0|255.938] "m"  MGW
 SG_ ACC_Video_TO01_dy : 55|14@0+ (0.015625,0) [-128|127.984] "m"  MGW
 SG_ ACC_Video_TO01_flagValid : 6|1@0+ (1,0) [0|1] ""  MGW
 SG_ ACC_Video_TO01_movingState : 7|1@0+ (1,0) [0|1] ""  MGW
 SG_ ACC_Video_TO01_vx : 31|12@0+ (0.0625,0) [-128|127.984] "m/s"  MGW
 SG_ ACC_Video_TO01_vy : 35|12@0+ (0.0625,0) [-128|127.984] "m/s"  MGW

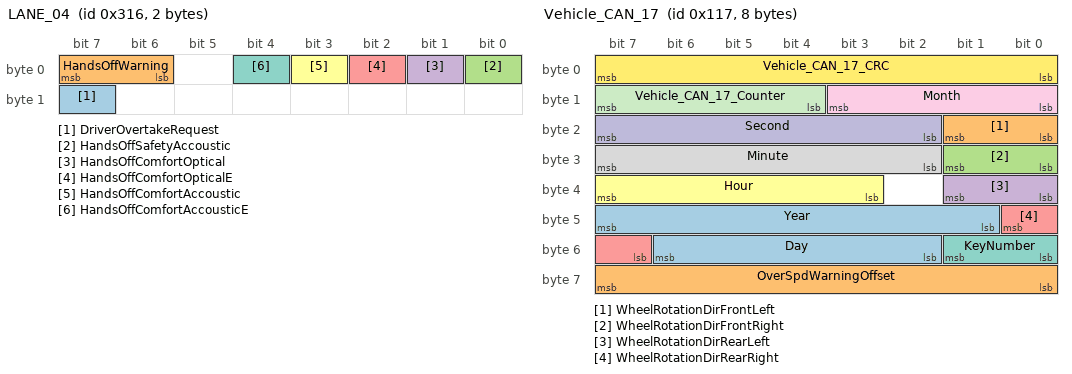
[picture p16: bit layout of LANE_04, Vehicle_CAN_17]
BO_ 790 LANE_04: 2 FVC
 SG_ DriverOvertakeRequest : 15|1@0+ (1,0) [0|1] ""  MGW
 SG_ HandsOffWarning : 7|2@0+ (1,0) [0|3] ""  MGW
 SG_ HandsOffSafetyAccoustic : 0|1@0+ (1,0) [0|1] ""  MGW
 SG_ HandsOffComfortOptical : 1|1@0+ (1,0) [0|1] ""  MGW
 SG_ HandsOffComfortOpticalE : 2|1@0+ (1,0) [0|1] ""  MGW
 SG_ HandsOffComfortAccoustic : 3|1@0+ (1,0) [0|1] ""  MGW
 SG_ HandsOffComfortAccousticE : 4|1@0+ (1,0) [0|1] ""  MGW

BO_ 279 Vehicle_CAN_17: 8 MGW
 SG_ Day : 54|5@0+ (1,0) [0|31] "Day"  FVC
 SG_ WheelRotationDirFrontLeft : 17|2@0+ (1,0) [0|3] ""  FVC
 SG_ WheelRotationDirFrontRight : 25|2@0+ (1,0) [0|3] ""  FVC
 SG_ WheelRotationDirRearLeft : 33|2@0+ (1,0) [0|3] ""  FVC
 SG_ WheelRotationDirRearRight : 40|2@0+ (1,0) [0|3] ""  FVC
 SG_ Hour : 39|5@0+ (1,0) [0|23] "h"  FVC
 SG_ KeyNumber : 49|2@0+ (1,0) [0|3] ""  FVC
 SG_ Minute : 31|6@0+ (1,0) [0|60] "m"  FVC
 SG_ Month : 11|4@0+ (1,0) [0|12] "Month"  FVC
 SG_ Second : 23|6@0+ (1,0) [0|60] "s"  FVC
 SG_ Vehicle_CAN_17_Counter : 15|4@0+ (1,0) [0|15] ""  FVC
 SG_ Vehicle_CAN_17_CRC : 7|8@0+ (1,0) [0|255] ""  FVC
 SG_ Year : 47|7@0+ (1,0) [0|127] "Year"  FVC
 SG_ OverSpdWarningOffset : 63|8@0+ (1,-128) [-128|127] ""  FVC

BO_ 833 IHC_01: 8 FVC
 SG_ AutoHighBeamReason : 7|4@0+ (1,0) [0|13] ""  MGW

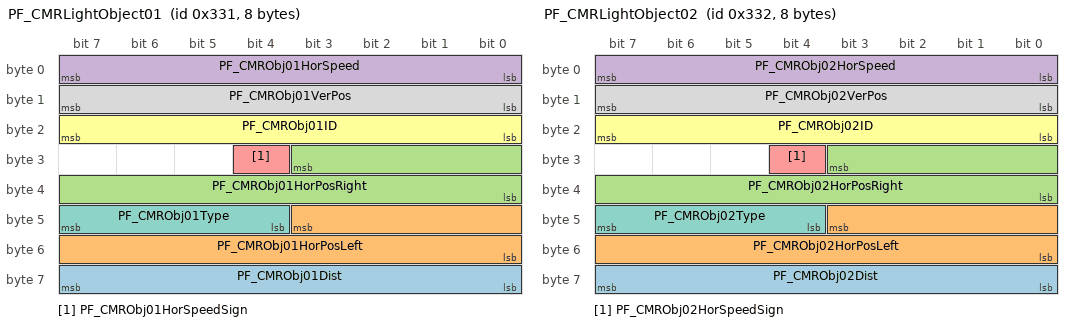
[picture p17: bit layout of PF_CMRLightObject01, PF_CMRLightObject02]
BO_ 817 PF_CMRLightObject01: 8 FVC
 SG_ PF_CMRObj01Dist : 63|8@0+ (2,0) [0|500] "m"  MGW
 SG_ PF_CMRObj01HorPosLeft : 43|12@0+ (0.02,-40) [-40|40] "deg"  MGW
 SG_ PF_CMRObj01HorPosRight : 27|12@0+ (0.02,-40) [-40|40] "deg"  MGW
 SG_ PF_CMRObj01HorSpeed : 7|8@0+ (0.1,0) [0|25] "deg/s"  MGW
 SG_ PF_CMRObj01HorSpeedSign : 28|1@0+ (1,0) [0|1] ""  MGW
 SG_ PF_CMRObj01ID : 23|8@0+ (1,0) [1|250] "unique object ID 1...250 (repeat"  MGW
 SG_ PF_CMRObj01Type : 47|4@0+ (1,0) [0|15] ""  MGW
 SG_ PF_CMRObj01VerPos : 15|8@0+ (0.1,-12) [-12|12] "deg"  MGW

BO_ 818 PF_CMRLightObject02: 8 FVC
 SG_ PF_CMRObj02Dist : 63|8@0+ (2,0) [0|500] "m"  MGW
 SG_ PF_CMRObj02HorPosLeft : 43|12@0+ (0.02,-40) [-40|40] "deg"  MGW
 SG_ PF_CMRObj02HorPosRight : 27|12@0+ (0.02,-40) [-40|40] "deg"  MGW
 SG_ PF_CMRObj02HorSpeed : 7|8@0+ (0.1,0) [0|25] "deg/s"  MGW
 SG_ PF_CMRObj02HorSpeedSign : 28|1@0+ (1,0) [0|1] ""  MGW
 SG_ PF_CMRObj02ID : 23|8@0+ (1,0) [1|250] "unique object ID 1...250 (repeat"  MGW
 SG_ PF_CMRObj02Type : 47|4@0+ (1,0) [0|15] ""  MGW
 SG_ PF_CMRObj02VerPos : 15|8@0+ (0.1,-12) [-12|12] "deg"  MGW

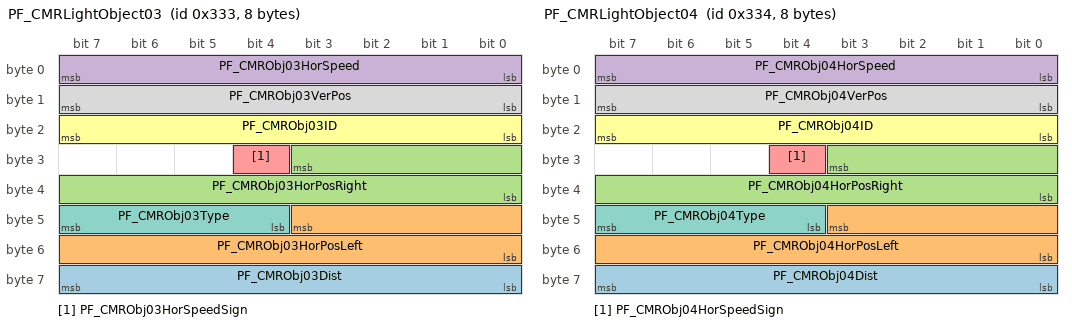
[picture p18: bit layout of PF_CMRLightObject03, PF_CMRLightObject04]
BO_ 819 PF_CMRLightObject03: 8 FVC
 SG_ PF_CMRObj03Dist : 63|8@0+ (2,0) [0|500] "m"  MGW
 SG_ PF_CMRObj03HorPosLeft : 43|12@0+ (0.02,-40) [-40|40] "deg"  MGW
 SG_ PF_CMRObj03HorPosRight : 27|12@0+ (0.02,-40) [-40|40] "deg"  MGW
 SG_ PF_CMRObj03HorSpeed : 7|8@0+ (0.1,0) [0|25] "deg/s"  MGW
 SG_ PF_CMRObj03HorSpeedSign : 28|1@0+ (1,0) [0|1] ""  MGW
 SG_ PF_CMRObj03ID : 23|8@0+ (1,0) [1|250] "unique object ID 1...250 (repeat"  MGW
 SG_ PF_CMRObj03Type : 47|4@0+ (1,0) [0|15] ""  MGW
 SG_ PF_CMRObj03VerPos : 15|8@0+ (0.1,-12) [-12|12] "deg"  MGW

BO_ 820 PF_CMRLightObject04: 8 FVC
 SG_ PF_CMRObj04Dist : 63|8@0+ (2,0) [0|500] "m"  MGW
 SG_ PF_CMRObj04HorPosLeft : 43|12@0+ (0.02,-40) [-40|40] "deg"  MGW
 SG_ PF_CMRObj04HorPosRight : 27|12@0+ (0.02,-40) [-40|40] "deg"  MGW
 SG_ PF_CMRObj04HorSpeed : 7|8@0+ (0.1,0) [0|25] "deg/s"  MGW
 SG_ PF_CMRObj04HorSpeedSign : 28|1@0+ (1,0) [0|1] ""  MGW
 SG_ PF_CMRObj04ID : 23|8@0+ (1,0) [1|250] "unique object ID 1...250 (repeat"  MGW
 SG_ PF_CMRObj04Type : 47|4@0+ (1,0) [0|15] ""  MGW
 SG_ PF_CMRObj04VerPos : 15|8@0+ (0.1,-12) [-12|12] "deg"  MGW

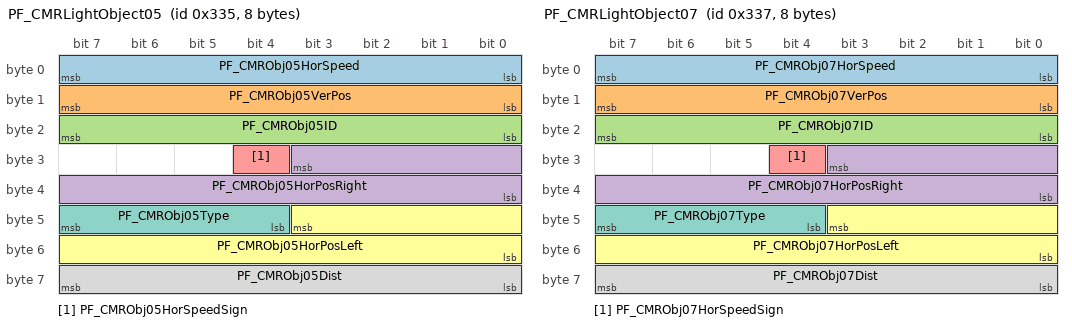
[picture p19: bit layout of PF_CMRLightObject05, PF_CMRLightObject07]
BO_ 821 PF_CMRLightObject05: 8 FVC
 SG_ PF_CMRObj05HorSpeed : 7|8@0+ (0.1,0) [0|25] "deg/s"  MGW
 SG_ PF_CMRObj05VerPos : 15|8@0+ (0.1,-12) [-12|12] "deg"  MGW
 SG_ PF_CMRObj05ID : 23|8@0+ (1,0) [1|250] "unique object ID 1...250 (repeat"  MGW
 SG_ PF_CMRObj05HorPosRight : 27|12@0+ (0.02,-40) [-40|40] "deg"  MGW
 SG_ PF_CMRObj05HorSpeedSign : 28|1@0+ (1,0) [0|1] ""  MGW
 SG_ PF_CMRObj05HorPosLeft : 43|12@0+ (0.02,-40) [-40|40] "deg"  MGW
 SG_ PF_CMRObj05Type : 47|4@0+ (1,0) [0|15] ""  MGW
 SG_ PF_CMRObj05Dist : 63|8@0+ (2,0) [0|500] "m"  MGW

BO_ 823 PF_CMRLightObject07: 8 FVC
 SG_ PF_CMRObj07HorSpeed : 7|8@0+ (0.1,0) [0|25] "deg/s"  MGW
 SG_ PF_CMRObj07VerPos : 15|8@0+ (0.1,-12) [-12|12] "deg"  MGW
 SG_ PF_CMRObj07ID : 23|8@0+ (1,0) [1|250] "unique object ID 1...250 (repeat"  MGW
 SG_ PF_CMRObj07HorPosRight : 27|12@0+ (0.02,-40) [-40|40] "deg"  MGW
 SG_ PF_CMRObj07HorSpeedSign : 28|1@0+ (1,0) [0|1] ""  MGW
 SG_ PF_CMRObj07HorPosLeft : 43|12@0+ (0.02,-40) [-40|40] "deg"  MGW
 SG_ PF_CMRObj07Type : 47|4@0+ (1,0) [0|15] ""  MGW
 SG_ PF_CMRObj07Dist : 63|8@0+ (2,0) [0|500] "m"  MGW

BO_ 824 PF_CMRLightObject08: 8 FVC
 SG_ PF_CMRObj08HorSpeed : 7|8@0+ (0.1,0) [0|25] "deg/s"  MGW
 SG_ PF_CMRObj08VerPos : 15|8@0+ (0.1,-12) [-12|12] "deg"  MGW
 SG_ PF_CMRObj08ID : 23|8@0+ (1,0) [1|250] "unique object ID 1...250 (repeat"  MGW
 SG_ PF_CMRObj08HorPosRight : 27|12@0+ (0.02,-40) [-40|40] "deg"  MGW
 SG_ PF_CMRObj08HorSpeedSign : 28|1@0+ (1,0) [0|1] ""  MGW
 SG_ PF_CMRObj08HorPosLeft : 43|12@0+ (0.02,-40) [-40|40] "deg"  MGW
 SG_ PF_CMRObj08Type : 47|4@0+ (1,0) [0|15] ""  MGW
 SG_ PF_CMRObj08Dist : 63|8@0+ (2,0) [0|500] "m"  MGW

BO_ 825 PF_CMRLightObject09: 8 FVC
 SG_ PF_CMRObj09HorSpeed : 7|8@0+ (0.1,0) [0|25] "deg/s"  MGW
 SG_ PF_CMRObj09VerPos : 15|8@0+ (0.1,-12) [-12|12] "deg"  MGW
 SG_ PF_CMRObj09ID : 23|8@0+ (1,0) [1|250] "unique object ID 1...250 (repeat"  MGW
 SG_ PF_CMRObj09HorPosRight : 27|12@0+ (0.02,-40) [-40|40] "deg"  MGW
 SG_ PF_CMRObj09HorSpeedSign : 28|1@0+ (1,0) [0|1] ""  MGW
 SG_ PF_CMRObj09HorPosLeft : 43|12@0+ (0.02,-40) [-40|40] "deg"  MGW
 SG_ PF_CMRObj09Type : 47|4@0+ (1,0) [0|15] ""  MGW
 SG_ PF_CMRObj09Dist : 63|8@0+ (2,0) [0|500] "m"  MGW

BO_ 822 PF_CMRLightObject06: 8 FVC
 SG_ PF_CMRObj06HorSpeed : 7|8@0+ (0.1,0) [0|25] "deg/s"  MGW
 SG_ PF_CMRObj06VerPos : 15|8@0+ (0.1,-12) [-12|12] "deg"  MGW
 SG_ PF_CMRObj06ID : 23|8@0+ (1,0) [1|250] "unique object ID 1...250 (repeat"  MGW
 SG_ PF_CMRObj06HorPosRight : 27|12@0+ (0.02,-40) [-40|40] "deg"  MGW
 SG_ PF_CMRObj06HorSpeedSign : 28|1@0+ (1,0) [0|1] ""  MGW
 SG_ PF_CMRObj06HorPosLeft : 43|12@0+ (0.02,-40) [-40|40] "deg"  MGW
 SG_ PF_CMRObj06Type : 47|4@0+ (1,0) [0|15] ""  MGW
 SG_ PF_CMRObj06Dist : 63|8@0+ (2,0) [0|500] "m"  MGW

BO_ 2015 Diag_func_req: 8 MGW
 SG_ Diag_func_req : 7|64@0+ (1,0) [0|1.8446744074E+19] ""  FVC

CM_ SG_ 1983 DBC_VersionIdMinor "Version information of the interface. e. g. version 1.0: Major = 1. ISO 23150:2022(E): Interface version ID {major, minor, patch} (A.1.1)";
CM_ SG_ 1983 DBC_VersionIdMajor "Version information of the interface. e. g. version 1.0: Major = 1. ISO 23150:2022(E): Interface version ID {major, minor, patch} (A.1.1)";
CM_ SG_ 446 CameraStatus "The current status of the forward looking camera";
CM_ SG_ 18 ABSMode "ABS active status. Indicates when the ABS system is modulating the valves.";
CM_ SG_ 18 DSCActivityStatus "DSC active status. When DSC is active, all gear shifting will be inhibited.";
CM_ SG_ 18 TCSSwitchSports "This signal indicates when the Traction and Yaw Control functions have been inhibited via the on/off switch. It is NOT set by a system malfunction.";
CM_ SG_ 18 TractionControlActive "Indicates the activity of the Traction Control function.";
CM_ SG_ 18 TractionControlFault "Indicates a fault with the Traction Control System.";
CM_ SG_ 18 YawControlFault "Indicates a Yaw Control Fault in the DSC
Replaces DSCFaultStatus.";
CM_ SG_ 11 ABSFault "Indicates a Fault with the Anti-Lock Braking System.";
CM_ SG_ 11 YawRate "This signal represents the yaw rate of the vehicle. The value of yaw rate is positive in a right (clockwise) turn.";
CM_ SG_ 264 GSAPosStatus "Actual PRNDS Position of the vehicle Transmission (simplified version of GSAPositionDisplay)";
CM_ SG_ 17 ABSAliveCounter "This counter forms part of a safety-related signal group.
It is incremented by the task which generates the data set used in the CRC calculation, and may be used to determine the health of the data generation task.
Refer to STJLR 18.036 for more detail.";
CM_ SG_ 17 ABSChecksum "This CRC shall be calculated in compliance with STJLR 18.036 Version 5.
The Data Segment Polynomial shall be constructed from the details
in the network configuration file.";
CM_ SG_ 17 ABSEngVacReq "1 bit signal used to indicate that ABS is unable to generate any/ sufficient brake vacuum using the electric vacuum pump, and that the engine will need to generate brake vacuum itself.";
CM_ SG_ 17 ABSPwrTrnTorqReq "This is a renaming action for ABSReqEngRunning to give clarity of the intent of this signal.
It does not mean that the internal combustion engine must be running, rather it means that the powertrain torque must be available to the driver. This may be achieved by the internal combustion engine, or an e-machine, and the transmission";
CM_ SG_ 17 BrakePressure "Non Hybrid: The signal informs about the pressure in the master cylinder.
Hybrid: Indicates the pressure that would be present at the master cylinder for the same total
brake torque delivered by the HEV braking system compared to a conventional braking system.
Note: The signal saturates at 204.6 bar. The actual brake pressure can exceed 204.6 bar.";
CM_ SG_ 17 BrakePressureQF "Quality factor for the signal BrakePressure.";
CM_ SG_ 17 VehicleSpeedQF "Quality factor for the signal VehicleSpeed. EuCD compliant signal.";
CM_ SG_ 268 HillDescentMode "To inform ECM; TCM about actual HDC function status.";
CM_ SG_ 268 VehMovementChecksum "This CRC shall be calculated in compliance with STJLR 18.036 Version 5.
The Data Segment Polynomial shall be constructed from the details in the network configuration file.";
CM_ SG_ 268 VehMovementCounter "This counter forms part of a safety-related signal group.
It is incremented by the task which generates the data set used in the CRC calculation, and may be used to determine the health of the data generation task.
Refer to STJLR 18.036 for more detail.";
CM_ SG_ 268 VehMovementDirection "This signal indicates whether the vehicle is moving forwards or backwards.
Shall always be set to 0 on vehicles with no directional wheel speed sensors.";
CM_ SG_ 268 VehMovementStatus "This flag indicates whether or not the vehicle is moving";
CM_ SG_ 268 WheelDirectionFL "This signal denotes the rotational direction of the Front Left Wheel.
Always 0 on vehicles without directional wheelspeed sensors.";
CM_ SG_ 268 WheelDirectionFR "This signal denotes the rotational direction of the Front Right Wheel.
Always 0 on vehicles without directional wheelspeed sensors.";
CM_ SG_ 268 WheelDirectionRL "This signal denotes the rotational direction of the Rear Left Wheel.
Always 0 on vehicles without directional wheelspeed sensors.";
CM_ SG_ 268 WheelDirectionRR "This signal denotes the rotational direction of the Rear Right Wheel.
Always 0 on vehicles without directional wheelspeed sensors.";
CM_ SG_ 237 WheelSpeedFrGpCounter "This counter forms part of a safety-related signal group.
It is incremented by the task which generates the data set used in the CRC calculation, and may be used to determine the health of the data generation task.
Refer to STJLR 18.036 for more detail.";
CM_ SG_ 237 WheelSpeedFrGpCS "This CRC shall be calculated in compliance with STJLR 18.036 Version 5.
The Data Segment Polynomial shall be constructed from the details in the network configuration file.";
CM_ SG_ 237 WheelSpeedFrLQF "Quality factor for WheelSpeedFrL.";
CM_ SG_ 237 WheelSpeedFrRQF "Quality factor for WheelSpeedFrR.";
CM_ SG_ 240 WheelSpeedReGpCounter "This counter forms part of a safety-related signal group.
It is incremented by the task which generates the data set used in the CRC calculation, and may be used to determine the health of the data generation task.
Refer to STJLR 18.036 for more detail.";
CM_ SG_ 240 WheelSpeedReGpCS "This CRC shall be calculated in compliance with STJLR 18.036 Version 5.
The Data Segment Polynomial shall be constructed from the details in the network configuration file.";
CM_ SG_ 240 WheelSpeedReLQF "Quality factor for WheelSpeedReL.";
CM_ SG_ 240 WheelSpeedReRQF "Quality factor for WheelSpeedReR.";
CM_ SG_ 255 CarMode "Information about which Carmode the vehicle is in i.e. Normal, factory etc.";
CM_ SG_ 255 DirectionIndicationSwitch "Status of the Direction Indication Switch.";
CM_ SG_ 255 MainBeamIndication "This signal identifies the status of the main  beam lamps.";
CM_ SG_ 255 PowerMode "Information of current PowerMode, reflects the current  state of the Power Mode Superviser
For L538:
The signals PowerModeHS, PowerModeHSQF & PowerModeComp are all with the group PowerModeGrpHS. This grouping is to ensure that the signals are packed within the same frame, they are not treated as a group within the BCM.";
CM_ SG_ 255 RunningStandby "Signal indicates whether the engine is in Eco Stop or not";
CM_ SG_ 230 LDWSwitchReq "Position of the LDW hardwired switch.";
CM_ SG_ 230 LowBeamIndication "This signal identifies the status of the low  beam lamps.";
CM_ SG_ 270 SuspensionHeightFL "Filtered signal from front left air suspension height sensor";
CM_ SG_ 270 SuspensionHeightFR "Filtered signal from front right air suspension height sensor";
CM_ SG_ 270 SuspensionHeightRL "Filtered signal from rear left air suspension height sensor";
CM_ SG_ 270 SuspensionHeightRR "Filtered signal from rear right air suspension height sensor";
CM_ SG_ 43 AIR_ControlStatus "This signal indicates the control status of the air suspension system in terms of lifting and lowering.";
CM_ SG_ 43 AIR_SuspensionMode "This signal indicates the suspension mode that the air suspension is in.";
CM_ SG_ 88 TSRCountry "Current Country determined by TSR Function";
CM_ SG_ 266 DADCFuncStatus "This is used to indicate at a functional level the status of the DADC.";
CM_ SG_ 253 RWSAngleDmd "Final arbitrated angle request";
CM_ SG_ 253 RWSAngleDmdPDC "Final arbitrated angle request without the return to zero function included.  Used to drive the trajectroy lines in the HMI.";
CM_ SG_ 253 RWSFaultAngle "Feedback to IPC that the RWS System has failed non-zero angle";
CM_ SG_ 253 RWSFaultStraight "Feedback to IPC that the RWS System has failed at zero degrees";
CM_ SG_ 253 RWSLinRngeAngleDmd "RWS angle demand that only includes the liniar range behaviour of bicycle models.  Used for modification of external target yaw rate models";
CM_ SG_ 253 RWSMotTypeServeLat "Motion type served from the RWS System
Lat = Lateral Motion";
CM_ SG_ 253 RWSMotTypeServeLong "Motion type served from the RWS System
Long = Longitudinal Motion";
CM_ SG_ 253 RWSMotTypeServeLvl "Motion type served from the RWS System
Level = Autonomous Level";
CM_ SG_ 253 RWSMotTypeServeMode "Motion type served from the RWS System
Mode = Autonomous Mode";
CM_ SG_ 253 RWSSysAliveCnt1 "This counter forms part of a safety-related signal group.
It is incremented by the task which generates the data set used in the CRC calculation, and may be used to determine the health of the data generation task.
Refer to STJLR 18.036 for more detail.";
CM_ SG_ 253 RWSSysCS1 "This CRC shall be calculated in compliance with STJLR 18.036 Version 5.
The Data Segment Polynomial shall be constructed from the details";
CM_ SG_ 254 DADCRWSAngleReq "RWS angle request from DADC (ADAS Features)";
CM_ SG_ 254 DrvLimRWSAct "Feedback of DrvLimRWSReq switch to inform IMC that the RWS system has been limited";
CM_ SG_ 254 RWSAngleAct "RWS actual angle";
CM_ SG_ 254 RWSStrkeDmd "Final arbitrated stroke request from ABS to RWS actuator";
CM_ SG_ 254 RWSSysAliveCnt2 "This counter forms part of a safety-related signal group.
It is incremented by the task which generates the data set used in the CRC calculation, and may be used to determine the health of the data generation task.
Refer to STJLR 18.036 for more detail.";
CM_ SG_ 254 RWSSysCS2 "This CRC shall be calculated in compliance with STJLR 18.036 Version 5.
The Data Segment Polynomial shall be constructed from the details";
CM_ SG_ 254 RWSSysStats "Status of RWS system and controller";
CM_ SG_ 254 RWSTerrainModeExt "TR mode activation in RWS";
CM_ SG_ 254 RWSTerrChngModeStatus "Availability of RWS to change mode";
CM_ SG_ 254 RWSTRConfig "Feedback of selected configurable TR mode from RWS system";
CM_ SG_ 416 CustomerSymptomIPMA "Informs the application as to whether a customer symptom would be seen or not.";
CM_ SG_ 277 TerrainModeReqExt "The 'Drive mode' or 'Terrain mode' selected by the driver. (Jaguar Drive Control and Land Rover Terrain Response)";
CM_ SG_ 104 HBSeg0LT "High beam segment 0 LT";
CM_ SG_ 104 HBSeg0RT "High beam segment 0 RT";
CM_ SG_ 104 HBSeg1LT "High beam segment 1 LT";
CM_ SG_ 104 HBSeg1RT "High beam segment 1 RT";
CM_ SG_ 104 HBSeg2LT "High beam segment 2 LT";
CM_ SG_ 104 HBSeg2RT "High beam segment 2 RT";
CM_ SG_ 104 HBSeg3LT "High beam segment 3 LT";
CM_ SG_ 104 HBSeg3RT "High beam segment 3 RT";
CM_ SG_ 104 HBSeg4LT "High beam segment 4 LT";
CM_ SG_ 104 HBSeg4RT "High beam segment 4 RT";
CM_ SG_ 104 HBSeg5LT "High beam segment 5 LT";
CM_ SG_ 104 HBSeg5RT "High beam segment 5 RT";
CM_ SG_ 104 HBSeg6LT "High beam segment 6 LT";
CM_ SG_ 104 HBSeg6RT "High beam segment 6 RT";
CM_ SG_ 104 HBSeg7LT "High beam segment 7 LT";
CM_ SG_ 104 HBSeg7RT "High beam segment 7 RT";
CM_ SG_ 104 HBSeg8LT "High beam segment 8 LT";
CM_ SG_ 104 HBSeg8RT "High beam segment 8 RT";
CM_ SG_ 104 HBSeg9LT "High beam segment 9 LT";
CM_ SG_ 104 HBSeg9RT "High beam segment 9 RT";
CM_ SG_ 104 HighBeamStatus "High beam status";
CM_ SG_ 104 LowBeamStatus "Low beam status";
CM_ SG_ 106 ADBHorEdgeLT "ADB left beam angle";
CM_ SG_ 106 ADBHorEdgeRT "ADB right beam angle";
CM_ SG_ 106 LaserStatus "Laser status";
CM_ SG_ 106 LBStatus "AFS status";
CM_ SG_ 106 LightDist "Light distrubition";
CM_ SG_ 301 AFSLightDist_b "AFS light distrubition";
CM_ SG_ 301 AFSPHBAngleLT_b "AFS left beam angle";
CM_ SG_ 301 AFSPHBAngleRT_b "AFS right beam angle";
CM_ SG_ 301 AFSStatus_b "AFS status";
CM_ SG_ 439 DisttoNextJunct "Distance to the Next Junction.
Units to be used from the NavSpeedLimitUnits signal.";
CM_ SG_ 439 HandOfTrafficReq "User request to configure the Auto High Beam Control module for vehicle driven on the left hand side or the right hand side of the road";
CM_ SG_ 439 InBuiltArea "Signal indicates if the vehicle is in an Inbuilt area";
CM_ SG_ 439 NavCountryCode "Current Country set in the NAV";
CM_ SG_ 439 NavCurrRoadType "Current Road type";
CM_ SG_ 439 NavCurrState "Current State as reported by Navigation if Country code indicates US, Canada or Australia";
CM_ SG_ 439 NavSpdLimit "Speed Limit value from NAV";
CM_ SG_ 439 NavSpdLimitStatus "Speed of speed limit from Nav";
CM_ SG_ 439 NavSpdLimitUnits "Speed limit units from navigation data";
CM_ SG_ 439 NumberofExitLanes "Signal indicates the Number of Exit lanes";
CM_ SG_ 439 NumberofLanes "Number of Lanes in the driving Direction";
CM_ SG_ 439 RightOfWay "Indicates if the vehicle has right of way at a junction";
CM_ SG_ 186 AutoHighBeamSAEModeReq "User request to configure the Auto High Beam Control for SAE mode sensitivity";
CM_ SG_ 318 IPCAliveCnt "This signal is used by other ECU's to monitor the IPC. It will increment by 1 every 20ms. When the value of 15 is reached, it will reset to 0 on the next cycle";
CM_ SG_ 132 BrakeSwitchStatus "Indicates status and fault condition of brake pedal.";
CM_ SG_ 132 EMSAliveCounter "This counter forms part of a safety-related signal group.
It is incremented by the task which generates the data set used in the CRC calculation, and may be used to determine the health of the data generation task.
Refer to STJLR 18.036 for more detail.";
CM_ SG_ 132 EMSChecksum "This CRC shall be calculated in compliance with STJLR 18.036 Version 5.
The Data Segment Polynomial shall be constructed from the details
in the network configuration file.";
CM_ SG_ 132 EngineSpeed "Instantaneous Crank shaft speed, not corrected for flywheel tolerances and not smoothed.";
CM_ SG_ 132 EngineSpeedQF "Quality Factor for 'EngineSpeed'";
CM_ SG_ 132 MHStopStartStatus "L538:
Status of the Eco-Start Stop-Start Feature";
CM_ SG_ 132 PowerPackStatus "Describes the state of the powerpack";
CM_ SG_ 54 PedalPosPro "'Driver demanded accelerator pedal position in %.
Kick-down indication is NOT included in the signal encoding.'";
CM_ SG_ 54 PedalPosProAliveCounter "This counter forms part of a safety-related signal group.
It is incremented by the task which generates the data set used in the CRC calculation, and may be used to determine the health of the data generation task.
Refer to STJLR 18.036 for more detail.";
CM_ SG_ 54 PedalPosProChecksum "This CRC shall be calculated in compliance with STJLR 18.036 Version 5.
The Data Segment Polynomial shall be constructed from the details in the network configuration file.";
CM_ SG_ 54 PedalPosProQF "Quality factor for the signal PedalPosPro.";
CM_ SG_ 13 VSCHoldRequest "This signal requests the ABS Roll Back Protection function to be activated i.e. the foundation brakes are requested to hold the vehicle.";
CM_ SG_ 13 WheelTorqTgtGpCounter "This counter forms part of a safety-related signal group.
It is incremented by the task which generates the data set used in the CRC calculation, and may be used to determine the health of the data generation task.
Refer to STJLR 18.036 for more detail.";
CM_ SG_ 13 WheelTorqTgtGpCS "This CRC shall be calculated in compliance with STJLR 18.036 Version 5.
The Data Segment Polynomial shall be constructed from the details in the network configuration file.";
CM_ SG_ 13 WheelTorqTgtWoIntF "This is the 'long term' target front wheels torque. This includes driver demand (accelerator pedal) , vehicle motion control functions (i.e. cruise, ACC, ASL, vehicle speed limitation), and long term torque limitations  & offsets (i.e. driveline protection)
This request excludes short term interventions (i.e. Traction Control, Shift Energy Management).
Inertial terms are not included / compensated for (steady state speed is assumed).";
CM_ SG_ 13 WheelTorqTgtWoIntR "This is the 'long term' target rear wheels torque. This includes driver demand (accelerator pedal) , vehicle motion control functions (i.e. cruise, ACC, ASL, vehicle speed limitation), and long term torque limitations  & offsets (i.e. driveline protection)
This request excludes short term interventions (i.e. Traction Control, Shift Energy Management).
Inertial terms are not included / compensated for (steady state speed is assumed).";
CM_ SG_ 46 EPASDrvDmdExcess_dup "This signal indicates whether level of driver activity exceeds the threshold for excessive steering:, 0 = Driver Steering activity not excessive, 1 = Driver Steering activity excessive";
CM_ SG_ 46 TorsionBarTorque "EPAS torque sensor value (absolute driver steering torque). This value shall be used by Tow Assist Feature to determine the driver intervention.";
CM_ SG_ 46 TorsionBarTorqueCS "This CRC shall be calculated in compliance with STJLR 18.036 Version 5.
The Data Segment Polynomial shall be constructed from the details in the network configuration file.";
CM_ SG_ 46 TorsionBarTorqueCtr "This counter forms part of a safety-related signal group.
It is incremented by the task which generates the data set used in the CRC calculation, and may be used to determine the health of the data generation task.
Refer to STJLR 18.036 for more detail.";
CM_ SG_ 46 TorsionBarTorqueSign "Indicates the direction of Torsion Bar Torque";
CM_ SG_ 50 ActRoadWheelAngState "State of signal ActRoadWheelAngleValue";
CM_ SG_ 50 ActRoadWheelAngValue "Actual Road Wheel Angle";
CM_ SG_ 191 DrivSeatBeltBcklError "When the bit is set to a '1', a fault condition exists for the driver's seat belt buckle switch.";
CM_ SG_ 191 DrivSeatBeltBcklState "When the bit is set to a '1', the driver's seat belt buckle is latched.
This signal will be invalid and set to 1 (latched) during proveout and should not be used by subscriber until the valid state is established at 1sec post ignition on PM6";
CM_ SG_ 74 A1 "Beschleunigung 1 (Lateral Acceleration 1). Positive value when vehicle is in a left hand turn. Units of m/sec2.
See IMU bus spec. for details";
CM_ SG_ 74 A1_STAT "Status Beschleunigung 1 (Lateral Acceleration 1 Status)
Indicates the status of the Lateral Acceleration 1 signal, A1:
XXX1 = sensor element not populated
XX1X = signal faulty
X1XX = sensor initialising
1XXX = sensor channel not calibrated
See IMU bus spec. for details";
CM_ SG_ 74 CLU_STAT "Clusterstatus (Sensor Status). NOT SUPPORTED. Unused signal from standard IMU sensor signal set.
See IMU bus spec. for details";
CM_ SG_ 74 CRC1 "This CRC shall be calculated in compliance with STJLR 18.036 Version 5.
The Data Segment Polynomial shall be constructed from the details in the network configuration file.";
CM_ SG_ 74 MSG_CNT1 "This counter forms part of a safety-related signal group.
It is incremented by the task which generates the data set used in the CRC calculation, and may be used to determine the health of the data generation task.
Refer to STJLR 18.036 for more detail.";
CM_ SG_ 74 PSIP1 "Gierrate 1 (Yaw Rate 1). Positive value when vehicle is in a left hand turn. Units of Grad/sec, 1 Grad = 1/400th of a full circle.
See IMU bus spec. for details";
CM_ SG_ 74 PSIP1_STAT "Status Gierrate 1 (Yaw Rate 1 Status).
Indicates the status of the Yaw Rate 1 signal, PSIP1:
XXX1 = sensor element not populated
XX1X = signal faulty
X1XX = sensor initialising
1XXX = sensor channel not calibrated
See IMU bus spec. for details";
CM_ SG_ 76 A2 "Beschleunigung 2 (Longitudinal Acceleration). Positive value when vehicle is accelerating forwards. Units of m/sec2.
See IMU bus spec. for details";
CM_ SG_ 76 A2_STAT "Status Beschleunigung 2 (Longitudinal Acceleration Status).
Indicates the status of the Longitudinal Acceleration signal, A2:
XXX1 = sensor element not populated
XX1X = signal faulty
X1XX = sensor initialising
1XXX = sensor channel not calibrated
See IMU bus spec. for details";
CM_ SG_ 76 CRC2 "This CRC shall be calculated in compliance with STJLR 18.036 Version 5.
The Data Segment Polynomial shall be constructed from the details in the network configuration file.";
CM_ SG_ 76 MSG_CNT2 "This counter forms part of a safety-related signal group.
It is incremented by the task which generates the data set used in the CRC calculation, and may be used to determine the health of the data generation task.
Refer to STJLR 18.036 for more detail.";
CM_ SG_ 76 PSIPP1 "Gierbeschleunigung 1 (Yaw Angular Acceleration 1). NOT SUPPORTED. Unused signal from standard IMU sensor signal set.
See IMU bus spec. for details";
CM_ SG_ 76 PSIPP1_STAT "Status Gierbeschleunigung 1 (Yaw Angular Acceleration 1 Status).
Indicates the status of the Yaw Angular Acceleration 1 signal, PSIPP1:
XXX1 = sensor element not populated
XX1X = signal faulty
X1XX = sensor initialising
1XXX = sensor channel not calibrated
Set to XXX1 as PSIPP1 is not supported.
See IMU bus spec. for details";
CM_ SG_ 86 SteeringWheelAngleCS "This CRC shall be calculated in compliance with STJLR 18.036 Version 5.
The Data Segment Polynomial shall be constructed from the details in the network configuration file.";
CM_ SG_ 86 SteeringWheelAngleSpeed "Steering Wheel Rotation Speed.";
CM_ SG_ 86 SteeringWheelAngleStatus "2-bit signal relating to SteeringWheelAngleUnsigned. This flag indicates progress with the Learn Centre Algorithm. This signal will indicate a value of 1 (Centre not learned) at the start of every ignition cycle before the algorithm has had a chance to run. As the algorithm runs to completion, the value will increment to 3. Certain exceptional conditions may cause the algorithm to re-run mid-igntion cycle. A fault with the sensor is indicated by a value of 0.";
CM_ SG_ 86 SteeringWheelAngMsgCnt "This counter forms part of a safety-related signal group.
It is incremented by the task which generates the data set used in the CRC calculation, and may be used to determine the health of the data generation task.
Refer to STJLR 18.036 for more detail.";
CM_ SG_ 86 SteeringWheelRotDir "This signal indicates the direction of steering wheel rotation.";
CM_ SG_ 397 DemandHeight "Filtered signal from air suspension indicating target vehicle height. Maximum value is defined as an error marker.";
CM_ SG_ 397 EstimatedHeight "Estimated signal from air suspension indicating current vehicle average height during height changes. Maximum value is defined as an error marker.";
CM_ SG_ 397 THETAP "Nickrate (Pitch Rate). Positive value when vehicle is slowing down. Units of Grad/sec, 1 Grad = 1/400th of a full circle.
See IMU bus spec. for details";
CM_ SG_ 399 CountryCode "ASCII code of actual country";
CM_ SG_ 399 VCGStatus "Vehicle clearance guidance feature enable/ disable status";
CM_ SG_ 655 AmbTempImpr "An improved version of the measured ambient temperature. range -57..+70 degree C";
CM_ SG_ 655 ExteriorLightSwitchPos2 "New exterior light switch position LIN signal required from SWM to BCM LIN_1
Additional value required for new 5 position switch (current switch has 4 positions and uses a 2 bit signal)";
CM_ SG_ 655 MainBeamSwitch "This signal MainBeamSwitch is sending to ExtriorLightControl object when the Driver/User have manoeuvred the MainBeamSwitch control in position Neutral, Flash and Toggle.";
CM_ SG_ 655 WasherFrontCmd_EUCD "Controls washing of the windscreen.
Wiper stalk command for: windscreen washing.";
CM_ SG_ 655 WasherRearCmd "Controls washing of the rear window.
Wiper stalk command for: rear screen washing.";
CM_ SG_ 655 WiperFrontCmd_EuCD "Controls front wiper.";
CM_ SG_ 655 WiperRearCmd "Wiper stalk command for: rear wiper.";
CM_ SG_ 655 WiperStatus "Specifies the current operating status of the front wiper system.";
CM_ SG_ 245 ATPCProStatus "Publish the current status of ATPCPro";
CM_ SG_ 836 ActualTyrePressureFL "Signal to transmit front left tyre pressure.Value 0xFF should be considered as INVALID.";
CM_ SG_ 836 ActualTyrePressureFR "Signal to transmit front right tyre pressure.Value 0xFF should be considered as INVALID.";
CM_ SG_ 836 ActualTyrePressureRL "Signal to transmit rear left tyre pressure.Value 0xFF should be considered as INVALID.";
CM_ SG_ 836 ActualTyrePressureRR "Signal to transmit rear right tyre pressure.Value 0xFF should be considered as INVALID.";
CM_ SG_ 80 KeepNetInAfterRunTCM "CAN signal stating if the network is required for After-Run.
Description of bit field detailing each application function to be stored in the DID (After-Run Function 1- 16):
Bit 0: output speed condition (n_ab)
Bit 1: position condition (PosPRND)
Bit 2: timer condition 1(tmr_PowerDown)
Bit 3: timer condition 2 (tmr_PowerDownLong)
Bit 4: SbW Display Timer condition
Bit 5 - 15: Fixwert: 0x00";
CM_ SG_ 80 TCMLockETSReq "Used to Lock ETS for shiftlock functionality and for locking ETS in the event of transmission failure.";
CM_ SG_ 80 TCMParkReqAck "Used to inform the ETS that the TCM is processing a shift request into Park, used to check validity. Max normal shift time 0.1s. Max Shift time to Park 0.4Sec.";
CM_ SG_ 80 TCMPosAliveCounter "This counter forms part of a safety-related signal group.
It is incremented by the task which generates the data set used in the CRC calculation, and may be used to determine the health of the data generation task.
Refer to STJLR 18.036 for more detail.";
CM_ SG_ 80 TCMPosChecksum "This CRC shall be calculated in compliance with STJLR 18.036 Version 5.
The Data Segment Polynomial shall be constructed from the details in the network configuration file.";
CM_ SG_ 80 TCMStartEnable "Bit is used to inform the ETS that the TCM is a position such that engine crank is permissible.";
CM_ SG_ 80 TCMText "The code for the current TCM Text message to be displayed.
EuCD signal name.";
CM_ SG_ 80 TransTICStatus "Used to indicate the status of transmission Idle Control functionality
This signal is provided at a QM rating only";
CM_ SG_ 1024 CcfAdasNCapESS "CCF Parameter - AdasNCapESS
MDF - 0x6585";
CM_ SG_ 1024 CcfParkAssistHMI "CCF to indicate the HMI variant
MDF = 0x5E87";
CM_ SG_ 1024 CcfAdaptDrvBeam "CCF Parameter - AdaptDrvBeam
MDF - 0x5B73";
CM_ SG_ 1024 CcfDD06PowerModePKT "Global Identifier   DD06
ID Name               Power Mode (PKT1)
Size (Bytes)          1
Type                     Packeted
Data Description   As defined in GMRDB
Parameter Size (bits) Datatype Description
1 3 State Encoded Power Mode Quality Factor   (NOT USED)
2 5 State Encoded Power Mode
(from GMRDB)
MDF 0xB074";
CM_ SG_ 1024 CcfAllWheelSteer "CCF Parameter - AllWheelSteer
MDF - 0x7077";
CM_ SG_ 1024 CcfDD05OutdoorTemp "Global Identifier   DD05
ID Name               Outdoor Temperature
Size (Bytes)          1
Type                     Unsigned Numeric
Data Description   As defined in GMRDB
MDF 0xB167";
CM_ SG_ 1024 CcfDD02MainECUSupVolts "Global Identifier   DD02
ID Name               Main ECU Supply Voltage
Size (Bytes)          1
Type                     Unsigned Numeric
Data Description   As defined in GMRDB
MDF 0xB067";
CM_ SG_ 1024 CcfDD04InCarTemp "Global Identifier   DD04
ID Name               In-Car Temperature
Size (Bytes)          1
Type                     Unsigned Numeric
Data Description   As defined in GMRDB
MDF 0xB157";
CM_ SG_ 1024 CcfAdapDrvBeamSeg "CCF Parameter - AdapDrvBeamSeg
MDF - 0x6557";
CM_ SG_ 1024 CcfVINPart1 "Car Configuration - VIN Part 1
VIN Character 1 (Geographic Area)
VIN Character 2 (Country)
VIN Character 3 (Manufacturer)
VIN Character 4 (Market/Specification)
Payload MDF = 0x5757, 0x5767, 0x5777, 0x5787";
CM_ SG_ 1024 ccfGenericWheelBase "Car Configuration - Generic Wheel Base
Payload MDF = 0x5747";
CM_ SG_ 1024 CcfSportbrake "CCF to indicate whether the vehicle is sportbrake or not
MDF = 0x5547";
CM_ SG_ 1024 CcfSuspensionType "CCF Parameter - SuspensionType
MDF - 0x6233";
CM_ SG_ 1024 CcfVehClearGuidance "CCF Parameter - VehClearGuidance
MDF - 0x7337";
CM_ SG_ 1024 CcfAHBSensitivtyMenu "CCF Parameter - AHBSensitivtyMenu
MDF - 0x6E37";
CM_ SG_ 1024 CcfAHBCalibration "CCF Parameter - AHBCalibration
MDF - 0x6D37";
CM_ SG_ 1024 CcfGlassType "Car Configuration - Glass Type
Payload MDF = 0x0A37";
CM_ SG_ 1024 CcfHeatedWindscreen "Car Configuration - HEATED WINDSCREEN
Payload MDF = 0x0937";
CM_ SG_ 1024 CcfHUDSubType "CCF Parameter - HUDSubType
MDF - 0x6025";
CM_ SG_ 1024 CcfDD01TotalDistance "Global Identifier   DD01
ID Name               Total Distance
Size (Bytes)          3
Type                     Unsigned Numeric
Data Description   As defined in GMRDB
Resolution ref: 1  Resolution: 1.0
Numeric size (bits): 24
Offset: 0.0
Minimum value: 0.0  Maximum value: 1.6777215E7
Unit: km
MDF 0xB127";
CM_ SG_ 1024 CcfDD00GlobalRealTime "Global Identifier   DD00
ID Name               Global Real Time
Size (Bytes)          4
Type                     Unsigned Numeric
Data Description   As defined in GMRDB
Resolution ref: 1/600  Resolution: 0.001666666667
Numeric size (bits): 32
Offset: 0.0
Minimum value: 0.0  Maximum value: 7158278.825
Unit: min
(from GMRDB)
MDF 0xB027";
CM_ SG_ 1024 CcfAHBSystemStatus "CCF Parameter - AHBSystemStatus
MDF - 0x6C27";
CM_ SG_ 1024 CcfVINPart3 "Car Configuration - VIN Part 3
VIN Character 12 (Serial Number 1)
VIN Character 13 (Serial Number 2)
VIN Character 14 (Serial Number 3)
VIN Character 15 (Serial Number 4)
VIN Character 16 (Serial Number 5)
VIN Character 17 (Serial Number 6)
Payload MDF = 0x5927,  0x5937, 0x5947, 0x5957, 0x5967, 0x5977";
CM_ SG_ 1024 CcfVINPart2 "Car Configuration - VIN Part 2
VIN Character 5 (Transmission & Steering)
VIN Character 6 (Model Range)
VIN Character 7 (Model Range)
VIN Character 8 (Emission Control System)
VIN Character 9 (Check Digit)
VIN Character 10 (Model Year)
VIN Character 11 (Assembly Plant & Model Line)
Payload MDF = 0x0x5827, 0x5837, 0x5847, 0x5857, 0x5867, 0x5877, 0x5887";
CM_ SG_ 1024 CcfSteeringWheelPosn "Car Configuration - Steering Wheel Position
Payload MDF = 0x0227";
CM_ SG_ 1024 CcfVehicleType "Car Configuration - Vehicle Type
Payload MDF = 0x0127";
CM_ SG_ 321 ADAS_Stub_PartOfCalcRoute "Whether segment is part of calculated route";
CM_ SG_ 321 ADAS_Stub_FuncRoadClass "Functional class of the segment";
CM_ SG_ 321 ADAS_Stub_LastStub "Indicates that this STUB message is the last one that refers to given path and offset; if false more STUB messages for this offset will be sent.";
CM_ SG_ 321 ADAS_Stub_Update "Value true indicates that this message contains updated information of already transmitted STUB.";
CM_ SG_ 321 ADAS_Stub_SubPathIdx "This is Index of new path.";
CM_ SG_ 321 ADAS_Stub_Retr "If true, this message was sent already at least once before";
CM_ SG_ 321 ADAS_Stub_PathIdx "This is Index of parent path.";
CM_ SG_ 321 ADAS_Stub_Offset "Offset of position of the first profile spot from start position modulo 8191. Offset 8191 is invalid.";
CM_ SG_ 321 ADAS_Stub_NumOfLaneOppDir "Number of lanes in opposite direction. 0 denotes one-direction road, 1 for one lane only; 2 indicates 2 or more lanes.
Value 3 means unknown.";
CM_ SG_ 321 ADAS_Stub_NumOfLaneDrvDir "Number of lanes in driving direction: also implies driving direction. 0 denotes driving in wrong direction, 1-5 are verbatim values, and 6 indicate 6 or more lanes.
Value 7 means unknown.";
CM_ SG_ 321 ADAS_Stub_MsgType "Used for multiplexed ADASIS messages or for verification purposes. See value descriptions for details";
CM_ SG_ 321 ADAS_Stub_FormOfWay "Describes the form of way of the stub. See value descriptions for details";
CM_ SG_ 321 ADAS_Stub_CycCnt "Cyclic counter of this message type: reconstructor can use this value to detect missing messages";
CM_ SG_ 321 ADAS_Stub_RtOfWay "Whether this stub has the right of way. See value descriptions for details";
CM_ SG_ 321 ADAS_Stub_CmplxInsct "Describes whether stub is part of a complex intersection";
CM_ SG_ 321 ADAS_Stub_RelProbb "Relative probability of the path on the crossing: continuation of the path at an intersection can be calculated as 100 - sum (probability of all stubs)
Value 0 indicates that turn is not allowed.
Value 30 is not allowed.
Value 31 means unknown";
CM_ SG_ 321 ADAS_Stub_TurnAngl "Turn angle of the stub
0 = straight
90 = right turn
180 = U-turn
270 = left turn
etc";
CM_ SG_ 793 EPS_LatDrvLvl12SrvAvl "Lateral level 12 driving service availability";
CM_ SG_ 793 EPS_IntRPCMinTrq "Minimum internally allowed RPC torque for Level 2 (safety limit)(TBT level)";
CM_ SG_ 793 EPS_IntRPCMaxTrq "Maximum internally allowed RPC torque for Level 2 (safety limit)(TBT level)";
CM_ SG_ 323 ADAS_Seg_PartOfCalcRoute "Whether segment is part of calculated route";
CM_ SG_ 323 ADAS_Seg_RelProbb "Relative probability of the path on the crossing: continuation of the path at an intersection can be calculated as 100 - sum (probability of all stubs)
Value 0 indicates that turn is not allowed.
Value 30 is not allowed.
Value 31 means unknown";
CM_ SG_ 323 ADAS_Seg_Offset "Offset of position of the first profile spot from start position modulo 8191. Offset 8191 is invalid.";
CM_ SG_ 323 ADAS_Seg_Retr "If true, this message was sent already at least once before";
CM_ SG_ 323 ADAS_Seg_PathIdx "Index of current path: If this number differs from one specified in previous SEGMENT message, vehicle left the original path
Indices 0-7 have special meaning: see value descriptions for details";
CM_ SG_ 323 ADAS_Seg_MsgType "Used for multiplexed ADASIS messages or for verification purposes. See value descriptions for details";
CM_ SG_ 323 ADAS_Seg_FormOfWay "Describes the form of way of the segment. See value descriptions for details";
CM_ SG_ 323 ADAS_Seg_CycCnt "Cyclic counter of this message type: reconstructor can use this value to detect missing messages";
CM_ SG_ 323 ADAS_Seg_CmplxInsct "Whether segment is part of a complex intersection";
CM_ SG_ 323 ADAS_Seg_BuildUpArea "Whether segment is part of a build-up area (driving in city)";
CM_ SG_ 323 ADAS_Seg_DividedRoad "Whether segment is part of a divided road";
CM_ SG_ 323 ADAS_Seg_Bridge "Whether segment is part of a bridge";
CM_ SG_ 323 ADAS_Seg_Tunnel "Whether segment is part of a tunnel";
CM_ SG_ 323 ADAS_Seg_NumOfLaneOppDir "Number of lanes in opposite direction. 0 denotes one-direction road, 1 for one lane only; 2 indicates 2 or more lanes.
Value 3 means unknown.";
CM_ SG_ 323 ADAS_Seg_NumOfLaneDrvDir "Number of lanes in driving direction: also implies driving direction. 0 denotes driving in wrong direction, 1-5 are verbatim values, and 6 indicate 6 or more lanes.
Value 7 means unknown.";
CM_ SG_ 323 ADAS_Seg_EffSpdLmtType "Describes what kind of Speed Limit is in effect. See value descriptions for details";
CM_ SG_ 323 ADAS_Seg_EffSpdLmt "Current Speed Limit: May be implicit (for instance, in cities), or explicit.
Current time of day, day of week and weather conditions are taken in account by Horizon Provider in determining effective speed limit.";
CM_ SG_ 323 ADAS_Seg_FuncRoadClass "Functional class of the segment";
CM_ SG_ 323 ADAS_Seg_Update "Value true indicates that this message contains updated information of already transmitted SEGMENT";
CM_ SG_ 289 TSRFeatureEnableSwitch "HMI switch to turn TSR features on/off.";
CM_ SG_ 327 ADAS_Posn_PosProbb "Probability of this position candidate";
CM_ SG_ 327 ADAS_Posn_PosConfdc "Position confidence: this field contain Av2HP implementation specific values. Use 0 for highest confidence, 6 for lowest confidence, 7 means SNA.";
CM_ SG_ 327 ADAS_Posn_CurLane "Current lane; for details, see value descriptions for current Lane values";
CM_ SG_ 327 ADAS_Posn_Spd "Speed of the vehicle projected to the path";
CM_ SG_ 327 ADAS_Posn_RelHead "Heading relative to path:
0 in path direction
1 .. 126: right from path direction
253 .. 128: left from link direction
127 in opposite direction
253 unknown";
CM_ SG_ 327 ADAS_Posn_Idx "If Av2HP supports positioning alternatives, contains index of this Position Candidate. Candidate 0 is always most probable position candidate,
candidate 1 second etc. If Av2HP does not support positioning alternatives, it will be always 0.";
CM_ SG_ 327 ADAS_Posn_Age "Time difference between the moment the message is sent and the moment the vehicle position is calculated by the positioning sub-system.  510 means older than 2545 ms, 511 means invalid.";
CM_ SG_ 327 ADAS_Posn_PathIdx "Index of current path: If this number differs from one specified in previous POSITION message, vehicle left the original path
Indices 0-7 have special meaning: see value descriptions for details";
CM_ SG_ 327 ADAS_Posn_Offset "Offset of current position from the current path's start point modulo 8191. Offset 8191 is invalid.";
CM_ SG_ 327 ADAS_Posn_MsgTyp "Used for multiplexed ADASIS messages or for verification purposes. See value descriptions for details";
CM_ SG_ 327 ADAS_Posn_CycCnt "Cyclic counter of this message type: reconstructor can use this value to detect missing messages";
CM_ SG_ 787 DADCBrkJrkWrnReq "Type: Boolean, 1bit
Range: [0...1]
Resolution: 1
Unit: -
Values: Type Value Scale Offset Interpretation
LogicalValue 0 Brake Jerk Warning is not requested
LogicalValue 1 Brake Jerk Warning is requested";
CM_ SG_ 800 ADAS_ExtMinRPCTrq "Minimum externally allowed RPC torque for Level 2 (TBT Level)";
CM_ SG_ 800 ADAS_ExtMaxRPCTrq "Maximum externally allowed RPC torque for Level 2 (TBT Level)";
CM_ SG_ 800 TargetSteeringAngle "Target Steering Angle requested by the MPC3 to the EPS.";
CM_ SG_ 297 ADAS_ProfLong_Retr "If true, this message was sent already at least once before";
CM_ SG_ 297 ADAS_ProfLong_PathIdx "Index of current path: If this number differs from one specified in previous PROFILE message, vehicle left the original path
Indices 0-7 have special meaning: see value descriptions for details";
CM_ SG_ 297 ADAS_ProfLong_Offset "Offset of position of the first profile spot from start position modulo 8191. Offset 8191 is invalid.";
CM_ SG_ 297 ADAS_ProfLong_MsgType "Used for multiplexed ADASIS messages or for verification purposes. See value descriptions for details";
CM_ SG_ 297 ADAS_ProfLong_CycCnt "Cyclic counter of this message type: reconstructor can use this value to detect missing messages";
CM_ SG_ 297 ADAS_ProfLong_CtrlPoint "If true, values in this message specifies additional control points required for certain interpolation types;
if false, actual profile values are specified";
CM_ SG_ 297 ProfileLong_Value "Profile value at Offset";
CM_ SG_ 297 ADAS_ProfLong_ProfType "Type of the Profile. See value descriptions for details";
CM_ SG_ 826 PF_CMRObj10HorSpeed "Forward Look Camera Light Object horizontal speed";
CM_ SG_ 826 PF_CMRObj10VerPos "Forward Look Camera Light Object vertical position";
CM_ SG_ 826 PF_CMRObj10ID "Forward Look Camera Light Object ID";
CM_ SG_ 826 PF_CMRObj10HorPosRight "Forward Look Camera Light Object horizontal position right";
CM_ SG_ 826 PF_CMRObj10HorPosLeft "Forward Look Camera Light Object horizontal position left";
CM_ SG_ 826 PF_CMRObj10Dist "Forward Look Camera Light Object distance";
CM_ SG_ 827 PF_CMRObj11HorSpeed "Forward Look Camera Light Object horizontal speed";
CM_ SG_ 827 PF_CMRObj11VerPos "Forward Look Camera Light Object vertical position";
CM_ SG_ 827 PF_CMRObj11ID "Forward Look Camera Light Object ID";
CM_ SG_ 827 PF_CMRObj11HorPosRight "Forward Look Camera Light Object horizontal position right";
CM_ SG_ 827 PF_CMRObj11HorPosLeft "Forward Look Camera Light Object horizontal position left";
CM_ SG_ 827 PF_CMRObj11Dist "Forward Look Camera Light Object distance";
CM_ SG_ 828 PF_CMRObj12HorSpeed "Forward Look Camera Light Object horizontal speed";
CM_ SG_ 828 PF_CMRObj12VerPos "Forward Look Camera Light Object vertical position";
CM_ SG_ 828 PF_CMRObj12HorPosRight "Forward Look Camera Light Object horizontal position right";
CM_ SG_ 828 PF_CMRObj12HorPosLeft "Forward Look Camera Light Object horizontal position left";
CM_ SG_ 828 PF_CMRObj12ID "Forward Look Camera Light Object ID";
CM_ SG_ 828 PF_CMRObj12Dist "Forward Look Camera Light Object distance";
CM_ SG_ 829 PF_CMRObj13HorSpeed "Forward Look Camera Light Object horizontal speed";
CM_ SG_ 829 PF_CMRObj13VerPos "Forward Look Camera Light Object vertical position";
CM_ SG_ 829 PF_CMRObj13ID "Forward Look Camera Light Object ID";
CM_ SG_ 829 PF_CMRObj13HorPosRight "Forward Look Camera Light Object horizontal position right";
CM_ SG_ 829 PF_CMRObj13HorPosLeft "Forward Look Camera Light Object horizontal position left";
CM_ SG_ 829 PF_CMRObj13Dist "Forward Look Camera Light Object distance";
CM_ SG_ 830 PF_CMRObj14HorSpeed "Forward Look Camera Light Object horizontal speed";
CM_ SG_ 830 PF_CMRObj14VerPos "Forward Look Camera Light Object vertical position";
CM_ SG_ 830 PF_CMRObj14ID "Forward Look Camera Light Object ID";
CM_ SG_ 830 PF_CMRObj14HorPosRight "Forward Look Camera Light Object horizontal position right";
CM_ SG_ 830 PF_CMRObj14HorPosLeft "Forward Look Camera Light Object horizontal position left";
CM_ SG_ 830 PF_CMRObj14Dist "Forward Look Camera Light Object distance";
CM_ SG_ 831 PF_CMRObj15HorSpeed "Forward Look Camera Light Object horizontal speed";
CM_ SG_ 831 PF_CMRObj15VerPos "Forward Look Camera Light Object vertical position";
CM_ SG_ 831 PF_CMRObj15ID "Forward Look Camera Light Object ID";
CM_ SG_ 831 PF_CMRObj15HorPosRight "Forward Look Camera Light Object horizontal position right";
CM_ SG_ 831 PF_CMRObj15HorPosLeft "Forward Look Camera Light Object horizontal position left";
CM_ SG_ 831 PF_CMRObj15Dist "Forward Look Camera Light Object distance";
CM_ SG_ 832 PF_CMRObj16HorSpeed "Forward Look Camera Light Object horizontal speed";
CM_ SG_ 832 PF_CMRObj16VerPos "Forward Look Camera Light Object vertical position";
CM_ SG_ 832 PF_CMRObj16ID "Forward Look Camera Light Object ID";
CM_ SG_ 832 PF_CMRObj16HorPosRight "Forward Look Camera Light Object horizontal position right";
CM_ SG_ 832 PF_CMRObj16HorPosLeft "Forward Look Camera Light Object horizontal position left";
CM_ SG_ 832 PF_CMRObj16Dist "Forward Look Camera Light Object distance";
CM_ SG_ 791 TSRAddSign1 "For values see: rsf::E _TSR_ADD_SIGN.";
CM_ SG_ 791 TSRMainSign1 "0: No Display (Unknown)
1: Cancelled
2: 5
3: 10
…
30: 145
31: 150
32: OP Cancelled
33: Otk Prohibited
34: Otk Prohibited Restriction
35-63: Reserved
64-127: Warning signs (see: rsf::E_TSI_WARNING_SIGNS)
128-255: Reserved";
CM_ SG_ 30 TimeSync_Type "  Multiplexer: 0x20 = SYNC with CRC, 0x28 = FUP with CRC, 0x10 = SYNC, 0x18 = FUP";
CM_ SG_ 30 TimeSync_CRC "CRC calculation: AUTOSAR_SWS_CRCLibrary.pdf, function Crc_CalculateCRC8H2F()";
CM_ SG_ 30 TimeSync_SequenceCounter "SC = Sequence Counter";
CM_ SG_ 30 TimeSync_TimeDomain "Time Domain 0 to 15";
CM_ SG_ 30 TimeSync_UserByte0 "UserByte0";
CM_ SG_ 30 TimeSync_SyncTimeSec "SyncTime: seconds";
CM_ SG_ 30 TimeSync_OverflowOfSeconds "OVS = Overflow of seconds, must be added to SyncTimeSec";
CM_ SG_ 30 TimeSync_SGW "SyncToGTM = 0
SyncToSubDomain = 1";
CM_ SG_ 30 TimeSync_Reserved0 "FUP Byte3: Bit7 to Bit3 reserved area";
CM_ SG_ 30 TimeSync_SyncTimeNSec "SyncTime: nanoseconds";
CM_ SG_ 792 TSRNextSpdLimit "0: No Display (Unknown)
1: Cancelled
2: 5
3: 10
…
30: 145
31: 150";
CM_ SG_ 305 ADAS_Meta_ProtVer_MinorSub "Contains Sub-Minor protocol version";
CM_ SG_ 305 ADAS_Meta_CycCnt "Cyclic counter of this message type: reconstructor can use this value to detect missing messages";
CM_ SG_ 305 ADAS_Meta_MsgType "Used for multiplexed ADASIS messages or for verification purposes. See value descriptions for details";
CM_ SG_ 305 ADAS_Meta_MapVerQtr "Content of this field is Year quarter of release of map of current area.
For example, Q4/2007 map will be
MAP VERSION (Y) = 7
MAP VERSION (Q) = 3
Value of this field could vary between messages if map uses data with different release dates";
CM_ SG_ 305 ADAS_Meta_MapVerYear "Content of this field is Year of release of map of current area. For 2007, this field will contain value 7.
Value of this field could vary between messages if map uses data with different release dates";
CM_ SG_ 305 ADAS_Meta_MapProvider "Map Provider of current area (map tile, region, country, etc)";
CM_ SG_ 305 ADAS_Meta_HwVer "This field is ADAS Horizon Provider specific.";
CM_ SG_ 305 ADAS_Meta_ProtVer_Minor "Contains Minor protocol version;
For instance, for protocol version 0.15 Major Protocol Version will be 0 and Minor Protocol Version 15.";
CM_ SG_ 305 ADAS_Meta_ProtVer_Major "Contains Minor protocol version;
For instance, for protocol version 0.15 Major Protocol Version will be 0 and Minor Protocol Version 15.";
CM_ SG_ 305 ADAS_Meta_SpdUnits "Specifies whether miles or kilometers are used as units (speed limits, etc.)";
CM_ SG_ 305 ADAS_Meta_DrvSide "Specifies the driving side of the road";
CM_ SG_ 305 ADAS_Meta_RegionCode "For a given Country Code, specifies region of a country.
0 stands for unknown, all other values are system specific.";
CM_ SG_ 305 ADAS_Meta_CountryCode "ISO 3166-1 country code";
CM_ SG_ 311 ADAS_ProfShort_ProfType "Type of the Profile. See value descriptions for details";
CM_ SG_ 311 ADAS_ProfShort_Retr "If true, this message was sent already at least once before";
CM_ SG_ 311 ADAS_ProfShort_PathIdx "Index of current path: If this number differs from one specified in previous PROFILE message, vehicle left the original path
Indices 0-7 have special meaning: see value descriptions for details";
CM_ SG_ 311 ADAS_ProfShort_Offset "Offset of position of the first profile spot from start position modulo 8191. Offset 8191 is invalid.";
CM_ SG_ 311 ADAS_ProfShort_MsgType "Used for multiplexed ADASIS messages or for verification purposes. See value descriptions for details";
CM_ SG_ 311 ADAS_ProfShort_CycCnt "Cyclic counter of this message type: reconstructor can use this value to detect missing messages";
CM_ SG_ 311 ADAS_ProfShort_Value1 "Profile value at Offset+Distance1, if Distance1 > 0";
CM_ SG_ 311 ADAS_ProfShort_Dist1 "Distance from first profile spot to the second one.
If 0, no other profile values are defined in this message.";
CM_ SG_ 311 ADAS_ProfShort_Value0 "Profile value at Offset";
CM_ SG_ 311 ADAS_ProfShort_CtrlPoint "If true, values in this message specifies additional control points required for certain interpolation types;
if false, actual profile values are specified";
CM_ SG_ 279 OverSpdWarningOffset "Driver adjustable overspeed warning threshold offset. Unit is the same as the display unit.";
CM_ SG_ 817 PF_CMRObj01Dist "Forward Look Camera Light Object distance";
CM_ SG_ 817 PF_CMRObj01HorPosLeft "Forward Look Camera Light Object horizontal position left";
CM_ SG_ 817 PF_CMRObj01HorPosRight "Forward Look Camera Light Object horizontal position right";
CM_ SG_ 817 PF_CMRObj01HorSpeed "Forward Look Camera Light Object horizontal speed";
CM_ SG_ 817 PF_CMRObj01ID "Forward Look Camera Light Object ID";
CM_ SG_ 817 PF_CMRObj01VerPos "Forward Look Camera Light Object vertical position";
CM_ SG_ 818 PF_CMRObj02Dist "Forward Look Camera Light Object distance";
CM_ SG_ 818 PF_CMRObj02HorPosLeft "Forward Look Camera Light Object horizontal position left";
CM_ SG_ 818 PF_CMRObj02HorPosRight "Forward Look Camera Light Object horizontal position right";
CM_ SG_ 818 PF_CMRObj02HorSpeed "Forward Look Camera Light Object horizontal speed";
CM_ SG_ 818 PF_CMRObj02ID "Forward Look Camera Light Object ID";
CM_ SG_ 818 PF_CMRObj02VerPos "Forward Look Camera Light Object vertical position";
CM_ SG_ 819 PF_CMRObj03Dist "Forward Look Camera Light Object distance";
CM_ SG_ 819 PF_CMRObj03HorPosLeft "Forward Look Camera Light Object horizontal position left";
CM_ SG_ 819 PF_CMRObj03HorPosRight "Forward Look Camera Light Object horizontal position right";
CM_ SG_ 819 PF_CMRObj03HorSpeed "Forward Look Camera Light Object horizontal speed";
CM_ SG_ 819 PF_CMRObj03ID "Forward Look Camera Light Object ID";
CM_ SG_ 819 PF_CMRObj03VerPos "Forward Look Camera Light Object vertical position";
CM_ SG_ 820 PF_CMRObj04Dist "Forward Look Camera Light Object distance";
CM_ SG_ 820 PF_CMRObj04HorPosLeft "Forward Look Camera Light Object horizontal position left";
CM_ SG_ 820 PF_CMRObj04HorPosRight "Forward Look Camera Light Object horizontal position right";
CM_ SG_ 820 PF_CMRObj04HorSpeed "Forward Look Camera Light Object horizontal speed";
CM_ SG_ 820 PF_CMRObj04ID "Forward Look Camera Light Object ID";
CM_ SG_ 820 PF_CMRObj04VerPos "Forward Look Camera Light Object vertical position";
CM_ SG_ 821 PF_CMRObj05HorSpeed "Forward Look Camera Light Object horizontal speed";
CM_ SG_ 821 PF_CMRObj05VerPos "Forward Look Camera Light Object vertical position";
CM_ SG_ 821 PF_CMRObj05ID "Forward Look Camera Light Object ID";
CM_ SG_ 821 PF_CMRObj05HorPosRight "Forward Look Camera Light Object horizontal position right";
CM_ SG_ 821 PF_CMRObj05HorPosLeft "Forward Look Camera Light Object horizontal position left";
CM_ SG_ 821 PF_CMRObj05Dist "Forward Look Camera Light Object distance";
CM_ SG_ 823 PF_CMRObj07HorSpeed "Forward Look Camera Light Object horizontal speed";
CM_ SG_ 823 PF_CMRObj07VerPos "Forward Look Camera Light Object vertical position";
CM_ SG_ 823 PF_CMRObj07ID "Forward Look Camera Light Object ID";
CM_ SG_ 823 PF_CMRObj07HorPosRight "Forward Look Camera Light Object horizontal position right";
CM_ SG_ 823 PF_CMRObj07HorPosLeft "Forward Look Camera Light Object horizontal position left";
CM_ SG_ 823 PF_CMRObj07Dist "Forward Look Camera Light Object distance";
CM_ SG_ 824 PF_CMRObj08HorSpeed "Forward Look Camera Light Object horizontal speed";
CM_ SG_ 824 PF_CMRObj08VerPos "Forward Look Camera Light Object vertical position";
CM_ SG_ 824 PF_CMRObj08ID "Forward Look Camera Light Object ID";
CM_ SG_ 824 PF_CMRObj08HorPosRight "Forward Look Camera Light Object horizontal position right";
CM_ SG_ 824 PF_CMRObj08HorPosLeft "Forward Look Camera Light Object horizontal position left";
CM_ SG_ 824 PF_CMRObj08Dist "Forward Look Camera Light Object distance";
CM_ SG_ 825 PF_CMRObj09HorSpeed "Forward Look Camera Light Object horizontal speed";
CM_ SG_ 825 PF_CMRObj09VerPos "Forward Look Camera Light Object vertical position";
CM_ SG_ 825 PF_CMRObj09ID "Forward Look Camera Light Object ID";
CM_ SG_ 825 PF_CMRObj09HorPosRight "Forward Look Camera Light Object horizontal position right";
CM_ SG_ 825 PF_CMRObj09HorPosLeft "Forward Look Camera Light Object horizontal position left";
CM_ SG_ 825 PF_CMRObj09Dist "Forward Look Camera Light Object distance";
CM_ SG_ 822 PF_CMRObj06HorSpeed "Forward Look Camera Light Object horizontal speed";
CM_ SG_ 822 PF_CMRObj06VerPos "Forward Look Camera Light Object vertical position";
CM_ SG_ 822 PF_CMRObj06ID "Forward Look Camera Light Object ID";
CM_ SG_ 822 PF_CMRObj06HorPosRight "Forward Look Camera Light Object horizontal position right";
CM_ SG_ 822 PF_CMRObj06HorPosLeft "Forward Look Camera Light Object horizontal position left";
CM_ SG_ 822 PF_CMRObj06Dist "Forward Look Camera Light Object distance";
BA_DEF_ BU_  "ILUsed" ENUM  "No","Yes";
BA_DEF_  "NmBaseAddress" HEX 1024 1087;
BA_DEF_  "BusType" STRING ;
BA_DEF_ BO_  "GenMsgCycleTime" INT 0 65535;
BA_DEF_ BO_  "GenMsgILSupport" ENUM  "No","Yes";
BA_DEF_ BO_  "GenMsgSendType" ENUM  "Cyclic","Event","reserved","reserved","reserved","reserved","reserved","IfActive","NoMsgSendType","reserved","reserved","reserved";
BA_DEF_ SG_  "GenSigSendType" ENUM  "Cyclic","OnWrite","OnWriteWithRepetition","OnChange","OnChangeWithRepetition","IfActive","IfActiveWithRepetition","NoSigSendType","OnChangeAndIfActive","OnChangeAndIfActiveWithRepetition";
BA_DEF_ SG_  "GenSigStartValue" HEX 0 2147483648;
BA_DEF_  "DBName" STRING ;
BA_DEF_DEF_  "ILUsed" "Yes";
BA_DEF_DEF_  "NmBaseAddress" 1024;
BA_DEF_DEF_  "BusType" "CAN";
BA_DEF_DEF_  "GenMsgCycleTime" 0;
BA_DEF_DEF_  "GenMsgILSupport" "Yes";
BA_DEF_DEF_  "GenMsgSendType" "Cyclic";
BA_DEF_DEF_  "GenSigSendType" "NoSigSendType";
BA_DEF_DEF_  "GenSigStartValue" 0;
BA_DEF_DEF_  "DBName" "ChooseYourNameHere";
BA_ "DBName" "OD_FV_Public_CAN";
BA_ "GenMsgCycleTime" BO_ 627 40;
BA_ "GenMsgCycleTime" BO_ 626 40;
BA_ "GenMsgCycleTime" BO_ 992 5000;
BA_ "GenMsgCycleTime" BO_ 1983 5000;
BA_ "GenMsgCycleTime" BO_ 446 80;
BA_ "GenMsgCycleTime" BO_ 18 80;
BA_ "GenMsgCycleTime" BO_ 11 40;
BA_ "GenMsgCycleTime" BO_ 264 100;
BA_ "GenMsgCycleTime" BO_ 17 40;
BA_ "GenMsgCycleTime" BO_ 268 100;
BA_ "GenMsgCycleTime" BO_ 237 40;
BA_ "GenMsgCycleTime" BO_ 240 40;
BA_ "GenMsgCycleTime" BO_ 681 20;
BA_ "GenMsgCycleTime" BO_ 255 1000;
BA_ "GenMsgCycleTime" BO_ 230 10;
BA_ "GenMsgCycleTime" BO_ 270 10;
BA_ "GenMsgCycleTime" BO_ 43 20;
BA_ "GenMsgCycleTime" BO_ 88 20;
BA_ "GenMsgCycleTime" BO_ 266 60;
BA_ "GenMsgCycleTime" BO_ 253 40;
BA_ "GenMsgCycleTime" BO_ 254 40;
BA_ "GenMsgCycleTime" BO_ 416 100;
BA_ "GenMsgCycleTime" BO_ 277 100;
BA_ "GenMsgCycleTime" BO_ 104 40;
BA_ "GenMsgCycleTime" BO_ 106 40;
BA_ "GenMsgCycleTime" BO_ 301 60;
BA_ "GenMsgCycleTime" BO_ 439 20;
BA_ "GenMsgCycleTime" BO_ 186 20;
BA_ "GenMsgCycleTime" BO_ 318 20;
BA_ "GenMsgSendType" BO_ 515 8;
BA_ "GenMsgCycleTime" BO_ 132 10;
BA_ "GenMsgCycleTime" BO_ 54 10;
BA_ "GenMsgCycleTime" BO_ 13 10;
BA_ "GenMsgCycleTime" BO_ 46 10;
BA_ "GenMsgCycleTime" BO_ 50 10;
BA_ "GenMsgCycleTime" BO_ 191 20;
BA_ "GenMsgCycleTime" BO_ 74 10;
BA_ "GenMsgCycleTime" BO_ 76 10;
BA_ "GenMsgCycleTime" BO_ 86 10;
BA_ "GenMsgCycleTime" BO_ 397 80;
BA_ "GenMsgCycleTime" BO_ 399 150;
BA_ "GenMsgCycleTime" BO_ 655 250;
BA_ "GenMsgCycleTime" BO_ 245 40;
BA_ "GenMsgCycleTime" BO_ 836 320;
BA_ "GenMsgCycleTime" BO_ 80 10;
BA_ "GenMsgCycleTime" BO_ 1024 125;
BA_ "GenMsgSendType" BO_ 1025 8;
BA_ "GenMsgCycleTime" BO_ 321 10;
BA_ "GenMsgCycleTime" BO_ 340 20;
BA_ "GenMsgCycleTime" BO_ 3 20;
BA_ "GenMsgSendType" BO_ 2 8;
BA_ "GenMsgCycleTime" BO_ 793 10;
BA_ "GenMsgCycleTime" BO_ 323 10;
BA_ "GenMsgCycleTime" BO_ 289 20;
BA_ "GenMsgCycleTime" BO_ 327 200;
BA_ "GenMsgCycleTime" BO_ 1809 60;
BA_ "GenMsgCycleTime" BO_ 328 40;
BA_ "GenMsgCycleTime" BO_ 787 10;
BA_ "GenMsgCycleTime" BO_ 1810 60;
BA_ "GenMsgCycleTime" BO_ 293 20;
BA_ "GenMsgCycleTime" BO_ 788 20;
BA_ "GenMsgCycleTime" BO_ 835 20;
BA_ "GenMsgCycleTime" BO_ 800 20;
BA_ "GenMsgCycleTime" BO_ 257 10;
BA_ "GenMsgCycleTime" BO_ 1282 20;
BA_ "GenMsgCycleTime" BO_ 297 10;
BA_ "GenMsgCycleTime" BO_ 804 60;
BA_ "GenMsgCycleTime" BO_ 826 60;
BA_ "GenMsgCycleTime" BO_ 827 60;
BA_ "GenMsgCycleTime" BO_ 828 60;
BA_ "GenMsgCycleTime" BO_ 829 60;
BA_ "GenMsgCycleTime" BO_ 265 20;
BA_ "GenMsgCycleTime" BO_ 830 60;
BA_ "GenMsgCycleTime" BO_ 870 10;
BA_ "GenMsgCycleTime" BO_ 831 60;
BA_ "GenMsgCycleTime" BO_ 832 60;
BA_ "GenMsgCycleTime" BO_ 1792 60;
BA_ "GenMsgCycleTime" BO_ 1793 60;
BA_ "GenMsgCycleTime" BO_ 834 20;
BA_ "GenMsgCycleTime" BO_ 864 10;
BA_ "GenMsgCycleTime" BO_ 329 10;
BA_ "GenMsgCycleTime" BO_ 336 10;
BA_ "GenMsgCycleTime" BO_ 865 50;
BA_ "GenMsgCycleTime" BO_ 1808 60;
BA_ "GenMsgCycleTime" BO_ 791 60;
BA_ "GenMsgCycleTime" BO_ 30 500;
BA_ "GenMsgSendType" BO_ 1882 8;
BA_ "GenMsgCycleTime" BO_ 792 60;
BA_ "GenMsgCycleTime" BO_ 305 5000;
BA_ "GenMsgCycleTime" BO_ 513 160;
BA_ "GenMsgCycleTime" BO_ 786 20;
BA_ "GenMsgCycleTime" BO_ 311 10;
BA_ "GenMsgSendType" BO_ 1874 8;
BA_ "GenMsgCycleTime" BO_ 785 20;
BA_ "GenMsgCycleTime" BO_ 769 20;
BA_ "GenMsgCycleTime" BO_ 866 60;
BA_ "GenMsgCycleTime" BO_ 789 40;
BA_ "GenMsgCycleTime" BO_ 278 20;
BA_ "GenMsgCycleTime" BO_ 1280 20;
BA_ "GenMsgCycleTime" BO_ 790 10;
BA_ "GenMsgCycleTime" BO_ 279 20;
BA_ "GenMsgCycleTime" BO_ 833 100;
BA_ "GenMsgCycleTime" BO_ 817 60;
BA_ "GenMsgCycleTime" BO_ 818 60;
BA_ "GenMsgCycleTime" BO_ 819 60;
BA_ "GenMsgCycleTime" BO_ 820 60;
BA_ "GenMsgCycleTime" BO_ 821 60;
BA_ "GenMsgCycleTime" BO_ 823 60;
BA_ "GenMsgCycleTime" BO_ 824 60;
BA_ "GenMsgCycleTime" BO_ 825 60;
BA_ "GenMsgCycleTime" BO_ 822 60;
BA_ "GenMsgSendType" BO_ 2015 8;
BA_ "GenSigStartValue" SG_ 1983 DBC_VersionIdMinor 3;
BA_ "GenSigStartValue" SG_ 1983 DBC_VersionIdMajor 3;
BA_ "GenSigStartValue" SG_ 18 TCSSwitchSports 2;
BA_ "GenSigStartValue" SG_ 11 YawRate 500;
BA_ "GenSigStartValue" SG_ 264 GSAPosStatus 15;
BA_ "GenSigStartValue" SG_ 17 ABSPwrTrnTorqReq 1;
BA_ "GenSigStartValue" SG_ 17 BrakePressureQF 1;
BA_ "GenSigStartValue" SG_ 17 VehicleSpeedQF 1;
BA_ "GenSigStartValue" SG_ 268 HillDescentMode 1;
BA_ "GenSigStartValue" SG_ 268 VehMovementDirection 2;
BA_ "GenSigStartValue" SG_ 268 VehMovementStatus 1;
BA_ "GenSigStartValue" SG_ 237 WheelSpeedFrLQF 1;
BA_ "GenSigStartValue" SG_ 237 WheelSpeedFrRQF 1;
BA_ "GenSigStartValue" SG_ 240 WheelSpeedReLQF 1;
BA_ "GenSigStartValue" SG_ 240 WheelSpeedReRQF 1;
BA_ "GenSigStartValue" SG_ 255 DirectionIndicationSwitch 6;
BA_ "GenSigStartValue" SG_ 88 TSRHandOfTraffic 2;
BA_ "GenSigStartValue" SG_ 266 DADCFuncStatus 7;
BA_ "GenSigStartValue" SG_ 277 TerrainModeReqExt 7;
BA_ "GenSigStartValue" SG_ 104 HighBeamStatus 15;
BA_ "GenSigStartValue" SG_ 104 LowBeamStatus 15;
BA_ "GenSigStartValue" SG_ 106 ADBHorEdgeLT 65535;
BA_ "GenSigStartValue" SG_ 106 ADBHorEdgeRT 65535;
BA_ "GenSigStartValue" SG_ 106 LaserStatus 15;
BA_ "GenSigStartValue" SG_ 106 LBStatus 15;
BA_ "GenSigStartValue" SG_ 106 LightDist 15;
BA_ "GenSigStartValue" SG_ 301 AFSLightDist_b 15;
BA_ "GenSigStartValue" SG_ 301 AFSPHBAngleLT_b 65535;
BA_ "GenSigStartValue" SG_ 301 AFSPHBAngleRT_b 65535;
BA_ "GenSigStartValue" SG_ 301 AFSStatus_b 15;
BA_ "GenSigStartValue" SG_ 301 LaserStatus_b 15;
BA_ "GenSigStartValue" SG_ 132 EngineSpeedQF 1;
BA_ "GenSigStartValue" SG_ 54 PedalPosProQF 1;
BA_ "GenSigStartValue" SG_ 13 WheelTorqTgtWoIntF 1000;
BA_ "GenSigStartValue" SG_ 13 WheelTorqTgtWoIntR 1000;
BA_ "GenSigStartValue" SG_ 74 A1 32768;
BA_ "GenSigStartValue" SG_ 74 A1_STAT 4;
BA_ "GenSigStartValue" SG_ 74 PSIP1 32768;
BA_ "GenSigStartValue" SG_ 74 PSIP1_STAT 4;
BA_ "GenSigStartValue" SG_ 76 A2 32768;
BA_ "GenSigStartValue" SG_ 76 A2_STAT 4;
BA_ "GenSigStartValue" SG_ 76 PSIPP1 32768;
BA_ "GenSigStartValue" SG_ 76 PSIPP1_STAT 4;
BA_ "GenSigStartValue" SG_ 86 SteeringWheelAngle 7800;
BA_ "GenSigStartValue" SG_ 86 SteeringWheelAngleStatus 1;
BA_ "GenSigStartValue" SG_ 397 THETAP 32768;
BA_ "GenSigStartValue" SG_ 655 DoorStatus 63;
BA_ "GenSigStartValue" SG_ 655 FrontFogLightIndication 3;
BA_ "GenSigStartValue" SG_ 245 ATPCProStatus 3;
BA_ "GenSigStartValue" SG_ 80 TCMPositionDisplay 49152;
BA_ "GenSigStartValue" SG_ 800 TargetSteeringAngle 32768;
VAL_ 627 status_rate_z 0 "Init" 1 "Sporadic_Error" 2 "Permanent_Error" 3 "Valid" ;
VAL_ 627 status_rate_y 0 "Init" 1 "Sporadic_Error" 2 "Permanent_Error" 3 "Valid" ;
VAL_ 627 status_rate_x 0 "Init" 1 "Sporadic_Error" 2 "Permanent_Error" 3 "Valid" ;
VAL_ 626 status_acc_z 0 "Init" 1 "Sporadic_Error" 2 "Permanent_Error" 3 "Valid" ;
VAL_ 626 status_acc_y 0 "Init" 1 "Sporadic_Error" 2 "Permanent_Error" 3 "Valid" ;
VAL_ 626 status_acc_x 0 "Init" 1 "Sporadic_Error" 2 "Permanent_Error" 3 "Valid" ;
VAL_ 446 CameraStatus 0 "Camera Operational" 1 "Camera Initialization" 2 "Camera Limited" 3 "Dirty" 4 "Camera Blocked" 5 "Camera Error" 6 "Camera Calibration" 7 "Camera Decalibration" ;
VAL_ 18 ABSMode 0 "No ABS activity" 1 "ABS activity present" ;
VAL_ 18 DSCActivityStatus 0 "No DSC activity" 1 "DSC activity present" ;
VAL_ 18 TCSSwitchSports 0 "DSC/TCS off (DSC OFF)" 1 "DSC/TCS mode 1 (TRAC DSC)" 2 "DSC/TCS on (DSC ON)" 3 "DSC/TCS on (no text message)" ;
VAL_ 18 TractionControlActive 0 "Traction Control INACTIVE" 1 "Traction Control ACTIVE" ;
VAL_ 18 TractionControlFault 0 "Traction Control OK" 1 "Traction Control Fault" ;
VAL_ 18 YawControlFault 0 "Yaw Control OK" 1 "Yaw Control Fault" ;
VAL_ 11 ABSFault 0 "ABS OK" 1 "ABS Fault" ;
VAL_ 11 YawRate 1023 "Error Marker" ;
VAL_ 264 GSAPosStatus 0 "Park" 1 "Reverse" 2 "Neutral" 3 "Drive" 4 "RESERVED4" 5 "RESERVED5" 6 "RESERVED6" 7 "Sport" 8 "RESERVED8" 9 "RESERVED9" 10 "RESERVED10" 11 "RESERVED11" 12 "RESERVED12" 13 "RESERVED13" 14 "Fault" 15 "Unconfirmed" ;
VAL_ 17 ABSEngVacReq 0 "no vacuum assistance required" 1 "vacuum assistance required" ;
VAL_ 17 ABSPwrTrnTorqReq 0 "powertrain torque is not required" 1 "powertrain torque is required" ;
VAL_ 17 BrakePressureQF 0 "The accuracy of the data is undefinable" 1 "Data is temporarily undefinable, evaluation in progress" 2 "The accuracy of the data is not within specification" 3 "The data is calculated with the specified accuracy" ;
VAL_ 17 VehicleSpeedQF 0 "The accuracy of the data is undefinable" 1 "Data is temporarily undefinable, evaluation in progress" 2 "The accuracy of the data is not within specification" 3 "The data is calculated with the specified accuracy" ;
VAL_ 268 HillDescentMode 0 "Undefined" 1 "Off" 2 "Selected; not active braking" 3 "Selected; active braking" 4 "Selected; not enabled - speed limit exceeded" 5 "Selected; not enabled - wrong gear selected" 6 "Selected; temporary unavailable" 7 "HDC Fault" ;
VAL_ 268 VehMovementDirection 0 "Vehicle moving forwards" 1 "Vehicle moving backwards" 2 "Undetermined direction" 3 "Reserved" ;
VAL_ 268 VehMovementStatus 0 "Vehicle stationary" 1 "Vehicle moving" ;
VAL_ 268 WheelDirectionFL 0 "Forwards" 1 "Backwards" 2 "Undetermined Direction" 3 "Stationary" ;
VAL_ 268 WheelDirectionFR 0 "Forwards" 1 "Backwards" 2 "Undetermined Direction" 3 "Stationary" ;
VAL_ 268 WheelDirectionRL 0 "Forwards" 1 "Backwards" 2 "Undetermined Direction" 3 "Stationary" ;
VAL_ 268 WheelDirectionRR 0 "Forwards" 1 "Backwards" 2 "Undetermined Direction" 3 "Stationary" ;
VAL_ 237 WheelSpeedFrLQF 0 "The accuracy of the data is undefinable" 1 "Data is temporarily undefinable, evaluation in progress" 2 "The accuracy of the data is not within specification" 3 "The data is calculated with the specified accuracy" ;
VAL_ 237 WheelSpeedFrRQF 0 "The accuracy of the data is undefinable" 1 "Data is temporarily undefinable, evaluation in progress" 2 "The accuracy of the data is not within specification" 3 "The data is calculated with the specified accuracy" ;
VAL_ 240 WheelSpeedReLQF 0 "The accuracy of the data is undefinable" 1 "Data is temporarily undefinable, evaluation in progress" 2 "The accuracy of the data is not within specification" 3 "The data is calculated with the specified accuracy" ;
VAL_ 240 WheelSpeedReRQF 0 "The accuracy of the data is undefinable" 1 "Data is temporarily undefinable, evaluation in progress" 2 "The accuracy of the data is not within specification" 3 "The data is calculated with the specified accuracy" ;
VAL_ 255 CarMode 0 "Normal" 1 "Factory" 2 "Unused2" 3 "Transport" 4 "Unused4" 5 "Crash" ;
VAL_ 255 DirectionIndicationSwitch 0 "Neutral" 1 "Right" 2 "Left" 3 "Open Circuit Fault" 4 "Short Circuit Fault" 5 "Missing Signal Fault" 6 "Initialisation Default State" 7 "Undefined (Unused)" ;
VAL_ 255 MainBeamIndication 0 "Main beam lamps OFF" 1 "Main beam lamps ON" ;
VAL_ 255 PowerMode 0 "KeyOut" 1 "KeyRecentlyOut" 2 "KeyApproved_0" 3 "PostAccessory_0" 4 "Accessory_1" 5 "PostIgnition_1" 6 "IgnitionOn_2" 7 "Running_2" 9 "Crank_3" ;
VAL_ 255 RunningStandby 0 "Engine is NOT in Eco Stop" 1 "Engine is in Eco Stop" ;
VAL_ 230 DirectionIndication 0 "Neutral: The indication is not in use." 1 "Left: Left indication is illuminated on the display" 2 "Right: Right indication is illuminated on the display" 3 "Hazard: Left and Right indication are illuminated on the display" ;
VAL_ 230 LDWSwitchReq 0 "Not Pressed" 1 "Pressed" ;
VAL_ 230 LowBeamIndication 0 "Low beam lamps OFF" 1 "Low beam lamps ON" ;
VAL_ 270 SuspensionHeightFL 511 "Error Marker" ;
VAL_ 270 SuspensionHeightFR 511 "Error Marker" ;
VAL_ 270 SuspensionHeightRL 511 "Error Marker" ;
VAL_ 270 SuspensionHeightRR 511 "Error Marker" ;
VAL_ 43 AIR_ControlStatus 0 "Not moving" 1 "Lifting" 2 "Dropping" ;
VAL_ 43 AIR_SuspensionMode 0 "Reserved" 1 "Access" 2 "Motorway" 3 "Standard" 4 "Off Road" 5 "Intermediate Off Road" 6 "Extended Mode" 7 "Sand Recovery Mode" ;
VAL_ 88 TSRCountry 0 "Unknown" 1 "Andorra" 2 "Austria" 3 "Belgium" 4 "Belarus" 5 "Bosnia-Herzegovina" 6 "Bulgaria" 7 "Canada" 8 "Czech Republic" 9 "Denmark" 10 "Estonia" 11 "Finland" 12 "France" 13 "Germany" 14 "Greece" 15 "Hungary" 16 "Ireland" 17 "Italy" 18 "Israel" 19 "Latvia" 20 "Liechtenstein" 21 "Lithuania" 22 "Luxembourg" 23 "Netherlands" 24 "Monaco" 25 "Norway" 26 "Poland" 27 "Portugal" 28 "Romania" 29 "Russia" 30 "San Marino" 31 "Slovakia" 32 "Slovenia" 33 "Spain" 34 "Sweden" 35 "Switzerland" 36 "Turkey" 37 "United Kingdom" 38 "USA" 39 "Ukraine" 40 "Vatican City" 41 "Croatia" 42 "Iceland" 43 "Malta" 44 "Malaysia" 45 "Singapore" 46 "Taiwan" 47 "Thailand" 48 "Japan" 49 "China" 50 "South Korea" 51 "Australia" 52 "Albania" 53 "Argentina" 54 "Brazil" 55 "Chile" 56 "Colombia" 57 "Cyprus" 58 "United Arab Emirates" 59 "Hong Kong" 60 "Kosovo" 61 "Macao" 62 "Macedonia" 63 "Moldova" 64 "Montenegro" 65 "New Zealand" 66 "Serbia" 67 "South Africa" 68 "Gibraltar" 69 "RESERVED58" 70 "RESERVED57" 71 "RESERVED56" 72 "RESERVED55" 73 "RESERVED54" 74 "RESERVED53" 75 "RESERVED52" 76 "RESERVED51" 77 "RESERVED50" 78 "RESERVED49" 79 "RESERVED48" 80 "RESERVED47" 81 "RESERVED46" 82 "RESERVED45" 83 "RESERVED44" 84 "RESERVED43" 85 "RESERVED42" 86 "RESERVED41" 87 "RESERVED40" 88 "RESERVED39" 89 "RESERVED38" 90 "RESERVED37" 91 "RESERVED36" 92 "RESERVED35" 93 "RESERVED34" 94 "RESERVED33" 95 "RESERVED32" 96 "RESERVED31" 97 "RESERVED30" 98 "RESERVED29" 99 "RESERVED28" 100 "RESERVED27" 101 "RESERVED26" 102 "RESERVED25" 103 "RESERVED24" 104 "RESERVED23" 105 "RESERVED22" 106 "RESERVED21" 107 "RESERVED20" 108 "RESERVED19" 109 "RESERVED18" 110 "RESERVED17" 111 "RESERVED16" 112 "RESERVED15" 113 "RESERVED14" 114 "RESERVED13" 115 "RESERVED12" 116 "RESERVED11" 117 "RESERVED10" 118 "RESERVED9" 119 "RESERVED8" 120 "RESERVED7" 121 "RESERVED6" 122 "RESERVED5" 123 "RESERVED4" 124 "RESERVED3" 125 "RESERVED2" 126 "RESERVED1" 127 "Country Not Supported" ;
VAL_ 88 TSRHandOfTraffic 0 "LH Traffic" 1 "RH Traffic" 2 "Unknown" 3 "Not used" ;
VAL_ 266 DADCFuncStatus 0 "Off" 1 "DADC Funct State 1" 2 "DADC Funct State 2" 3 "RESERVED4" 4 "RESERVED3" 5 "RESERVED2" 6 "RESERVED1" 7 "DADC Funct State ON" ;
VAL_ 253 RWSFaultAngle 0 "OK" 1 "RWS Failure non-zero" ;
VAL_ 253 RWSFaultStraight 0 "OK" 1 "RWS Failure at zero" ;
VAL_ 253 RWSMotTypeServeLat 0 "Lateral Off" 1 "Lateral Comfort" 2 "Lateral Offroad" 3 "Lateral Emergency" 4 "Unused/Reserved4" 5 "Unused/Reserved5" 6 "Unused/Reserved6" 7 "Unused/Reserved7" ;
VAL_ 253 RWSMotTypeServeLong 0 "Longitudinal Off" 1 "Longitudinal Comfort" 2 "Longitudinal Offroad" 3 "Longitudinal Emergency" 4 "Unused/Reserved4" 5 "Unused/Reserved5" 6 "Unused/Reserved6" 7 "Unused/Reserved7" ;
VAL_ 253 RWSMotTypeServeLvl 0 "No level" 1 "Level 12 driver backup" 2 "Level 23 system backup" 3 "Level 3 system backup" 4 "Level 4 system backup" 5 "Level 5 system backup" 6 "Level 3 force secondary brake" 7 "Error" ;
VAL_ 253 RWSMotTypeServeMode 0 "None" 1 "DVG Req" 2 "LSM Req" 3 "BSS Req" ;
VAL_ 254 DrvLimRWSAct 0 "RWS NOT limited" 1 "RWS Limited" 2 "Reserved1" 3 "Reserved2" ;
VAL_ 254 RWSSysStats 0 "Non Active" 1 "Active, no external requests accepted" 2 "Active, accepting external requests" 3 "Transition" 4 "Active, under external control" 5 "Inhibited" 6 "Failure" 7 "Failure (non zero angle)" ;
VAL_ 254 RWSTerrainModeExt 0 "Standard Mode" 1 "TR: Grass/Gravel/Snow / JDC: Winter Mode" 2 "Undefined2" 3 "TR: Sand" 4 "TR: Mud" 5 "TR: Rock Crawl" 6 "Dynamic Mode" 7 "Fail Safe Default" 8 "JDC: Comfort Mode" 9 "JDC/TR: Economy Mode" 10 "MEDIUM_FRICTION" 11 "ECO Plus" 12 "WADE" 13 "CONFIGURABLE" 14 "Undefined14" 15 "Undefined15" ;
VAL_ 254 RWSTerrChngModeStatus 0 "Mode change available" 1 "ECU in initialisation" 2 "Dynamic conditions" 3 "Allow mode change but can inhibit internally (what EPAS currently does)" 4 "t.b.d.4" 5 "t.b.d.5" 6 "Fault condition" 7 "Not to be used" ;
VAL_ 254 RWSTRConfig 0 "CTR Not Active" 1 "Config A Active" 2 "Config B Active" 3 "Config C Active" ;
VAL_ 416 CustomerSymptomIPMA 0 "No Symptom Present" 1 "Symptom Present" ;
VAL_ 277 TerrainModeReqExt 0 "Comfort" 1 "Winter_Grass_Gravel_Snow" 2 "RESERVED2" 3 "Sand" 4 "Mud_Ruts" 5 "Rock_Crawl" 6 "Dynamic" 7 "Failsafe_Default" 8 "DynamicLite_SVO" 9 "ECO" 10 "Medium_Mu" 11 "ULPM" 12 "Wade" 13 "RESERVED13" 14 "RESERVED14" 15 "RESERVED15" ;
VAL_ 104 HBSeg0LT 0 "off" 1 "1...50%" 2 "51...75%" 3 "76...100%" ;
VAL_ 104 HBSeg0RT 0 "off" 1 "1...50%" 2 "51...75%" 3 "76...100%" ;
VAL_ 104 HBSeg1LT 0 "off" 1 "1...50%" 2 "51...75%" 3 "76...100%" ;
VAL_ 104 HBSeg1RT 0 "off" 1 "1...50%" 2 "51...75%" 3 "76...100%" ;
VAL_ 104 HBSeg2LT 0 "off" 1 "1...50%" 2 "51...75%" 3 "76...100%" ;
VAL_ 104 HBSeg2RT 0 "off" 1 "1...50%" 2 "51...75%" 3 "76...100%" ;
VAL_ 104 HBSeg3LT 0 "off" 1 "1...50%" 2 "51...75%" 3 "76...100%" ;
VAL_ 104 HBSeg3RT 0 "off" 1 "1...50%" 2 "51...75%" 3 "76...100%" ;
VAL_ 104 HBSeg4LT 0 "off" 1 "1...50%" 2 "51...75%" 3 "76...100%" ;
VAL_ 104 HBSeg4RT 0 "off" 1 "1...50%" 2 "51...75%" 3 "76...100%" ;
VAL_ 104 HBSeg5LT 0 "off" 1 "1...50%" 2 "51...75%" 3 "76...100%" ;
VAL_ 104 HBSeg5RT 0 "off" 1 "1...50%" 2 "51...75%" 3 "76...100%" ;
VAL_ 104 HBSeg6LT 0 "off" 1 "1...50%" 2 "51...75%" 3 "76...100%" ;
VAL_ 104 HBSeg6RT 0 "off" 1 "1...50%" 2 "51...75%" 3 "76...100%" ;
VAL_ 104 HBSeg7LT 0 "off" 1 "1...50%" 2 "51...75%" 3 "76...100%" ;
VAL_ 104 HBSeg7RT 0 "off" 1 "1...50%" 2 "51...75%" 3 "76...100%" ;
VAL_ 104 HBSeg8LT 0 "off" 1 "1...50%" 2 "51...75%" 3 "76...100%" ;
VAL_ 104 HBSeg8RT 0 "off" 1 "1...50%" 2 "51...75%" 3 "76...100%" ;
VAL_ 104 HBSeg9LT 0 "off" 1 "1...50%" 2 "51...75%" 3 "76...100%" ;
VAL_ 104 HBSeg9RT 0 "off" 1 "1...50%" 2 "51...75%" 3 "76...100%" ;
VAL_ 104 HighBeamStatus 0 "off" 1 "on, level 1, normal" 2 "on, level 2, additional led spot" 3 "on, level 3, additional laser spot" 4 "unused4" 5 "unused5" 6 "unused6" 7 "unused7" 8 "unused8" 9 "unused9" 10 "high beam signal input failure" 11 "high beam hardware failure" 12 "unused12" 13 "unused13" 14 "init" 15 "not available" ;
VAL_ 104 LowBeamStatus 0 "off" 1 "on, level 1, normal" 2 "on, level 2" 3 "on, level 3" 4 "on, level 4" 5 "on, level 5" 6 "on, level 6" 7 "on, level 7" 8 "Unused8" 9 "Unused9" 10 "low beam signal input failure" 11 "low beam hardware failure" 12 "Unused12" 13 "Unused13" 14 "init" 15 "not available" ;
VAL_ 106 ADBHorEdgeLT 65533 "ADB not active" 65534 "init" 65535 "not available" ;
VAL_ 106 ADBHorEdgeRT 65533 "ADB not active" 65534 "init" 65535 "not available" ;
VAL_ 106 LaserStatus 0 "on" 1 "off" 2 "laser signal input failure" 3 "laser hardware failure" 15 "signal not valid" ;
VAL_ 106 LBStatus 0 "On" 1 "Off" 2 "afs signal input failure" 3 "afs hardware failure" 14 "init" 15 "not available" ;
VAL_ 106 LightDist 0 "town" 1 "country light" 2 "motorway light" 3 "high beam" 4 "partial high beam" 14 "init" 15 "not available" ;
VAL_ 301 AFSLightDist_b 0 "town" 1 "country light" 2 "motorway light" 3 "high beam" 4 "partial high beam both sides" 5 "partial high beam right only" 6 "partial high beam left only" 15 "signal not valid" ;
VAL_ 301 AFSPHBAngleLT_b 65534 "phb not active" 65535 "signal not valid" ;
VAL_ 301 AFSPHBAngleRT_b 65534 "phb not active" 65535 "signal not valid" ;
VAL_ 301 AFSStatus_b 0 "on" 1 "off" 2 "afs signal input failure" 3 "afs hardware failure" 15 "signal not valid" ;
VAL_ 439 DisttoNextJunct 0 "Unknown" 255 "Invalid" ;
VAL_ 439 HandOfTrafficReq 0 "Traffic drives on the LHS" 1 "Traffic drives on the RHS" ;
VAL_ 439 InBuiltArea 0 "Unknown" 1 "No" 2 "YES" 3 "Reserved" ;
VAL_ 439 NavCountryCode 0 "Unknown" 1 "Andorra" 2 "Austria" 3 "Belgium" 4 "Belarus" 5 "Bosnia-Herzegovina" 6 "Bulgaria" 7 "Canada" 8 "Czech Republic" 9 "Denmark" 10 "Estonia" 11 "Finland" 12 "France" 13 "Germany" 14 "Greece" 15 "Hungary" 16 "Ireland" 17 "Italy" 18 "Israel" 19 "Latvia" 20 "Liechtenstein" 21 "Lithuania" 22 "Luxemborg" 23 "The Netherlands" 24 "Monaco" 25 "Norway" 26 "Poland" 27 "Portugal" 28 "Romania" 29 "Russia" 30 "San Marino" 31 "Slovakia" 32 "Slovenia" 33 "Spain" 34 "Sweden" 35 "Switzerland" 36 "Turkey" 37 "United Kingdom" 38 "United States" 39 "Ukraine" 40 "Vatican City" 41 "Croatia (HR)" 42 "Iceland" 43 "Malta" 44 "Malaysia" 45 "Singapore" 46 "Taiwan" 47 "Thailand" 48 "Japan" 49 "China" 50 "South Korea" 51 "Australia" 63 "Country Not Supported" ;
VAL_ 439 NavCurrRoadType 0 "Unknown" 1 "Class 1" 2 "Class 2" 3 "Class 3" 4 "Class 4" 5 "Class 5" ;
VAL_ 439 NavCurrState 0 "Unknown" 1 "Alabama" 2 "Alaska" 3 "Arizona" 4 "Arkansas" 5 "California" 6 "Colorado" 7 "Connecticut" 8 "Delaware" 9 "Florida" 10 "Georgia" 11 "Hawaii" 12 "Idaho" 13 "Illinois" 14 "Indiana" 15 "Iowa" 16 "Kansas" 17 "Kentucky" 18 "Louisiana" 19 "Maine" 20 "Maryland" 21 "Massachusetts" 22 "Michigan" 23 "Minnesota" 24 "Mississippi" 25 "Missouri" 26 "Montana" 27 "Nebraska" 28 "Nevada" 29 "New Hampshire" 30 "New Jersey" 31 "New Mexico" 32 "New York" 33 "North Carolina" 34 "North Dakota" 35 "Ohio" 36 "Oklahoma" 37 "Oregon" 38 "Pennsylvania" 39 "Rhode Island" 40 "South Carolina" 41 "South Dakota" 42 "Tennessee" 43 "Texas" 44 "Utah" 45 "Vermont" 46 "Virginia" 47 "Washington" 48 "West Virginia" 49 "Wisconsin" 50 "Wyoming" 51 "Alberta" 52 "Labrador" 53 "New Brunswick" 54 "Nova Scotia" 55 "North West Terr." 56 "Prince Edward Is." 57 "Saskatchewen" 58 "British Columbia" 59 "Manitoba" 60 "Newfoundland" 61 "Nunavut" 62 "Ontario" 63 "Quebec" 64 "Yukon" 65 "Australian Capital Territory" 66 "New South Wales" 67 "Northern Territory" 68 "Queensland" 69 "South Australia" 70 "Tasmania" 71 "Victoria" 72 "Western Australia" 73 "Christmas Island" 74 "Cocos (Keeling) Islands" 75 "Norfolk Island" 76 "Lord Howe Island" ;
VAL_ 439 NavSpdLimit 255 "Invalid" ;
VAL_ 439 NavSpdLimitStatus 0 "Unknown" 1 "Exists (Data Available)" 2 "No Limit (no limitation eg Autobahn)" 3 "Plural data exists (data provided for durrent Time,Date etc)" ;
VAL_ 439 NavSpdLimitUnits 0 "Unknown" 1 "miles/h" 2 "km/h" 3 "Unused" ;
VAL_ 439 NumberofExitLanes 0 "Unknown" ;
VAL_ 439 NumberofLanes 0 "Unknown" ;
VAL_ 439 RightOfWay 0 "Unknown" 1 "Right of Way" 2 "Give Way" 3 "Reserved" ;
VAL_ 186 AutoHighBeamSAEModeReq 0 "Normal sensitivity" 1 "SAE Mode sensitivity" 2 "Reserved - Low sensitivity" 3 "Reserved - High sensitivity" ;
VAL_ 132 BrakeSwitchStatus 0 "Normal Condition" 1 "Brake Pedal Pressed" 2 "(Undefined)" 3 "Brake Switch Fault" ;
VAL_ 132 EngineSpeedQF 0 "The accuracy of the data is undefinable" 1 "Data is temporarily undefinable, evaluation in progress" 2 "The accuracy of the data is not within specification" 3 "The data is calculated with the specified accuracy" ;
VAL_ 132 MHStopStartStatus 0 "STARTUP" 1 "DEACTIVATED" 2 "DESELECTED" 3 "STOP AVAILABLE" 4 "STOP NOT AVAILABLE" 5 "STOPPED" 6 "PRESS CLUTCH PEDAL" 7 "SELECT NEUTRAL" 8 "PRESS BRAKE PEDAL" 9 "IMMINENT START WARNING" 10 "ERROR" 11 "EXT TEMP" 12 "DPF REGEN" 13 "BATT CHARGE" 14 "SYS DEMAND" 15 "A/C DEMAND" ;
VAL_ 132 PowerPackStatus 0 "Init" 1 "Awake" 2 "Ready" 3 "PreStarting" 4 "StartingInProgress" 5 "Running_Running" 6 "Running_Standby" 7 "Running_StartingInProgress" 8 "Running_RemoteStarted" 9 "AfterRun" ;
VAL_ 54 PedalPosProQF 0 "The accuracy of the data is undefinable" 1 "Data is temporarily undefinable, evaluation in progress" 2 "The accuracy of the data is not within specification" 3 "The data is calculated with the specified accuracy" ;
VAL_ 13 VSCHoldRequest 0 "Brake Hold NOT requested" 1 "Brake Hold requested" ;
VAL_ 46 EPASDrvDmdExcess_dup 0 "Driver Steering activity not excessive" 1 "Driver Steering activity excessive" ;
VAL_ 46 TorsionBarTorque 1023 "Data is undefinable" ;
VAL_ 46 TorsionBarTorqueQF 0 "The accuracy of the data is undefinable" 1 "Data is temporarily undefinable, evaluation in progress" 2 "The accuracy of the data is not within specification" 3 "The data is calculated with the specified accuracy" ;
VAL_ 46 TorsionBarTorqueSign 0 "Counterclockwise" 1 "Clockwise" ;
VAL_ 50 ActRoadWheelAngState 0 "not_available" 1 "FailureDetected" 2 "available" 3 "Reserved" ;
VAL_ 191 DrivSeatBeltBcklError 0 "No Fault" 1 "Fault Condition" ;
VAL_ 191 DrivSeatBeltBcklState 0 "Not Latched" 1 "Latched" ;
VAL_ 74 A1_STAT 0 "sensor ok" 1 "sensor element not populated" 2 "signal faulty" 3 "invalid value (signal faulty) 3" 4 "sensor initialising" 5 "invalid value5" 6 "invalid value (signal faulty) 6" 7 "invalid value (signal faulty) 7" 8 "sensor channel not calibrated" 9 "sensor not calibrated / not populated" 10 "invalid value (signal faulty) 10" 11 "invalid value (signal faulty) 11" 12 "initialising / not calibrated" 13 "invalid value13" 14 "invalid value (signal faulty) 14" 15 "invalid value (signal faulty) 15" ;
VAL_ 74 PSIP1_STAT 0 "sensor ok" 1 "sensor element not populated" 2 "signal faulty" 3 "invalid value (signal faulty) 3" 4 "sensor initialising" 5 "invalid value5" 6 "invalid value (signal faulty) 6" 7 "invalid value (signal faulty) 7" 8 "sensor channel not calibrated" 9 "sensor not calibrated / not populated" 10 "invalid value (signal faulty) 10" 11 "invalid value (signal faulty) 11" 12 "initialising / not calibrated" 13 "invalid value13" 14 "invalid value (signal faulty) 14" 15 "invalid value (signal faulty) 15" ;
VAL_ 76 A2_STAT 0 "sensor ok" 1 "sensor element not populated" 2 "signal faulty" 3 "invalid value (signal faulty) 3" 4 "sensor initialising" 5 "invalid value5" 6 "invalid value (signal faulty) 6" 7 "invalid value (signal faulty) 7" 8 "sensor channel not calibrated" 9 "sensor not calibrated / not populated" 10 "invalid value (signal faulty) 10" 11 "invalid value (signal faulty) 11" 12 "initialising / not calibrated" 13 "invalid value13" 14 "invalid value (signal faulty) 14" 15 "invalid value (signal faulty) 15" ;
VAL_ 76 PSIPP1_STAT 0 "sensor ok" 1 "sensor element not populated" 2 "signal faulty" 3 "invalid value (signal faulty) 3" 4 "sensor initialising" 5 "invalid value5" 6 "invalid value (signal faulty) 6" 7 "invalid value (signal faulty) 7" 8 "sensor channel not calibrated" 9 "sensor not calibrated / not populated" 10 "invalid value (signal faulty) 10" 11 "invalid value (signal faulty) 11" 12 "initialising / not calibrated" 13 "invalid value13" 14 "invalid value (signal faulty) 14" 15 "invalid value (signal faulty) 15" ;
VAL_ 86 SteeringWheelAngle 65535 "Error Marker" ;
VAL_ 86 SteeringWheelAngleSpeed 255 "Fault Condition Present" ;
VAL_ 86 SteeringWheelAngleStatus 0 "Fault condition" 1 "Steering angle not known or not initialised" 2 "Centre not confirmed (unused on L405)" 3 "Centre confirmed" ;
VAL_ 86 SteeringWheelRotDir 0 "Rotation Counterclockwise" 1 "Rotation Clockwise" ;
VAL_ 397 DemandHeight 511 "Error Marker" ;
VAL_ 397 EstimatedHeight 511 "Error Marker" ;
VAL_ 399 VCGStatus 0 "Disabled" 1 "Enabled" ;
VAL_ 655 ExteriorLightSwitchPos2 0 "Neutral" 1 "Position Light" 2 "OFF" 3 "Dipped Beam" 4 "Auto Light" ;
VAL_ 655 FrontFogLightIndication 0 "Turn Tell Tale Off" 1 "Turn Tell Tale On" 2 "Missing Signal" 3 "Initialisation" ;
VAL_ 655 MainBeamSwitch 0 "Neutral:The switch is not used." 1 "Flash: The switch is used in position one" 2 "Not applicable" 3 "Toggle: The switch is used in position two" ;
VAL_ 655 WasherFrontCmd_EUCD 0 "Off" 1 "On" ;
VAL_ 655 WasherRearCmd 0 "Off" 1 "On" ;
VAL_ 655 WiperFrontCmd_EuCD 0 "Off" 1 "Intermittent" 2 "Continous Low" 3 "Continous High" 4 "Single Stroke" ;
VAL_ 655 WiperRearCmd 0 "Off" 1 "Intermittent" 2 "Continous Low" ;
VAL_ 655 WiperStatus 0 "Wipers Off" 1 "Intermittent Wipe" 2 "Normal (Slow) Continuous Wipe" 3 "Fast Continuous Wipe" ;
VAL_ 245 ATPCProStatus 0 "ATPCPro Off" 1 "ATPCPro Reactive Only" 2 "ATPCPro Pre-emptive and Reactive" 3 "ATPCPro Fault" 4 "ATPCPro Standby" ;
VAL_ 80 KeepNetInAfterRunTCM 0 "ECU Does not require the Network" 1 "ECU Requires Network Communication" ;
VAL_ 80 TCMLockETSReq 0 "initialisation / fault /Lock" 1 "No Lock Request" 2 "Lock Request" 3 "Fault / Lock" ;
VAL_ 80 TCMParkReqAck 0 "Initial Value and Value for Position D, R and N." 1 "TCM Park Position Confirmed." 2 "TCM Processing Shift Req into Park" 3 "Fault Condition" ;
VAL_ 80 TCMStartEnable 0 "Transmisson is not in P or N (SbW - TCM does not allow start)" 1 "Transmission is in Neutral, SbW GSM is not in a driving gear an" 2 "Transmission is in Park or SbW EPRC pulled and SbW GSM is not i" 3 "To be interpreted as fault" ;
VAL_ 80 TCMText 0 "ok" 1 "Gearbox Fault" 2 "Gearbox overheating" 3 "Reselect for gear engagement" 4 "Launch Control Ready" 5 "Launch Control Active" 6 "Gearbox Overheating Recommend Low range is selected" 7 "Gearbox overheating. stop safely. Select Low Range" 8 "Dynamic Launch Not Available" 9 "Limited Gears available. Drive with Caution. Service Repair required" 10 "Gearbox Fault. Stop IMMEDIATELY . Vehicle Recovery required" 11 "Manual Shift disabled" 12 "Gearbox Fault. Stop safely. Vehicle Recovery required" 13 "Gearbox Fault. Service Repair required. Limited range available" 14 "Vehicle System fault. Gear Shifting affected. Service Repair required" 15 "Reserved" ;
VAL_ 80 TransTICStatus 0 "TIC Standby" 1 "TIC Active" 2 "TIC Not Active/Deactivating" 3 "TIC Fault" ;
VAL_ 1024 CcfAdasNCapESS 0 "Not Supported" 1 "Not Fitted" 2 "Fitted" 3 "Error" ;
VAL_ 1024 CcfParkAssistHMI 0 "Not supported" 1 "Low Line HMI" 2 "High Line Dynamic" 3 "High Line Static" 7 "Error" ;
VAL_ 1024 CcfAdaptDrvBeam 0 "Not Supported" 1 "AdaptDrvBeam Disabled" 2 "AdaptDrvBeam Enabled" 3 "Error" ;
VAL_ 1024 CcfAllWheelSteer 0 "Undefined" 1 "Not Fitted" 2 "Fitted" 3 "Error" ;
VAL_ 1024 CcfAdapDrvBeamSeg 0 "Not Supported" 1 "1 Segment" 2 "2 Segments" 3 "3 Segments" 4 "4 Segments" 5 "5 Segments" 6 "6 Segments" 7 "7 Segments" 8 "8 Segments" 9 "9 Segments" 10 "10 Segments" 11 "11 Segments" 12 "12 Segments" 13 "13 Segments" 14 "14 Segments" 15 "15 Segments" 16 "16 Segments" 17 "17 Segments" 18 "18 Segments" 19 "19 Segments" 20 "20 Segments" 21 "21 Segments" 22 "22 Segments" 23 "23 Segments" 24 "24 Segments" 25 "25 Segments" 255 "Error" ;
VAL_ 1024 ccfGenericWheelBase 0 "Undefined" 4 "Short" 8 "Standard" 12 "Long" 14 "Extended" 15 "Error" ;
VAL_ 1024 CcfSportbrake 0 "Not supported" 1 "Standard" 2 "Sportbrake" 3 "Error" ;
VAL_ 1024 CcfSuspensionType 0 "Not supported" 1 "Coil-Coil" 2 "2 Corner Air" 3 "4 Corner Air" 15 "Error" ;
VAL_ 1024 CcfVehClearGuidance 0 "Not Supported" 1 "Not Available" 2 "Available" 3 "Error" ;
VAL_ 1024 CcfAHBSensitivtyMenu 0 "Not Supported" 1 "Sensitivity Menu Disabled" 2 "Sensitivity Menu enabled" 3 "Error" ;
VAL_ 1024 CcfAHBCalibration 0 "Not Supported" 1 "Lighting Calibration 1" 2 "Lighting Calibration 2" 3 "Lighting Calibration 3" 7 "Error" ;
VAL_ 1024 CcfGlassType 0 "Undefined" 1 "Standard windscreen glass" 2 "IR protected windscreen glass" 3 "Tinted glass" 4 "Privacy glass" 5 "Standard Windscreen Glass With Blue Banner" 255 "Error" ;
VAL_ 1024 CcfHeatedWindscreen 0 "Undefined" 1 "No Heated Frontscreen/wiper park/heated jets" 2 "Heated Frontscreen only" 3 "Heated Frontscreen & heated jets only" 4 "Heated Wiper Park & heated jets only" 5 "Heated Frontscreen & wiper park & heated jets" 255 "Error" ;
VAL_ 1024 CcfHUDSubType 0 "Not Supported" 1 "HUD Not Fitted" 2 "Gen I HUD" 3 "Gen II HUD with APIX2" 4 "Gen II HUD w/o APIX2" 5 "Gen III HUD" 7 "Error" ;
VAL_ 1024 CcfAHBSystemStatus 0 "Not Supported" 1 "AHBA Not Fitted" 2 "AHBA Fitted" 3 "E" ;
VAL_ 1024 CcfSteeringWheelPosn 0 "Undefined" 1 "Left Hand Drive" 2 "Right Hand Drive" 255 "Error" ;
VAL_ 1024 CcfVehicleType 0 "Not supported" 1 "L663" 2 "L560" 3 "L551" 8 "L359 'Landrover Freelander'" 11 "L405 - Range Rover" 12 "L494 - Range Rover Sport" 13 "X152" 14 "X151" 15 "X760" 16 "X150 'Jaguar XK'" 17 "L538 'Evoke'" 18 "L550" 19 "X250 'Jaguar S-Type'" 20 "L319 'Landrover Discovey'" 21 "L320 'Landrover Range Rover Sport'" 26 "X260" 27 "X761" 28 "L462" 36 "L322 'LandRover Range Rover'" 37 "X351 'Jaguar XJ'" 39 "X540" 40 "X590" 41 "X161" 42 "X391" 43 "L460" 44 "L461" 45 "L860" 46 "X262" 47 "X393" 48 "X762" 49 "X763" 50 "L392" 51 "L361" 52 "L371" 53 "L591" 54 "L552" 55 "L561" 56 "L571" 57 "X572" 58 "L573" 59 "L465" 60 "L664" 61 "X574" 62 "L575" 63 "X770" 64 "X270" 65 "X162" 255 "Error" ;
VAL_ 321 ADAS_Stub_PartOfCalcRoute 0 "false" 1 "true" ;
VAL_ 321 ADAS_Stub_FuncRoadClass 0 "Unknown" 7 "SNA" ;
VAL_ 321 ADAS_Stub_LastStub 255 "Unknown" ;
VAL_ 321 ADAS_Stub_Update 0 "false" 1 "true" ;
VAL_ 321 ADAS_Stub_SubPathIdx 0 "Unknown" 1 "Position not in digitized Area" 2 "Position not on-road" 3 "System not calibrated" 4 "Current Segment Attributes" 5 "Stub only" 6 "This Path" 7 "Reserved" ;
VAL_ 321 ADAS_Stub_Retr 0 "false" 1 "true" ;
VAL_ 321 ADAS_Stub_PathIdx 0 "Unknown" 1 "Position not in digitized Area" 2 "Position not on-road" 3 "System not calibrated" 4 "Current Segment Attributes" 5 "Stub only" 6 "This Path" 7 "Reserved" ;
VAL_ 321 ADAS_Stub_Offset 8191 "invalid" ;
VAL_ 321 ADAS_Stub_NumOfLaneOppDir 0 "One direction road" 1 "One lane only" 2 "Two or more lanes" 3 "Unknown" ;
VAL_ 321 ADAS_Stub_NumOfLaneDrvDir 0 "Wrong direction" 6 "6 or more lanes" 7 "Unknown" ;
VAL_ 321 ADAS_Stub_MsgType 0 "SNA" 1 "POSITION" 2 "SEGMENT" 3 "STUB" 4 "PROFILE_SHORT" 5 "PROFILE_LONG" 6 "META_DATA" 7 "RESERVED" ;
VAL_ 321 ADAS_Stub_FormOfWay 0 "Unknown" 1 "Freeway without Slip Roads" 2 "Multiply Carriageway" 3 "Single Carriageway" 4 "Roundabout" 5 "Special Traffic Figure" 6 "Reserved6" 7 "Reserved7" 8 "Parallel Road" 9 "Slip Road on Freeway" 10 "Slip Road not on Freeway" 11 "Service or Frontage Road" 12 "Entrance to or Exit of Car Park" 13 "Entrance to or Exit to Service" 14 "Pedestrian Zone" 15 "SNA" ;
VAL_ 321 ADAS_Stub_RtOfWay 0 "Path has rt-of-way over sub-path" 1 "Sub-path has rt-of-way over path" 2 "Unknown" 3 "Invalid" ;
VAL_ 321 ADAS_Stub_CmplxInsct 0 "False" 1 "True" 2 "Unknown" 3 "Invalid" ;
VAL_ 321 ADAS_Stub_RelProbb 0 "Turn not allowed" 31 "Unknown" ;
VAL_ 321 ADAS_Stub_TurnAngl 0 "In path direction" 1 "1.417 deg right from path dir" 126 "178.583 deg right" 127 "Opposite direction" 128 "178.583 deg left" 253 "1.417 deg left from path dir" 254 "Unknown" 255 "SNA" ;
VAL_ 340 ESP_NotAvailable 0 "Available" 1 "Not Available" ;
VAL_ 2 ISA_SLWF_TYPE 0 "NONE" 1 "VISUAL_ONLY" 2 "VISUAL_ACOUSTIC_CASCADED" 3 "VISUAL_HAPTIC_CASCADED" 4 "VISUAL_ACOUSTIC_HAPTIC_CASCADED" 5 "HAPTIC_ONLY" ;
VAL_ 793 SteeringWheelCapacitive 0 "unknown" 1 "OffWheel" 2 "OnWheel" ;
VAL_ 323 ADAS_Seg_PartOfCalcRoute 0 "False" 1 "True" 2 "Unknown" 3 "Invalid" ;
VAL_ 323 ADAS_Seg_RelProbb 0 "Turn not allowed" 31 "Unknown" ;
VAL_ 323 ADAS_Seg_Offset 8191 "invalid" ;
VAL_ 323 ADAS_Seg_Retr 0 "false" 1 "true" ;
VAL_ 323 ADAS_Seg_PathIdx 0 "Unknown" 1 "Position not in digitized Area" 2 "Position not on-road" 3 "System not calibrated" 4 "Current Segment Attributes" 5 "Stub only" 6 "This Path" 7 "Reserved" ;
VAL_ 323 ADAS_Seg_MsgType 0 "SNA" 1 "POSITION" 2 "SEGMENT" 3 "STUB" 4 "PROFILE_SHORT" 5 "PROFILE_LONG" 6 "META_DATA" 7 "RESERVED" ;
VAL_ 323 ADAS_Seg_FormOfWay 0 "Unknown" 1 "Freeway without Slip Roads" 2 "Multiply Carriageway" 3 "Single Carriageway" 4 "Roundabout" 5 "Special Traffic Figure" 6 "Reserved6" 7 "Reserved7" 8 "Parallel Road" 9 "Slip Road on Freeway" 10 "Slip Road not on Freeway" 11 "Service or Frontage Road" 12 "Entrance to or Exit of Car Park" 13 "Entrance to or Exit to Service" 14 "Pedestrian Zone" 15 "SNA" ;
VAL_ 323 ADAS_Seg_CmplxInsct 0 "False" 1 "True" 2 "Unknown" 3 "Invalid" ;
VAL_ 323 ADAS_Seg_BuildUpArea 0 "False" 1 "True" 2 "Unknown" 3 "Invalid" ;
VAL_ 323 ADAS_Seg_DividedRoad 0 "False" 1 "True" 2 "Unknown" 3 "Invalid" ;
VAL_ 323 ADAS_Seg_Bridge 0 "False" 1 "True" 2 "Unknown" 3 "Invalid" ;
VAL_ 323 ADAS_Seg_Tunnel 0 "False" 1 "True" 2 "Unknown" 3 "Invalid" ;
VAL_ 323 ADAS_Seg_NumOfLaneOppDir 0 "One direction road" 1 "One lane only" 2 "Two or more lanes" 3 "Unknown" ;
VAL_ 323 ADAS_Seg_NumOfLaneDrvDir 0 "Wrong direction" 6 "6 or more lanes" 7 "Unknown" ;
VAL_ 323 ADAS_Seg_EffSpdLmtType 0 "Implicit" 1 "Explicit_on_sign" 2 "Explicit_by_night" 3 "Explicit_by_day" 4 "Explicit_time_of_day" 5 "Explicit_rain" 6 "Explicit_snow" 7 "Unknown" ;
VAL_ 323 ADAS_Seg_EffSpdLmt 0 "Unknown" 1 "5 kmph or mph" 2 "7 kmph or mph" 3 "10 kmph or mph" 4 "15 kmph or mph" 5 "20 kmph or mph" 6 "25 kmph or mph" 7 "30 kmph or mph" 8 "35 kmph or mph" 9 "40 kmph or mph" 10 "45 kmph or mph" 11 "50 kmph or mph" 12 "55 kmph or mph" 13 "60 kmph or mph" 14 "65 kmph or mph" 15 "70 kmph or mph" 16 "75 kmph or mph" 17 "80 kmph or mph" 18 "85 kmph or mph" 19 "90 kmph or mph" 20 "95 kmph or mph" 21 "100 kmph or mph" 22 "105 kmph or mph" 23 "110 kmph or mph" 24 "115 kmph or mph" 25 "120 kmph or mph" 26 "130 kmph or mph" 27 "140 kmph or mph" 28 "150 kmph or mph" 29 "160 kmph or mph" 30 "Unlimited" 31 "SNA" ;
VAL_ 323 ADAS_Seg_FuncRoadClass 0 "Unknown" 7 "SNA" ;
VAL_ 323 ADAS_Seg_Update 0 "false" 1 "true" ;
VAL_ 289 AirbagCrashIntensity 0 "No Crash" 1 "Intensity level 1" 2 "Intensity level 2" ;
VAL_ 289 ASR_Intervention 0 "No ASR Intervention" 1 "ASR Intervention" ;
VAL_ 289 BrakePressure_Qbit 0 "Normal operation" 1 "Init or Failure value" ;
VAL_ 289 BrakeTemperatureStatus 0 "Normal" 1 "Overheat" ;
VAL_ 289 ClutchPedal 0 "Not Pressed" 1 "Pressed" ;
VAL_ 289 ClutchTemperatureStatus 0 "Initialization" 1 "Normal" 2 "Overheat" 3 "Clutch protection active" ;
VAL_ 289 DecelerationEnable 0 "Not Active" 1 "Active" ;
VAL_ 289 DriverBraked_Qbit 0 "Normal operation" 1 "Init or Failure value" ;
VAL_ 289 EBV_Intervention 0 "No EBV Intervention" 1 "EBV Intervention" ;
VAL_ 289 ECD_Failure 0 "ECD in operation" 1 "ECD failure" ;
VAL_ 289 ECD_NotAvailable 0 "ECD Available" 1 "ECD not Available" ;
VAL_ 289 EDS_Intervention 0 "No EDS Intervention" 1 "EDS Intervention" ;
VAL_ 289 EmergencyBrakeActive 0 "Not Active" 1 "Active" ;
VAL_ 289 ESP_AutoholdActive 0 "ESP Autohold not active" 1 "ESP Autohold active" ;
VAL_ 289 ESP_ConsistentWithACC 0 "ACC Counter consistent with ESP" 1 "ACC Count not consist with ESP" ;
VAL_ 289 ESP_StandstillConfirmed 0 "Standstill Pos not confirmed" 1 "Standstill Pos confirmed" ;
VAL_ 289 MSR_Intervention 0 "No MSR Intervention" 1 "MSR Intervention" ;
VAL_ 289 SteeringAngularSpeed_Qbit 0 "Normal operation" 1 "Init or Failure value" ;
VAL_ 289 SteeringWheelAngle_Qbit 0 "Normal operation" 1 "Init or Failure value" ;
VAL_ 289 Velocity_Qbit 0 "Normal operation" 1 "Init or Failure value" ;
VAL_ 289 WheelCircumference_QBit 0 "Normal operation" 1 "Init or Failure value" ;
VAL_ 327 ADAS_Posn_PosProbb 31 "Invalid" ;
VAL_ 327 ADAS_Posn_CurLane 0 "Unknown" 1 "Emergency lane" 2 "Single-lane road" 3 "Left-most lane" 4 "Right-most lane" 5 "Middle lane on 3+ lane road" 6 "Reserved" 7 "SNA" ;
VAL_ 327 ADAS_Posn_Spd 511 "UNKNOWN" ;
VAL_ 327 ADAS_Posn_RelHead 0 "In path direction" 1 "1.417 deg right from path dir" 126 "178.583 deg right" 127 "Opposite direction" 252 "178.583 deg left" 253 "1.417 deg left from path dir" 254 "Unknown" 255 "SNA" ;
VAL_ 327 ADAS_Posn_Age 510 "Older than 2545 ms" 511 "Invalid" ;
VAL_ 327 ADAS_Posn_PathIdx 0 "Unknown" 1 "Position not in digitized Area" 2 "Position not on-road" 3 "System not calibrated" 4 "Current Segment Attributes" 5 "Stub only" 6 "This Path" 7 "Reserved" ;
VAL_ 327 ADAS_Posn_Offset 8191 "invalid" ;
VAL_ 327 ADAS_Posn_MsgTyp 0 "SNA" 1 "POSITION" 2 "SEGMENT" 3 "STUB" 4 "PROFILE_SHORT" 5 "PROFILE_LONG" 6 "META_DATA" 7 "RESERVED" ;
VAL_ 1809 VRS_sign_new_sign_flag 0 "NO" 1 "YES" ;
VAL_ 328 YawRate_Qbit 0 "Init or Failure value" 1 "FoggRisk" ;
VAL_ 787 FCWAlertMsg 0 "No Warning" 1 "Warning 1" 2 "Warning 2" 3 "Warning 3" 4 "Warning 4" 5 "Warning 5" 6 "Warning 6" 7 "Warning 7" ;
VAL_ 293 WheelPulseIndicatorFL 1021 "Initialization" 1022 "Invalid" 1023 "Failure" ;
VAL_ 293 WheelPulseIndicatorFR 1021 "Initialization" 1022 "Invalid" 1023 "Failure" ;
VAL_ 293 WheelPulseIndicatorRL 1021 "Initialization" 1022 "Invalid" 1023 "Failure" ;
VAL_ 293 WheelPulseIndicatorRR 1021 "Initialization" 1022 "Invalid" 1023 "Failure" ;
VAL_ 293 WheelPulseSensorFL_Qbit 0 "Normal Operation" 1 "Init or failure value" ;
VAL_ 293 WheelPulseSensorFR_Qbit 0 "Normal Operation" 1 "Init or failure value" ;
VAL_ 293 WheelPulseSensorRL_Qbit 0 "Normal Operation" 1 "Init or failure value" ;
VAL_ 293 WheelPulseSensorRR_Qbit 0 "Normal Operation" 1 "Init or failure value" ;
VAL_ 293 FoggingRiskWindscreen 0 "noFoggRisk" 1 "FoggRisk" ;
VAL_ 293 SideCrashDriver 0 "no crash" 1 "crash" ;
VAL_ 293 SideCrashCodriver 0 "no crash" 1 "crash" ;
VAL_ 293 RolloverCrash 0 "no crash" 1 "crash" ;
VAL_ 293 FrontCrash 0 "no crash" 1 "crash" ;
VAL_ 293 RearCrash 0 "no crash" 1 "crash" ;
VAL_ 788 ACC_Acceleration 2046 "Neutral" 2047 "Failure" ;
VAL_ 788 ACC_Dec2StopRequest 0 "not active" 1 "active" ;
VAL_ 788 ACC_DriveOffRequest 0 "not active" 1 "active" ;
VAL_ 788 ACC_MinimalBraking 0 "prefer system brake" 1 "prefer engine brake" ;
VAL_ 788 ACC_ReducedDynamicDriveoff 0 "normal dynamic" 1 "educed dynamic" ;
VAL_ 788 ACC_StartStopInfo 0 "Engine stop request is allowed" 1 "Engine stop is forbidden" 2 "Engine start request" 3 "Failure" ;
VAL_ 788 ACC_StatusACC 0 "ACC Initialization" 1 "ACC Offline" 2 "ACC Passive" 3 "ACC Active" 4 "ACC Suspend" 5 "ACC Hold" 6 "ACC Switch Off" 7 "ACC Failure" ;
VAL_ 788 ACC_StoppingDistance 2046 "Neutral" 2047 "Failure" ;
VAL_ 788 ACC_Type 0 "ACC type base" 1 "ACC type follow2stop" 2 "ACC type stop and go" 3 "ACC not equipped" ;
VAL_ 257 AebBrakeFeatureStatus 0 "enabled" 1 "disabled" ;
VAL_ 257 AebWarnFeatureStatus 0 "enabled" 1 "disabled" ;
VAL_ 257 DriverSeatBeltPosition 0 "Not in operation" 1 "Failure or initialization" 2 "Unlocked" 3 "Locked" ;
VAL_ 257 EngineRunningStatus 0 "Error" 1 "Key out" 2 "Key recently out" 3 "Key approved" 4 "Ignition" 5 "Running" ;
VAL_ 257 GasPedalPressedInKickDownMode 0 "pedal NOT in kick down mode" 1 "pedal in kick down mode" ;
VAL_ 257 TrailerConnection 0 "No Trailer connected" 1 "Trailer connected" ;
VAL_ 297 ADAS_ProfLong_Update 0 "false" 1 "true" ;
VAL_ 297 ADAS_ProfLong_Retr 0 "false" 1 "true" ;
VAL_ 297 ADAS_ProfLong_PathIdx 0 "Unknown" 1 "Position not in digitized Area" 2 "Position not on-road" 3 "System not calibrated" 4 "Current Segment Attributes" 5 "Stub only" 6 "This Path" 7 "Reserved" ;
VAL_ 297 ADAS_ProfLong_Offset 8191 "invalid" ;
VAL_ 297 ADAS_ProfLong_MsgType 0 "SNA" 1 "POSITION" 2 "SEGMENT" 3 "STUB" 4 "PROFILE_SHORT" 5 "PROFILE_LONG" 6 "META_DATA" 7 "RESERVED" ;
VAL_ 297 ADAS_ProfLong_CtrlPoint 0 "false" 1 "true" ;
VAL_ 297 ADAS_ProfLong_ProfType 0 "Invalid" 1 "Longitude" 2 "Latitude" 3 "Reserved3" 4 "Reserved4" 5 "Reserved5" 6 "Reserved6" 7 "Reserved7" 8 "Reserved8" 9 "Reserved9" 10 "Reserved10" 11 "Reserved11" 12 "Reserved12" 13 "Reserved13" 14 "Reserved14" 15 "Reserved15" 16 "System_Specific" 17 "System_Specific" 18 "System_Specific" 19 "System_Specific" 20 "System_Specific" 21 "System_Specific" 22 "System_Specific" 23 "System_Specific" 24 "System_Specific" 25 "System_Specific" 26 "System_Specific" 27 "System_Specific" 28 "System_Specific" 29 "System_Specific" 30 "System_Specific" 31 "System_Specific" ;
VAL_ 804 ACC_AcousticalWarning 0 "No acoustic warning" 1 "High prio acoustic warning" 2 "Low prio acoustic warning" ;
VAL_ 804 ACC_DisplayedStatus 0 "ACC Mainswitch Off" 1 "ACC Initialization" 2 "ACC Passive" 3 "ACC Active" 4 "ACC Override" 5 "ACC Deactivate" 6 "ACC Reversible failure" 7 "ACC Irreversible failure" ;
VAL_ 804 ACC_DisplayedTgap 0 "Timegap will not be displayed" 1 "Timegap 1" 2 "Timegap 2" 3 "Timegap 3" 4 "Timegap 4" 5 "Timegap 5" 6 "Timegap 6" 7 "Timegap 7" ;
VAL_ 804 ACC_DisplayPrio 0 "High prio" 1 "Medium prio" 2 "Low prio" 3 "No prio" ;
VAL_ 804 ACC_DrivingProgramStatus 0 "Initialization" 1 "Avaiable" 2 "Not avaiable" 3 "Not in synchron with driver" ;
VAL_ 804 ACC_TgapMarker 0 "Timegap display not requested" 1 "Timegap display requested" ;
VAL_ 826 PF_CMRObj10HorSpeed 254 "init" 255 "not available" ;
VAL_ 826 PF_CMRObj10VerPos 254 "init" 255 "not available" ;
VAL_ 826 PF_CMRObj10ID 0 "no object detected" 254 "init" 255 "not available" ;
VAL_ 826 PF_CMRObj10HorPosRight 4094 "init" 4095 "not available" ;
VAL_ 826 PF_CMRObj10HorSpeedSign 0 "OBJ_HOR_SPEED_SIGN_LEFT" 1 "OBJ_HOR_SPEED_SIGN_RIGHT" 15 "NOT_AVAILABLE" ;
VAL_ 826 PF_CMRObj10HorPosLeft 4094 "init" 4095 "not available" ;
VAL_ 826 PF_CMRObj10Type 0 "no object" 1 "oncoming object, headlamps detected" 2 "preceding object, rear lamps detected" 3 "reflective object, low reflection detected" 4 "reflective object, mid reflection detected" 5 "reflective object, high reflection detected" 6 "reflective object, low minus reflection detected" 7 "reflective object, low plus reflection detected" 8 "reflective object, mid minus reflection detected" 9 "reflective object, mid plus reflection detected" 10 "reflective object, high minus reflection detected" 11 "reflective object, high plus reflection detected" 14 "Init" 15 "not available" ;
VAL_ 826 PF_CMRObj10Dist 251 ">500m" 254 "init" 255 "not available" ;
VAL_ 827 PF_CMRObj11HorSpeed 254 "init" 255 "not available" ;
VAL_ 827 PF_CMRObj11VerPos 254 "init" 255 "not available" ;
VAL_ 827 PF_CMRObj11ID 0 "no object detected" 254 "init" 255 "not available" ;
VAL_ 827 PF_CMRObj11HorPosRight 4094 "init" 4095 "not available" ;
VAL_ 827 PF_CMRObj11HorSpeedSign 0 "OBJ_HOR_SPEED_SIGN_LEFT" 1 "OBJ_HOR_SPEED_SIGN_RIGHT" 15 "NOT_AVAILABLE" ;
VAL_ 827 PF_CMRObj11HorPosLeft 4094 "init" 4095 "not available" ;
VAL_ 827 PF_CMRObj11Type 0 "no object" 1 "oncoming object, headlamps detected" 2 "preceding object, rear lamps detected" 3 "reflective object, low reflection detected" 4 "reflective object, mid reflection detected" 5 "reflective object, high reflection detected" 6 "reflective object, low minus reflection detected" 7 "reflective object, low plus reflection detected" 8 "reflective object, mid minus reflection detected" 9 "reflective object, mid plus reflection detected" 10 "reflective object, high minus reflection detected" 11 "reflective object, high plus reflection detected" 14 "Init" 15 "not available" ;
VAL_ 827 PF_CMRObj11Dist 251 ">500m" 254 "init" 255 "not available" ;
VAL_ 828 PF_CMRObj12HorSpeed 254 "init" 255 "not available" ;
VAL_ 828 PF_CMRObj12VerPos 254 "init" 255 "not available" ;
VAL_ 828 PF_CMRObj12HorPosRight 4094 "init" 4095 "not available" ;
VAL_ 828 PF_CMRObj12HorSpeedSign 0 "OBJ_HOR_SPEED_SIGN_LEFT" 1 "OBJ_HOR_SPEED_SIGN_RIGHT" 15 "NOT_AVAILABLE" ;
VAL_ 828 PF_CMRObj12HorPosLeft 4094 "init" 4095 "not available" ;
VAL_ 828 PF_CMRObj12Type 0 "no object" 1 "oncoming object, headlamps detected" 2 "preceding object, rear lamps detected" 3 "reflective object, low reflection detected" 4 "reflective object, mid reflection detected" 5 "reflective object, high reflection detected" 6 "reflective object, low minus reflection detected" 7 "reflective object, low plus reflection detected" 8 "reflective object, mid minus reflection detected" 9 "reflective object, mid plus reflection detected" 10 "reflective object, high minus reflection detected" 11 "reflective object, high plus reflection detected" 14 "Init" 15 "not available" ;
VAL_ 828 PF_CMRObj12ID 0 "no object detected" 254 "init" 255 "not available" ;
VAL_ 828 PF_CMRObj12Dist 251 ">500m" 254 "init" 255 "not available" ;
VAL_ 829 PF_CMRObj13HorSpeed 254 "init" 255 "not available" ;
VAL_ 829 PF_CMRObj13VerPos 254 "init" 255 "not available" ;
VAL_ 829 PF_CMRObj13ID 0 "no object detected" 254 "init" 255 "not available" ;
VAL_ 829 PF_CMRObj13HorPosRight 4094 "init" 4095 "not available" ;
VAL_ 829 PF_CMRObj13HorSpeedSign 0 "OBJ_HOR_SPEED_SIGN_LEFT" 1 "OBJ_HOR_SPEED_SIGN_RIGHT" 15 "NOT_AVAILABLE" ;
VAL_ 829 PF_CMRObj13HorPosLeft 4094 "init" 4095 "not available" ;
VAL_ 829 PF_CMRObj13Dist 251 ">500m" 254 "init" 255 "not available" ;
VAL_ 829 PF_CMRObj13Type 0 "no object" 1 "oncoming object, headlamps detected" 2 "preceding object, rear lamps detected" 3 "reflective object, low reflection detected" 4 "reflective object, mid reflection detected" 5 "reflective object, high reflection detected" 6 "reflective object, low minus reflection detected" 7 "reflective object, low plus reflection detected" 8 "reflective object, mid minus reflection detected" 9 "reflective object, mid plus reflection detected" 10 "reflective object, high minus reflection detected" 11 "reflective object, high plus reflection detected" 14 "Init" 15 "not available" ;
VAL_ 265 EngineControllerStatus 0 "Mainswitch off" 1 "Initialization" 2 "Passive" 3 "Active" 4 "Override" 5 "Brake only mode" 6 "Reversible failure" 7 "Irreversible failure" ;
VAL_ 265 EngineRPM 65535 "Failure" ;
VAL_ 265 EngineRPM_Qbit 0 "Normal Operation" 1 "Init or Failure Value" ;
VAL_ 265 Gateway1Timeout 0 "Actual" 1 "Outdated" ;
VAL_ 265 Gateway2Timeout 0 "Actual" 1 "Outdated" ;
VAL_ 265 Gateway3Timeout 0 "Actual" 1 "Outdated" ;
VAL_ 265 Gateway4Timeout 0 "Actual" 1 "Outdated" ;
VAL_ 265 Gateway5Timeout 0 "Actual" 1 "Outdated" ;
VAL_ 265 LimiterActive 0 "Limiter not activated" 1 "Limiter activated" ;
VAL_ 265 RoadSlope 0 "Init Value" 255 "Failure" ;
VAL_ 265 RoadSlope_Qbit 0 "Normal Operation" 1 "Init or Failure Value" ;
VAL_ 265 StartStop_DriverRequest 0 "Initialization" 1 "Stop forbidden by driver" 2 "Stop released by driver" 3 "Stop requested by driver" ;
VAL_ 265 StartStop_EngineStarting 0 "Engine stopping is not active" 1 "Engine stopping is active" ;
VAL_ 265 StartStop_EngineStopping 0 "Engine starting is not active" 1 "Engine starting is active" ;
VAL_ 265 StartStop_Status 0 "Not available" 1 "Active, not cleared" 2 "Active, fully cleared" 3 "Active, partially cleared" ;
VAL_ 265 ThrottleRaw_Qbit 0 "Init or Failure Value" 1 "Limiter activated" ;
VAL_ 265 VehicleMass 255 "Failure" ;
VAL_ 265 VehicleMass_Qbit 0 "Init or Failure Value" 1 "Limiter activated" ;
VAL_ 830 PF_CMRObj14HorSpeed 254 "init" 255 "not available" ;
VAL_ 830 PF_CMRObj14VerPos 254 "init" 255 "not available" ;
VAL_ 830 PF_CMRObj14ID 0 "no object detected" 254 "init" 255 "not available" ;
VAL_ 830 PF_CMRObj14HorPosRight 4094 "init" 4095 "not available" ;
VAL_ 830 PF_CMRObj14HorSpeedSign 0 "OBJ_HOR_SPEED_SIGN_LEFT" 1 "OBJ_HOR_SPEED_SIGN_RIGHT" 15 "NOT_AVAILABLE" ;
VAL_ 830 PF_CMRObj14HorPosLeft 4094 "init" 4095 "not available" ;
VAL_ 830 PF_CMRObj14Type 0 "no object" 1 "oncoming object, headlamps detected" 2 "preceding object, rear lamps detected" 3 "reflective object, low reflection detected" 4 "reflective object, mid reflection detected" 5 "reflective object, high reflection detected" 6 "reflective object, low minus reflection detected" 7 "reflective object, low plus reflection detected" 8 "reflective object, mid minus reflection detected" 9 "reflective object, mid plus reflection detected" 10 "reflective object, high minus reflection detected" 11 "reflective object, high plus reflection detected" 14 "Init" 15 "not available" ;
VAL_ 830 PF_CMRObj14Dist 251 ">500m" 254 "init" 255 "not available" ;
VAL_ 870 ClfFeatureCoded 0 "not_coded" 1 "coded" ;
VAL_ 870 ClfFeatureStatus 0 "disabled" 1 "enabled" ;
VAL_ 831 PF_CMRObj15HorSpeed 254 "init" 255 "not available" ;
VAL_ 831 PF_CMRObj15VerPos 254 "init" 255 "not available" ;
VAL_ 831 PF_CMRObj15ID 0 "no object detected" 254 "init" 255 "not available" ;
VAL_ 831 PF_CMRObj15HorPosRight 4094 "init" 4095 "not available" ;
VAL_ 831 PF_CMRObj15HorSpeedSign 0 "OBJ_HOR_SPEED_SIGN_LEFT" 1 "OBJ_HOR_SPEED_SIGN_RIGHT" 15 "NOT_AVAILABLE" ;
VAL_ 831 PF_CMRObj15HorPosLeft 4094 "init" 4095 "not available" ;
VAL_ 831 PF_CMRObj15Type 0 "no object" 1 "oncoming object, headlamps detected" 2 "preceding object, rear lamps detected" 3 "reflective object, low reflection detected" 4 "reflective object, mid reflection detected" 5 "reflective object, high reflection detected" 6 "reflective object, low minus reflection detected" 7 "reflective object, low plus reflection detected" 8 "reflective object, mid minus reflection detected" 9 "reflective object, mid plus reflection detected" 10 "reflective object, high minus reflection detected" 11 "reflective object, high plus reflection detected" 14 "Init" 15 "not available" ;
VAL_ 831 PF_CMRObj15Dist 251 ">500m" 254 "init" 255 "not available" ;
VAL_ 832 PF_CMRObj16HorSpeed 254 "init" 255 "not available" ;
VAL_ 832 PF_CMRObj16VerPos 254 "init" 255 "not available" ;
VAL_ 832 PF_CMRObj16ID 0 "no object detected" 254 "init" 255 "not available" ;
VAL_ 832 PF_CMRObj16HorPosRight 4094 "init" 4095 "not available" ;
VAL_ 832 PF_CMRObj16HorSpeedSign 0 "OBJ_HOR_SPEED_SIGN_LEFT" 1 "OBJ_HOR_SPEED_SIGN_RIGHT" 15 "NOT_AVAILABLE" ;
VAL_ 832 PF_CMRObj16HorPosLeft 4094 "init" 4095 "not available" ;
VAL_ 832 PF_CMRObj16Type 0 "no object" 1 "oncoming object, headlamps detected" 2 "preceding object, rear lamps detected" 3 "reflective object, low reflection detected" 4 "reflective object, mid reflection detected" 5 "reflective object, high reflection detected" 6 "reflective object, low minus reflection detected" 7 "reflective object, low plus reflection detected" 8 "reflective object, mid minus reflection detected" 9 "reflective object, mid plus reflection detected" 10 "reflective object, high minus reflection detected" 11 "reflective object, high plus reflection detected" 14 "Init" 15 "not available" ;
VAL_ 832 PF_CMRObj16Dist 251 ">500m" 254 "init" 255 "not available" ;
VAL_ 864 AEBPActive 0 "disabled" 1 "enabled" ;
VAL_ 864 AEBFActive 0 "disabled" 1 "enabled" ;
VAL_ 864 ADAS_WarnType_FCW 0 "Off" 1 "Reserved" 2 "Standby" 3 "Active" 4 "Fault" 5 "Reserved" 6 "Reserved" 7 "Reserved" ;
VAL_ 864 ADAS_WarnTyp_FCWAEB 0 "Reserved" 1 "Unknown" 2 "Pedestrian" 3 "Car" 4 "Truck" 5 "Cyclist" 6 "Bus" 7 "Reserved" ;
VAL_ 864 ADAS_Sts_FCW 0 "Off" 1 "Reserved" 2 "Standby" 3 "Active" 4 "Fault" 5 "Reserved" 6 "Reserved" 7 "Reserved" ;
VAL_ 864 ADAS_FwdWarnFltTxt 0 "Default" 1 "FCW Failure" ;
VAL_ 864 ADAS_Sts_AEB 0 "Off" 1 "Reserved" 2 "Standby" 3 "Active" 4 "Fault" 5 "Reserved" 6 "Reserved" 7 "Reserved" ;
VAL_ 864 AebFunctionStatus 0 "disabled" 1 "enabled" ;
VAL_ 864 AEBOncomingFeatureStatus 0 "disabled" 1 "enabled" ;
VAL_ 865 ADAS_FCWSwtFb 0 "Default" 1 "Switch Off" 2 "Switch On" 3 "Fault" ;
VAL_ 865 ADAS_AEBSwtFb 0 "Default" 1 "Switch Off" 2 "Switch On" 3 "Fault" ;
VAL_ 1808 VRS_line_boundarytype 0 "LANE_MARKING" 1 "ROAD_EDGE" 2 "CURB" 3 "TAR_JOINT" 4 "ZEBRA_CROSSING_LINE" 5 "STOP_LINE" 6 "PICTOGRAM" ;
VAL_ 1808 VRS_line_marking_colorype 0 "UNKNOWN" 1 "WHITE" 2 "RED" 3 "YELLOW" 4 "BLUE" ;
VAL_ 1808 VRS_line_marking_dashype 0 "UNKNOWN" 1 "SOLID" 2 "DASHED" ;
VAL_ 1808 VRS_line_new_line_flag 0 "NO" 1 "YES" ;
VAL_ 791 TSRAddSign1 0 "no add sign" 1 "add rain" 2 "add snow" 3 "add time" ;
VAL_ 791 TSRMainSign1 0 "No Display (Unknown)" 1 "Cancelled" 2 "5" 3 "10" 4 "100" 5 "110" 6 "115" 7 "120" 8 "125" 9 "130" 10 "135" 11 "140" 12 "145" 49 "150" ;
VAL_ 792 TSRNextSpdLimit 0 "No Display (Unknown)" 1 "Cancelled" 2 "5" 3 "10" 4 "100" 5 "110" 6 "115" 7 "120" 8 "125" 9 "130" 10 "135" 11 "140" 12 "145" 49 "150" ;
VAL_ 305 ADAS_Meta_MsgType 0 "SNA" 1 "POSITION" 2 "SEGMENT" 3 "STUB" 4 "PROFILE_SHORT" 5 "PROFILE_LONG" 6 "META_DATA" 7 "RESERVED" ;
VAL_ 305 ADAS_Meta_MapProvider 0 "Unknown" 1 "NAVTEQ" 2 "TeleAtlas" 3 "Zenrin" 4 "Reserverd" 5 "Reserverd" 6 "Reserverd" 7 "SNA" ;
VAL_ 305 ADAS_Meta_HwVer 0 "Unknown" ;
VAL_ 305 ADAS_Meta_SpdUnits 0 "kilometers/hour" 1 "Miles/hour" ;
VAL_ 305 ADAS_Meta_DrvSide 0 "Left-side driving" 1 "Right-side driving" ;
VAL_ 305 ADAS_Meta_RegionCode 0 "Unknown" 32767 "SNA" ;
VAL_ 305 ADAS_Meta_CountryCode 0 "UNKNOWN" 276 "DEU" ;
VAL_ 513 SelfGlaring 0 "not detected" 1 "10%" 2 "20%" 3 "30%" 4 "40%" 5 "50%" 6 "60%" 7 "70%" 8 "80%" 9 "90%" 10 "100%" 14 "init" 15 "not available" ;
VAL_ 513 CamRoadIllum 0 "not detected" 1 "detected" 14 "init" 15 "not available" ;
VAL_ 513 CamTrafficStyle 0 "unknown" 1 "right hand traffic" 2 "left hand traffic" 14 "init" 15 "not available" ;
VAL_ 513 CamObjNum 0 "no objects detected" 1 "1 object detected" 2 "2 objects detected" 3 "3 objects detected" 4 "4 objects detected" 5 "5 objects detected" 6 "6 objects detected" 7 "7 objects detected" 8 "8 objects detected" 9 "unused 9" 10 "unused 10" 11 "more than 8 objects detected" 12 "unused 12" 13 "unused 13" 14 "init" 15 "not available" ;
VAL_ 513 AutoHighBeamSAEModeSta 0 "Normal sensitivity" 1 "SAE Mode sensitivity" 2 "Reserved - Low sensitivity" 3 "Reserved - High sensitivity" ;
VAL_ 513 AutoHighBeamReq 0 "Dipped beam recommended" 1 "Main beam recommended" ;
VAL_ 513 HandOfTrafficSta 0 "Traffic drives on the LHS" 1 "Traffic drives on the RHS" ;
VAL_ 513 CamAmbientLight 0 "unknown" 1 "day" 2 "night" 14 "init" 15 "not available" ;
VAL_ 513 CamStatus 0 "ON, passive" 1 "ON, active" 2 "ON, reduced sight" 3 "ON, failure" 4 "OFF, not coded" 14 "init" 15 "not available" ;
VAL_ 786 TSRDisplayEnable 0 "Displa Disabled" 1 "Display Enabled (default)" ;
VAL_ 786 TSROperatingStatus 0 "Off" 1 "Fusion Mode" 2 "Vision Only Mode" 3 "Navigation Only Mode" 4 "Country Not Supported" 5 "Not Used" 6 "Not Used" 7 "Fault" ;
VAL_ 786 TSRSpdLimitUnits 0 "Unkown (default)" 1 "k/mh" 2 "Mph" 3 "Not Used" ;
VAL_ 311 ADAS_ProfShort_Update 0 "false" 1 "true" ;
VAL_ 311 ADAS_ProfShort_ProfType 0 "Invalid" 1 "Curvature" 2 "Route_Numbers" 3 "Slope_step" 4 "Slope_linear" 5 "Road_Accessibility_Bitfield" 6 "Road_Condition_Bitfield" 7 "Var_Spd_Sign_Posn_Bitfield" 8 "Heading_Change" 9 "Reserved9" 10 "Reserved10" 11 "Reserved11" 12 "Reserved12" 13 "Reserved13" 14 "Reserved14" 15 "Reserved15" 16 "System_Specific" 17 "System_Specific" 18 "System_Specific" 19 "System_Specific" 20 "System_Specific" 21 "System_Specific" 22 "System_Specific" 23 "System_Specific" 24 "System_Specific" 25 "System_Specific" 26 "System_Specific" 27 "System_Specific" 28 "System_Specific" 29 "System_Specific" 30 "System_Specific" 31 "System_Specific" ;
VAL_ 311 ADAS_ProfShort_Retr 0 "false" 1 "true" ;
VAL_ 311 ADAS_ProfShort_PathIdx 0 "Unknown" 1 "Position not in digitized Area" 2 "Position not on-road" 3 "System not calibrated" 4 "Current Segment Attributes" 5 "Stub only" 6 "This Path" 7 "Reserved" ;
VAL_ 311 ADAS_ProfShort_Offset 8191 "invalid" ;
VAL_ 311 ADAS_ProfShort_MsgType 0 "SNA" 1 "POSITION" 2 "SEGMENT" 3 "STUB" 4 "PROFILE_SHORT" 5 "PROFILE_LONG" 6 "META_DATA" 7 "RESERVED" ;
VAL_ 311 ADAS_ProfShort_Dist1 0 "no other profile values are defi" ;
VAL_ 311 ADAS_ProfShort_CtrlPoint 0 "false" 1 "true" ;
VAL_ 785 ElkoFeatureStatus 0 "Off" 1 "ON" 2 "Active" 3 "Ready" 4 "Standby" 5 "TempError" 6 "PermError" ;
VAL_ 785 ElkoLineTrackingLeft 0 "Active" 1 "Ready" 2 "Standby" ;
VAL_ 785 ElkoLineTrackingRight 0 "Active" 1 "Ready" 2 "Standby" ;
VAL_ 785 ElkreFeatureStatus 0 "Off" 1 "ON" 2 "Active" 3 "Ready" 4 "Standby" 5 "TempError" 6 "PermError" ;
VAL_ 785 ElkreLineTrackingLeft 0 "Active" 1 "Ready" 2 "Standby" ;
VAL_ 785 ElkreLineTrackingRight 0 "Active" 1 "Ready" 2 "Standby" ;
VAL_ 785 LdwFeatureStatus 0 "Off" 1 "ON" 2 "Active" 3 "Ready" 4 "Standby" 5 "TempError" 6 "PermError" ;
VAL_ 785 LdwLineTrackingLeft 0 "Active" 1 "Ready" 2 "Standby" ;
VAL_ 785 LdwLineTrackingRight 0 "Active" 1 "Ready" 2 "Standby" ;
VAL_ 785 LksFeatureStatus 0 "Off" 1 "ON" 2 "Active" 3 "Ready" 4 "Standby" 5 "TempError" 6 "PermError" ;
VAL_ 785 LksLineTrackingLeft 0 "Active" 1 "Ready" 2 "Standby" ;
VAL_ 785 LksLineTrackingRight 0 "Active" 1 "Ready" 2 "Standby" ;
VAL_ 785 RdpFeatureStatus 0 "Off" 1 "ON" 2 "Active" 3 "Ready" 4 "Standby" 5 "TempError" 6 "PermError" ;
VAL_ 785 RdpLineTrackingLeft 0 "Active" 1 "Ready" 2 "Standby" ;
VAL_ 785 RdpLineTrackingRight 0 "Active" 1 "Ready" 2 "Standby" ;
VAL_ 769 ElkeStatus 0 "Enabled & Deactivated" 1 "Enabled & Activated" 2 "Disabled" ;
VAL_ 769 ElkoAdjustInterventionTime 0 "Early" 1 "Normal" 2 "Late" 3 "Reserved" ;
VAL_ 769 ElkoAdjustWarningType 0 "Visual" 1 "Acoustic" 2 "Haptic" 3 "Reserved" ;
VAL_ 769 ElkoStatus 0 "Enabled & Deactivated" 1 "Enabled & Activated" 2 "Disabled" ;
VAL_ 769 ElkreAdjustInterventionTime 0 "Early" 1 "Normal" 2 "Late" 3 "Reserved" ;
VAL_ 769 ElkreAdjustWarningType 0 "Visual" 1 "Acoustic" 2 "Haptic" 3 "Reserved" ;
VAL_ 769 FeatureInteraction 0 "No other feature active" 1 "Another feature is active" ;
VAL_ 769 LdwAdjustSensitivity 0 "Light" 1 "Middle" 2 "Strong" 3 "Reserved" ;
VAL_ 769 LdwAdjustWarningTime 0 "Early" 1 "Normal" 2 "Late" 3 "Reserved" ;
VAL_ 769 LdwAdjustWarningType 0 "Visual" 1 "Acoustic" 2 "Haptic" 3 "Reserved" ;
VAL_ 769 LdwStatus 0 "Enabled & Deactivated" 1 "Enabled & Activated" 2 "Disabled" ;
VAL_ 769 LksStatus 0 "Enabled & Deactivated" 1 "Enabled & Activated" 2 "Disabled" ;
VAL_ 769 RdpAdjustSensitivity 0 "Light" 1 "Middle" 2 "Strong" 3 "Reserved" ;
VAL_ 769 RdpAdjustWarningTime 0 "Early" 1 "Normal" 2 "Late" 3 "Reserved" ;
VAL_ 769 RdpAdjustWarningType 0 "Visual" 1 "Acoustic" 2 "Haptic" 3 "Reserved" ;
VAL_ 769 RdpStatus 0 "Enabled & Deactivated" 1 "Enabled & Activated" 2 "Disabled" ;
VAL_ 769 SteeringSystemState 0 "Control blocked" 1 "Control released" 2 "Error" 3 "Reserved" ;
VAL_ 866 TL_suggestedDriveAction 0 "not specified" 1 "driving_allowed" 2 "attention_required" 3 "driving_not_allowed" ;
VAL_ 866 TLF_functionState 0 "FUNCTION_STATUS_PASSIVE" 1 "FUNCTION_STATUS_ACTIVE" 2 "FUNCTION_STATUS_REDUCED_SIGHT" 3 "FUNCTION_STATUS_FAILURE" 14 "FUNCTION_STATUS_INIT" 15 "FUNCTION_STATUS_NOT_AVAILABLE" ;
VAL_ 866 TL_warning 0 "No_Warning" 1 "PreWarning" 2 "AcuteWarning" 3 "TLS_Warning" ;
VAL_ 866 TLF_Mode 0 "not_defined" 1 "TLI" 2 "TLW" 4 "TLB" 8 "TLS" 9 "TLI + TLS" 10 "TLW + TLS" 12 "TLB + TLS" ;
VAL_ 789 ElkoLoadedAdjustInterventionTime 0 "Early" 1 "Normal" 2 "Late" 3 "Reserved" 4 "Reserved" 5 "Reserved" 6 "Reserved" 7 "Reserved" 8 "Reserved" 9 "Reserved" 10 "Reserved" 11 "Reserved" 12 "Reserved" 13 "Reserved" 14 "Reserved" 15 "Reserved" ;
VAL_ 789 ElkoLoadedAdjustWarningType 0 "Visual" 1 "Acoustic" 2 "Haptic" 3 "Reserved" 4 "Reserved" 5 "Reserved" 6 "Reserved" 7 "Reserved" 8 "Reserved" 9 "Reserved" 10 "Reserved" 11 "Reserved" 12 "Reserved" 13 "Reserved" 14 "Reserved" 15 "Reserved" ;
VAL_ 789 ElkreLoadAdjustInterventionTime 0 "Early" 1 "Normal" 2 "Late" 3 "Reserved" 4 "Reserved" 5 "Reserved" 6 "Reserved" 7 "Reserved" 8 "Reserved" 9 "Reserved" 10 "Reserved" 11 "Reserved" 12 "Reserved" 13 "Reserved" 14 "Reserved" 15 "Reserved" ;
VAL_ 789 ElkreLoadedAdjustWarningType 0 "Visual" 1 "Acoustic" 2 "Haptic" 3 "Reserved" 4 "Reserved" 5 "Reserved" 6 "Reserved" 7 "Reserved" 8 "Reserved" 9 "Reserved" 10 "Reserved" 11 "Reserved" 12 "Reserved" 13 "Reserved" 14 "Reserved" 15 "Reserved" ;
VAL_ 789 LdwLoadedAdjustSensitivity 0 "Light" 1 "Middle" 2 "Strong" 3 "Reserved" 4 "Reserved" 5 "Reserved" 6 "Reserved" 7 "Reserved" 8 "Reserved" 9 "Reserved" 10 "Reserved" 11 "Reserved" 12 "Reserved" 13 "Reserved" 14 "Reserved" 15 "Reserved" ;
VAL_ 789 LdwLoadedAdjustWarningTime 0 "Early" 1 "Normal" 2 "Late" 3 "Reserved" 4 "Reserved" 5 "Reserved" 6 "Reserved" 7 "Reserved" 8 "Reserved" 9 "Reserved" 10 "Reserved" 11 "Reserved" 12 "Reserved" 13 "Reserved" 14 "Reserved" 15 "Reserved" ;
VAL_ 789 LdwLoadedAdjustWarningType 0 "Visual" 1 "Acoustic" 2 "Haptic" 3 "Reserved" 4 "Reserved" 5 "Reserved" 6 "Reserved" 7 "Reserved" 8 "Reserved" 9 "Reserved" 10 "Reserved" 11 "Reserved" 12 "Reserved" 13 "Reserved" 14 "Reserved" 15 "Reserved" ;
VAL_ 789 RdpLoadedAdjustSensitivity 0 "Light" 1 "Middle" 2 "Strong" 3 "Reserved" 4 "Reserved" 5 "Reserved" 6 "Reserved" 7 "Reserved" 8 "Reserved" 9 "Reserved" 10 "Reserved" 11 "Reserved" 12 "Reserved" 13 "Reserved" 14 "Reserved" 15 "Reserved" ;
VAL_ 789 RdpLoadedAdjustWarningTime 0 "Early" 1 "Normal" 2 "Late" 3 "Reserved" 4 "Reserved" 5 "Reserved" 6 "Reserved" 7 "Reserved" 8 "Reserved" 9 "Reserved" 10 "Reserved" 11 "Reserved" 12 "Reserved" 13 "Reserved" 14 "Reserved" 15 "Reserved" ;
VAL_ 789 RdpLoadedAdjustWarningType 0 "Visual" 1 "Acoustic" 2 "Haptic" 3 "Reserved" 4 "Reserved" 5 "Reserved" 6 "Reserved" 7 "Reserved" 8 "Reserved" 9 "Reserved" 10 "Reserved" 11 "Reserved" 12 "Reserved" 13 "Reserved" 14 "Reserved" 15 "Reserved" ;
VAL_ 278 ACC_CancelSwitch 0 "ACC CancelSw not pressed" 1 "ACC CancelSw pressed" ;
VAL_ 278 ACC_LimiterSwitch 0 "ACC LimSw not pressed" 1 "ACC LimSw pressed" ;
VAL_ 278 ACC_MainSwitch 0 "ACC MainSw not pressed" 1 "ACC MainSw pressed" ;
VAL_ 278 ACC_ResumeSwitch 0 "ACC ResumeSw not pressed" 1 "ACC ResumeSw pressed" ;
VAL_ 278 ACC_SetSwitch 0 "ACC SetSw not pressed" 1 "ACC SetSw pressed" ;
VAL_ 278 ACC_SwitchFailure 0 "No failure" 1 "Failure" ;
VAL_ 278 ACC_TimegapSwitches 0 "ACC Timegap buttons not pressed" 1 "ACC Timegap minus pressed" 2 "ACC Timegap plus pressed" 3 "ACC Timegap toggle pressed" ;
VAL_ 278 ACC_VSetMinusSwitch 0 "ACC VSetMinus not pressed" 1 "ACC VSetMinus pressed" ;
VAL_ 278 ACC_VSetPlusSwitch 0 "ACC VSetPlus not pressed" 1 "ACC VSetPlus pressed" ;
VAL_ 278 DisplayACCScreenActive 0 "Not active" 1 "Active" ;
VAL_ 278 DisplayConsistentWithACC 0 "ACC Counter consistent" 1 "ACC Counter not consistent" ;
VAL_ 278 DisplayedSpeedUnitType 0 "km/h" 1 "mp/h" ;
VAL_ 278 DisplayFailure 0 "In operation" 1 "Display in failure" ;
VAL_ 278 DriverSeatPositionSensor 0 "Not available" 1 "Failure" 2 "Lean backward" 3 "Lean forward" ;
VAL_ 278 EPB_BrakeForce 30 "Initialization" 31 "Failure" ;
VAL_ 278 EPB_ErrorStatus 0 "No Failure" 1 "Temporary failure level 1" 2 "Temporary failure level 2" 3 "Permanent failure" ;
VAL_ 278 EPB_Status 0 "Brake unlocked" 1 "Brake locked" 2 "Actuator running" 3 "Failure" ;
VAL_ 278 EPB_SwitchPosition 0 "No request" 1 "Open request from driver" 2 "Close request from driver" 3 "Failure" ;
VAL_ 278 EPB_SwitchPosition_Qbit 0 "Normal operation" 1 "Init or failure value" ;
VAL_ 278 NoForwardGear 0 "Gear is in forward position" 1 "Gear is not in forward position" ;
VAL_ 278 ParkingBrakeActive 0 "Parking brake is not active" 1 "Init or failure value" ;
VAL_ 278 RequestedDrivingProgram 0 "No driving program" 1 "Driving Program 1" 2 "Driving Program 2" 3 "Driving Program 3" 4 "Driving Program 4" 5 "Driving Program 5" 6 "Driving Program 6" 7 "Driving Program 7" 8 "Driving Program 8" 9 "Driving Program 9" 10 "Driving Program 10" 11 "Driving Program 11" 12 "Driving Program 12" 13 "Driving Program 13" 14 "Driving Program 14" 15 "Driving Program 15" ;
VAL_ 278 TrailerBrakeLampDefect 0 "No defect" 1 "Trailer brake lamp defect" ;
VAL_ 278 VehicleBrakeLampsDefect 0 "No defect" 1 "Left brake lamp defect" 2 "Right brake lamp defect" 3 "Center brake lamp defect" ;
VAL_ 278 VehicleDoorOpen 0 "All doors are closed" 1 "Driver door opened" 2 "Passanger door opened" 3 "Rear left door opened" 4 "Rear right door opened" ;
VAL_ 1280 ACC_Video_TO01_flagValid 0 "Not valid" 1 "Valid object" ;
VAL_ 1280 ACC_Video_TO01_movingState 0 "Not moving" 1 "Moving object" ;
VAL_ 790 DriverOvertakeRequest 0 "No overtake request" 1 "Overtake request" ;
VAL_ 790 HandsOffWarning 0 "Visual" 1 "Acoustic" 2 "VisualAcoustic" ;
VAL_ 790 HandsOffSafetyAccoustic 0 "NO Warning" 1 "Warning" ;
VAL_ 790 HandsOffComfortOptical 0 "NO Warning" 1 "Warning" ;
VAL_ 790 HandsOffComfortOpticalE 0 "NO Warning" 1 "Warning" ;
VAL_ 790 HandsOffComfortAccoustic 0 "NO Warning" 1 "Warning" ;
VAL_ 790 HandsOffComfortAccousticE 0 "NO Warning" 1 "Warning" ;
VAL_ 279 WheelRotationDirFrontLeft 0 "Forward" 1 "Backward" 2 "Init" 3 "Not equipped" ;
VAL_ 279 WheelRotationDirFrontRight 0 "Forward" 1 "Backward" 2 "Init" 3 "Not equipped" ;
VAL_ 279 WheelRotationDirRearLeft 0 "Forward" 1 "Backward" 2 "Init" 3 "Not equipped" ;
VAL_ 279 WheelRotationDirRearRight 0 "Forward" 1 "Backward" 2 "Init" 3 "Not equipped" ;
VAL_ 833 AutoHighBeamReason 0 "NONE" 1 "ONCOMING_VEHICLE" 2 "PRECEEDING_VEHICLE" 3 "VEL_TOO_LOW" 4 "ROADLIGHTING" 5 "HIGH_BRIGHTNESS" 6 "AMBIENT_BRIGHTNESS" 7 "BLINDNESS" 8 "LOW_BEAM_OFF" 9 "SELF_GLARING" 10 "BAD_WEATHER" 11 "SUPPRESSION" 12 "PASSIVE" 13 "INIT" ;
VAL_ 817 PF_CMRObj01Dist 251 ">500m" 254 "init" 255 "not available" ;
VAL_ 817 PF_CMRObj01HorPosLeft 4094 "init" 4095 "not available" ;
VAL_ 817 PF_CMRObj01HorPosRight 4094 "init" 4095 "not available" ;
VAL_ 817 PF_CMRObj01HorSpeed 254 "init" 255 "not available" ;
VAL_ 817 PF_CMRObj01HorSpeedSign 0 "OBJ_HOR_SPEED_SIGN_LEFT" 1 "OBJ_HOR_SPEED_SIGN_RIGHT" 15 "NOT_AVAILABLE" ;
VAL_ 817 PF_CMRObj01ID 0 "no object detected" 254 "init" 255 "not available" ;
VAL_ 817 PF_CMRObj01Type 0 "no object" 1 "oncoming object, headlamps detected" 2 "preceding object, rear lamps detected" 3 "reflective object, low reflection detected" 4 "reflective object, mid reflection detected" 5 "reflective object, high reflection detected" 6 "reflective object, low minus reflection detected" 7 "reflective object, low plus reflection detected" 8 "reflective object, mid minus reflection detected" 9 "reflective object, mid plus reflection detected" 10 "reflective object, high minus reflection detected" 11 "reflective object, high plus reflection detected" 14 "Init" 15 "not available" ;
VAL_ 817 PF_CMRObj01VerPos 254 "init" 255 "not available" ;
VAL_ 818 PF_CMRObj02Dist 251 ">500m" 254 "init" 255 "not available" ;
VAL_ 818 PF_CMRObj02HorPosLeft 4094 "init" 4095 "not available" ;
VAL_ 818 PF_CMRObj02HorPosRight 4094 "init" 4095 "not available" ;
VAL_ 818 PF_CMRObj02HorSpeed 254 "init" 255 "not available" ;
VAL_ 818 PF_CMRObj02HorSpeedSign 0 "OBJ_HOR_SPEED_SIGN_LEFT" 1 "OBJ_HOR_SPEED_SIGN_RIGHT" 15 "NOT_AVAILABLE" ;
VAL_ 818 PF_CMRObj02ID 0 "no object detected" 254 "init" 255 "not available" ;
VAL_ 818 PF_CMRObj02Type 0 "no object" 1 "oncoming object, headlamps detected" 2 "preceding object, rear lamps detected" 3 "reflective object, low reflection detected" 4 "reflective object, mid reflection detected" 5 "reflective object, high reflection detected" 6 "reflective object, low minus reflection detected" 7 "reflective object, low plus reflection detected" 8 "reflective object, mid minus reflection detected" 9 "reflective object, mid plus reflection detected" 10 "reflective object, high minus reflection detected" 11 "reflective object, high plus reflection detected" 14 "Init" 15 "not available" ;
VAL_ 818 PF_CMRObj02VerPos 254 "init" 255 "not available" ;
VAL_ 819 PF_CMRObj03Dist 251 ">500m" 254 "init" 255 "not available" ;
VAL_ 819 PF_CMRObj03HorPosLeft 4094 "init" 4095 "not available" ;
VAL_ 819 PF_CMRObj03HorPosRight 4094 "init" 4095 "not available" ;
VAL_ 819 PF_CMRObj03HorSpeed 254 "init" 255 "not available" ;
VAL_ 819 PF_CMRObj03HorSpeedSign 0 "OBJ_HOR_SPEED_SIGN_LEFT" 1 "OBJ_HOR_SPEED_SIGN_RIGHT" 15 "NOT_AVAILABLE" ;
VAL_ 819 PF_CMRObj03ID 0 "no object detected" 254 "init" 255 "not available" ;
VAL_ 819 PF_CMRObj03Type 0 "no object" 1 "oncoming object, headlamps detected" 2 "preceding object, rear lamps detected" 3 "reflective object, low reflection detected" 4 "reflective object, mid reflection detected" 5 "reflective object, high reflection detected" 6 "reflective object, low minus reflection detected" 7 "reflective object, low plus reflection detected" 8 "reflective object, mid minus reflection detected" 9 "reflective object, mid plus reflection detected" 10 "reflective object, high minus reflection detected" 11 "reflective object, high plus reflection detected" 14 "Init" 15 "not available" ;
VAL_ 819 PF_CMRObj03VerPos 254 "init" 255 "not available" ;
VAL_ 820 PF_CMRObj04Dist 251 ">500m" 254 "init" 255 "not available" ;
VAL_ 820 PF_CMRObj04HorPosLeft 4094 "init" 4095 "not available" ;
VAL_ 820 PF_CMRObj04HorPosRight 4094 "init" 4095 "not available" ;
VAL_ 820 PF_CMRObj04HorSpeed 254 "init" 255 "not available" ;
VAL_ 820 PF_CMRObj04HorSpeedSign 0 "OBJ_HOR_SPEED_SIGN_LEFT" 1 "OBJ_HOR_SPEED_SIGN_RIGHT" 15 "NOT_AVAILABLE" ;
VAL_ 820 PF_CMRObj04ID 0 "no object detected" 254 "init" 255 "not available" ;
VAL_ 820 PF_CMRObj04Type 0 "no object" 1 "oncoming object, headlamps detected" 2 "preceding object, rear lamps detected" 3 "reflective object, low reflection detected" 4 "reflective object, mid reflection detected" 5 "reflective object, high reflection detected" 6 "reflective object, low minus reflection detected" 7 "reflective object, low plus reflection detected" 8 "reflective object, mid minus reflection detected" 9 "reflective object, mid plus reflection detected" 10 "reflective object, high minus reflection detected" 11 "reflective object, high plus reflection detected" 14 "Init" 15 "not available" ;
VAL_ 820 PF_CMRObj04VerPos 254 "init" 255 "not available" ;
VAL_ 821 PF_CMRObj05HorSpeed 254 "init" 255 "not available" ;
VAL_ 821 PF_CMRObj05VerPos 254 "init" 255 "not available" ;
VAL_ 821 PF_CMRObj05ID 0 "no object detected" 254 "init" 255 "not available" ;
VAL_ 821 PF_CMRObj05HorPosRight 4094 "init" 4095 "not available" ;
VAL_ 821 PF_CMRObj05HorSpeedSign 0 "OBJ_HOR_SPEED_SIGN_LEFT" 1 "OBJ_HOR_SPEED_SIGN_RIGHT" 15 "NOT_AVAILABLE" ;
VAL_ 821 PF_CMRObj05HorPosLeft 4094 "init" 4095 "not available" ;
VAL_ 821 PF_CMRObj05Type 0 "no object" 1 "oncoming object, headlamps detected" 2 "preceding object, rear lamps detected" 3 "reflective object, low reflection detected" 4 "reflective object, mid reflection detected" 5 "reflective object, high reflection detected" 6 "reflective object, low minus reflection detected" 7 "reflective object, low plus reflection detected" 8 "reflective object, mid minus reflection detected" 9 "reflective object, mid plus reflection detected" 10 "reflective object, high minus reflection detected" 11 "reflective object, high plus reflection detected" 14 "Init" 15 "not available" ;
VAL_ 821 PF_CMRObj05Dist 251 ">500m" 254 "init" 255 "not available" ;
VAL_ 823 PF_CMRObj07HorSpeed 254 "init" 255 "not available" ;
VAL_ 823 PF_CMRObj07VerPos 254 "init" 255 "not available" ;
VAL_ 823 PF_CMRObj07ID 0 "no object detected" 254 "init" 255 "not available" ;
VAL_ 823 PF_CMRObj07HorPosRight 4094 "init" 4095 "not available" ;
VAL_ 823 PF_CMRObj07HorSpeedSign 0 "OBJ_HOR_SPEED_SIGN_LEFT" 1 "OBJ_HOR_SPEED_SIGN_RIGHT" 15 "NOT_AVAILABLE" ;
VAL_ 823 PF_CMRObj07HorPosLeft 4094 "init" 4095 "not available" ;
VAL_ 823 PF_CMRObj07Type 0 "no object" 1 "oncoming object, headlamps detected" 2 "preceding object, rear lamps detected" 3 "reflective object, low reflection detected" 4 "reflective object, mid reflection detected" 5 "reflective object, high reflection detected" 6 "reflective object, low minus reflection detected" 7 "reflective object, low plus reflection detected" 8 "reflective object, mid minus reflection detected" 9 "reflective object, mid plus reflection detected" 10 "reflective object, high minus reflection detected" 11 "reflective object, high plus reflection detected" 14 "Init" 15 "not available" ;
VAL_ 823 PF_CMRObj07Dist 251 ">500m" 254 "init" 255 "not available" ;
VAL_ 824 PF_CMRObj08HorSpeed 254 "init" 255 "not available" ;
VAL_ 824 PF_CMRObj08VerPos 254 "init" 255 "not available" ;
VAL_ 824 PF_CMRObj08ID 0 "no object detected" 254 "init" 255 "not available" ;
VAL_ 824 PF_CMRObj08HorPosRight 4094 "init" 4095 "not available" ;
VAL_ 824 PF_CMRObj08HorSpeedSign 0 "OBJ_HOR_SPEED_SIGN_LEFT" 1 "OBJ_HOR_SPEED_SIGN_RIGHT" 15 "NOT_AVAILABLE" ;
VAL_ 824 PF_CMRObj08HorPosLeft 4094 "init" 4095 "not available" ;
VAL_ 824 PF_CMRObj08Type 0 "no object" 1 "oncoming object, headlamps detected" 2 "preceding object, rear lamps detected" 3 "reflective object, low reflection detected" 4 "reflective object, mid reflection detected" 5 "reflective object, high reflection detected" 6 "reflective object, low minus reflection detected" 7 "reflective object, low plus reflection detected" 8 "reflective object, mid minus reflection detected" 9 "reflective object, mid plus reflection detected" 10 "reflective object, high minus reflection detected" 11 "reflective object, high plus reflection detected" 14 "Init" 15 "not available" ;
VAL_ 824 PF_CMRObj08Dist 251 ">500m" 254 "init" 255 "not available" ;
VAL_ 825 PF_CMRObj09HorSpeed 254 "init" 255 "not available" ;
VAL_ 825 PF_CMRObj09VerPos 254 "init" 255 "not available" ;
VAL_ 825 PF_CMRObj09ID 0 "no object detected" 254 "init" 255 "not available" ;
VAL_ 825 PF_CMRObj09HorPosRight 4094 "init" 4095 "not available" ;
VAL_ 825 PF_CMRObj09HorSpeedSign 0 "OBJ_HOR_SPEED_SIGN_LEFT" 1 "OBJ_HOR_SPEED_SIGN_RIGHT" 15 "NOT_AVAILABLE" ;
VAL_ 825 PF_CMRObj09HorPosLeft 4094 "init" 4095 "not available" ;
VAL_ 825 PF_CMRObj09Type 0 "no object" 1 "oncoming object, headlamps detected" 2 "preceding object, rear lamps detected" 3 "reflective object, low reflection detected" 4 "reflective object, mid reflection detected" 5 "reflective object, high reflection detected" 6 "reflective object, low minus reflection detected" 7 "reflective object, low plus reflection detected" 8 "reflective object, mid minus reflection detected" 9 "reflective object, mid plus reflection detected" 10 "reflective object, high minus reflection detected" 11 "reflective object, high plus reflection detected" 14 "Init" 15 "not available" ;
VAL_ 825 PF_CMRObj09Dist 251 ">500m" 254 "init" 255 "not available" ;
VAL_ 822 PF_CMRObj06HorSpeed 254 "init" 255 "not available" ;
VAL_ 822 PF_CMRObj06VerPos 254 "init" 255 "not available" ;
VAL_ 822 PF_CMRObj06ID 0 "no object detected" 254 "init" 255 "not available" ;
VAL_ 822 PF_CMRObj06HorPosRight 4094 "init" 4095 "not available" ;
VAL_ 822 PF_CMRObj06HorSpeedSign 0 "OBJ_HOR_SPEED_SIGN_LEFT" 1 "OBJ_HOR_SPEED_SIGN_RIGHT" 15 "NOT_AVAILABLE" ;
VAL_ 822 PF_CMRObj06HorPosLeft 4094 "init" 4095 "not available" ;
VAL_ 822 PF_CMRObj06Type 0 "no object" 1 "oncoming object, headlamps detected" 2 "preceding object, rear lamps detected" 3 "reflective object, low reflection detected" 4 "reflective object, mid reflection detected" 5 "reflective object, high reflection detected" 6 "reflective object, low minus reflection detected" 7 "reflective object, low plus reflection detected" 8 "reflective object, mid minus reflection detected" 9 "reflective object, mid plus reflection detected" 10 "reflective object, high minus reflection detected" 11 "reflective object, high plus reflection detected" 14 "Init" 15 "not available" ;
SIG_GROUP_ 446 FLCGlobalHeader 1 : CameraStatus;
SIG_GROUP_ 17 DSC_SBW_SIGNALS 1 : ABSAliveCounter ABSChecksum ABSEngVacReq ABSPwrTrnTorqReq BrakePressure BrakePressureQF VehicleSpeed VehicleSpeedQF;
SIG_GROUP_ 268 VehMovement 1 : VehMovementChecksum VehMovementCounter VehMovementDirection VehMovementStatus WheelDirectionFL WheelDirectionFR WheelDirectionRL WheelDirectionRR;
SIG_GROUP_ 237 WheelSpeedFrGp 1 : WheelSpeedFrGpCounter WheelSpeedFrGpCS WheelSpeedFrL WheelSpeedFrLQF WheelSpeedFrR WheelSpeedFrRQF;
SIG_GROUP_ 240 WheelSpeedReGp 1 : WheelSpeedReGpCounter WheelSpeedReGpCS WheelSpeedReL WheelSpeedReLQF WheelSpeedReR WheelSpeedReRQF;
SIG_GROUP_ 253 RWS_DADC_GP1 1 : RWSAngleDmd RWSAngleDmdPDC RWSFaultAngle RWSFaultStraight RWSLinRngeAngleDmd RWSMotTypeServeLat RWSMotTypeServeLong RWSMotTypeServeLvl RWSMotTypeServeMode RWSSysAliveCnt1 RWSSysCS1;
SIG_GROUP_ 254 RWS_DADC_GP2 1 : DADCRWSAngleReq DrvLimRWSAct RWSAngleAct RWSStrkeDmd RWSSysAliveCnt2 RWSSysCS2 RWSSysStats RWSTerrainModeExt RWSTerrChngModeStatus RWSTRConfig;
SIG_GROUP_ 439 NavData2Gp 1 : DisttoNextJunct InBuiltArea;
SIG_GROUP_ 439 NavDataGp 1 : NavCountryCode NavCurrRoadType;
SIG_GROUP_ 439 NavData2Gp 1 : NavCurrState;
SIG_GROUP_ 439 NavDataGp 1 : NavSpdLimit NavSpdLimitStatus NavSpdLimitUnits;
SIG_GROUP_ 439 NavData2Gp 1 : NumberofExitLanes NumberofLanes RightOfWay;
SIG_GROUP_ 132 ECM_SBW_SIGNALS 1 : BrakeSwitchStatus EMSAliveCounter EMSChecksum EngineSpeed EngineSpeedQF MHStopStartStatus PowerPackStatus;
SIG_GROUP_ 54 PedalPosProGrp 1 : PedalPosPro PedalPosProAliveCounter PedalPosProChecksum PedalPosProQF;
SIG_GROUP_ 13 WheelTorqTgtGp 1 : VSCHoldRequest WheelTorqTgtGpCounter WheelTorqTgtGpCS WheelTorqTgtWoIntF WheelTorqTgtWoIntR;
SIG_GROUP_ 46 TorsionBarTorqueGrp 1 : EPASDrvDmdExcess_dup TorsionBarTorque TorsionBarTorqueCS TorsionBarTorqueCtr TorsionBarTorqueQF TorsionBarTorqueSign;
SIG_GROUP_ 50 ActRoadWheelAnglegp 1 : ActRoadWheelAngleAC ActRoadWheelAngleCS ActRoadWheelAngState ActRoadWheelAngValue;
SIG_GROUP_ 74 TX_ID1 1 : A1 A1_STAT CLU_STAT CRC1 MSG_CNT1 PSIP1 PSIP1_STAT;
SIG_GROUP_ 76 TX_ID2 1 : A2 A2_STAT CRC2 MSG_CNT2 PSIPP1 PSIPP1_STAT;
SIG_GROUP_ 86 SteeringWheelGp 1 : SteeringWheelAngle SteeringWheelAngleCS SteeringWheelAngleSpeed SteeringWheelAngleStatus SteeringWheelAngMsgCnt SteeringWheelRotDir;
SIG_GROUP_ 80 TCM_SBW_SignalsGp 1 : KeepNetInAfterRunTCM TCMLockETSReq TCMParkReqAck TCMPosAliveCounter TCMPosChecksum TCMPositionDisplay TCMStartEnable TCMText TransTICStatus;
SIG_GROUP_ 1024 CCFPayload0xB0 1 : CcfDD06PowerModePKT;
SIG_GROUP_ 1024 CCFPayload0xB1 1 : CcfDD05OutdoorTemp;
SIG_GROUP_ 1024 CCFPayload0xB0 1 : CcfDD02MainECUSupVolts;
SIG_GROUP_ 1024 CCFPayload0xB1 1 : CcfDD04InCarTemp CcfDD01TotalDistance;
SIG_GROUP_ 1024 CCFPayload0xB0 1 : CcfDD00GlobalRealTime;
